VERSION "dbc-export 1 2026.26.6.5"

NS_ :

BS_:

BU_: APB APP APS DAS EPAS3S ESP GTW IBST PARK RADC RCM RCM2 RCM3 TPMS TRCM USM

BO_ 1486 PARK_alertLog: 8 PARK
 SG_ PARK_alertID M : 0|7@1+ (1,0) [0|127] "" Vector__XXX
 SG_ PARK_alertState : 15|1@1+ (1,0) [0|1] "" Vector__XXX
 SG_ PARK_sw001_sensorTemperature m1 : 16|16@1+ (0.1,-40) [-40|6513.5] "deg" Vector__XXX
 SG_ PARK_sw002_membraneDisconct m2 : 16|1@1+ (1,0) [0|1] "" Vector__XXX
 SG_ PARK_sw002_dampResistorFail m2 : 17|1@1+ (1,0) [0|1] "" Vector__XXX
 SG_ PARK_sw002_resonanceDrift m2 : 18|1@1+ (1,0) [0|1] "" Vector__XXX
 SG_ PARK_sw002_sensorCRC m2 : 19|1@1+ (1,0) [0|1] "" Vector__XXX
 SG_ PARK_sw002_recieveFailure m2 : 20|1@1+ (1,0) [0|1] "" Vector__XXX
 SG_ PARK_sw002_diagnosticTransferErr m2 : 21|1@1+ (1,0) [0|1] "" Vector__XXX
 SG_ PARK_sw003_linError m3 : 16|1@1+ (1,0) [0|1] "" Vector__XXX
 SG_ PARK_sw003_linBusError m3 : 17|1@1+ (1,0) [0|1] "" Vector__XXX
 SG_ PARK_sw003_linFrameCountError m3 : 18|1@1+ (1,0) [0|1] "" Vector__XXX
 SG_ PARK_sw004_reverbPeriod m4 : 16|16@1+ (1,0) [0|65535] "microseconds" Vector__XXX
 SG_ PARK_sw004_reverbTime m4 : 32|16@1+ (1,0) [0|65535] "microseconds" Vector__XXX
 SG_ PARK_sw004_highAttenTime m4 : 48|1@1+ (1,0) [0|1] "" Vector__XXX
 SG_ PARK_sw004_closeConstEcho m4 : 49|1@1+ (1,0) [0|1] "" Vector__XXX
 SG_ PARK_sw004_lowAttenTime m4 : 50|1@1+ (1,0) [0|1] "" Vector__XXX
 SG_ PARK_sw004_attenTimeJitter m4 : 51|1@1+ (1,0) [0|1] "" Vector__XXX
 SG_ PARK_sw004_reverbFreqJitter m4 : 52|1@1+ (1,0) [0|1] "" Vector__XXX
 SG_ PARK_sw006_sensorTemperature m6 : 16|16@1+ (0.1,-40) [-40|6513.5] "deg" Vector__XXX
 SG_ PARK_sw007_membraneDisconct m7 : 16|1@1+ (1,0) [0|1] "" Vector__XXX
 SG_ PARK_sw007_dampResistorFail m7 : 17|1@1+ (1,0) [0|1] "" Vector__XXX
 SG_ PARK_sw007_resonanceDrift m7 : 18|1@1+ (1,0) [0|1] "" Vector__XXX
 SG_ PARK_sw007_sensorCRC m7 : 19|1@1+ (1,0) [0|1] "" Vector__XXX
 SG_ PARK_sw007_recieveFailure m7 : 20|1@1+ (1,0) [0|1] "" Vector__XXX
 SG_ PARK_sw007_diagnosticTransferErr m7 : 21|1@1+ (1,0) [0|1] "" Vector__XXX
 SG_ PARK_sw008_linError m8 : 16|1@1+ (1,0) [0|1] "" Vector__XXX
 SG_ PARK_sw008_linBusError m8 : 17|1@1+ (1,0) [0|1] "" Vector__XXX
 SG_ PARK_sw008_linFrameCountError m8 : 18|1@1+ (1,0) [0|1] "" Vector__XXX
 SG_ PARK_sw009_reverbPeriod m9 : 16|16@1+ (1,0) [0|65535] "microseconds" Vector__XXX
 SG_ PARK_sw009_reverbTime m9 : 32|16@1+ (1,0) [0|65535] "microseconds" Vector__XXX
 SG_ PARK_sw009_highAttenTime m9 : 48|1@1+ (1,0) [0|1] "" Vector__XXX
 SG_ PARK_sw009_closeConstEcho m9 : 49|1@1+ (1,0) [0|1] "" Vector__XXX
 SG_ PARK_sw009_lowAttenTime m9 : 50|1@1+ (1,0) [0|1] "" Vector__XXX
 SG_ PARK_sw009_attenTimeJitter m9 : 51|1@1+ (1,0) [0|1] "" Vector__XXX
 SG_ PARK_sw009_reverbFreqJitter m9 : 52|1@1+ (1,0) [0|1] "" Vector__XXX
 SG_ PARK_sw011_sensorTemperature m11 : 16|16@1+ (0.1,-40) [-40|6513.5] "deg" Vector__XXX
 SG_ PARK_sw012_membraneDisconct m12 : 16|1@1+ (1,0) [0|1] "" Vector__XXX
 SG_ PARK_sw012_dampResistorFail m12 : 17|1@1+ (1,0) [0|1] "" Vector__XXX
 SG_ PARK_sw012_resonanceDrift m12 : 18|1@1+ (1,0) [0|1] "" Vector__XXX
 SG_ PARK_sw012_sensorCRC m12 : 19|1@1+ (1,0) [0|1] "" Vector__XXX
 SG_ PARK_sw012_recieveFailure m12 : 20|1@1+ (1,0) [0|1] "" Vector__XXX
 SG_ PARK_sw012_diagnosticTransferErr m12 : 21|1@1+ (1,0) [0|1] "" Vector__XXX
 SG_ PARK_sw013_linError m13 : 16|1@1+ (1,0) [0|1] "" Vector__XXX
 SG_ PARK_sw013_linBusError m13 : 17|1@1+ (1,0) [0|1] "" Vector__XXX
 SG_ PARK_sw013_linFrameCountError m13 : 18|1@1+ (1,0) [0|1] "" Vector__XXX
 SG_ PARK_sw014_reverbPeriod m14 : 16|16@1+ (1,0) [0|65535] "microseconds" Vector__XXX
 SG_ PARK_sw014_reverbTime m14 : 32|16@1+ (1,0) [0|65535] "microseconds" Vector__XXX
 SG_ PARK_sw014_highAttenTime m14 : 48|1@1+ (1,0) [0|1] "" Vector__XXX
 SG_ PARK_sw014_closeConstEcho m14 : 49|1@1+ (1,0) [0|1] "" Vector__XXX
 SG_ PARK_sw014_lowAttenTime m14 : 50|1@1+ (1,0) [0|1] "" Vector__XXX
 SG_ PARK_sw014_attenTimeJitter m14 : 51|1@1+ (1,0) [0|1] "" Vector__XXX
 SG_ PARK_sw014_reverbFreqJitter m14 : 52|1@1+ (1,0) [0|1] "" Vector__XXX
 SG_ PARK_sw016_sensorTemperature m16 : 16|16@1+ (0.1,-40) [-40|6513.5] "deg" Vector__XXX
 SG_ PARK_sw017_membraneDisconct m17 : 16|1@1+ (1,0) [0|1] "" Vector__XXX
 SG_ PARK_sw017_dampResistorFail m17 : 17|1@1+ (1,0) [0|1] "" Vector__XXX
 SG_ PARK_sw017_resonanceDrift m17 : 18|1@1+ (1,0) [0|1] "" Vector__XXX
 SG_ PARK_sw017_sensorCRC m17 : 19|1@1+ (1,0) [0|1] "" Vector__XXX
 SG_ PARK_sw017_recieveFailure m17 : 20|1@1+ (1,0) [0|1] "" Vector__XXX
 SG_ PARK_sw017_diagnosticTransferErr m17 : 21|1@1+ (1,0) [0|1] "" Vector__XXX
 SG_ PARK_sw018_linError m18 : 16|1@1+ (1,0) [0|1] "" Vector__XXX
 SG_ PARK_sw018_linBusError m18 : 17|1@1+ (1,0) [0|1] "" Vector__XXX
 SG_ PARK_sw018_linFrameCountError m18 : 18|1@1+ (1,0) [0|1] "" Vector__XXX
 SG_ PARK_sw019_reverbPeriod m19 : 16|16@1+ (1,0) [0|65535] "microseconds" Vector__XXX
 SG_ PARK_sw019_reverbTime m19 : 32|16@1+ (1,0) [0|65535] "microseconds" Vector__XXX
 SG_ PARK_sw019_highAttenTime m19 : 48|1@1+ (1,0) [0|1] "" Vector__XXX
 SG_ PARK_sw019_closeConstEcho m19 : 49|1@1+ (1,0) [0|1] "" Vector__XXX
 SG_ PARK_sw019_lowAttenTime m19 : 50|1@1+ (1,0) [0|1] "" Vector__XXX
 SG_ PARK_sw019_attenTimeJitter m19 : 51|1@1+ (1,0) [0|1] "" Vector__XXX
 SG_ PARK_sw019_reverbFreqJitter m19 : 52|1@1+ (1,0) [0|1] "" Vector__XXX
 SG_ PARK_sw021_sensorTemperature m21 : 16|16@1+ (0.1,-40) [-40|6513.5] "deg" Vector__XXX
 SG_ PARK_sw022_membraneDisconct m22 : 16|1@1+ (1,0) [0|1] "" Vector__XXX
 SG_ PARK_sw022_dampResistorFail m22 : 17|1@1+ (1,0) [0|1] "" Vector__XXX
 SG_ PARK_sw022_resonanceDrift m22 : 18|1@1+ (1,0) [0|1] "" Vector__XXX
 SG_ PARK_sw022_sensorCRC m22 : 19|1@1+ (1,0) [0|1] "" Vector__XXX
 SG_ PARK_sw022_recieveFailure m22 : 20|1@1+ (1,0) [0|1] "" Vector__XXX
 SG_ PARK_sw022_diagnosticTransferErr m22 : 21|1@1+ (1,0) [0|1] "" Vector__XXX
 SG_ PARK_sw023_linError m23 : 16|1@1+ (1,0) [0|1] "" Vector__XXX
 SG_ PARK_sw023_linBusError m23 : 17|1@1+ (1,0) [0|1] "" Vector__XXX
 SG_ PARK_sw023_linFrameCountError m23 : 18|1@1+ (1,0) [0|1] "" Vector__XXX
 SG_ PARK_sw024_reverbPeriod m24 : 16|16@1+ (1,0) [0|65535] "microseconds" Vector__XXX
 SG_ PARK_sw024_reverbTime m24 : 32|16@1+ (1,0) [0|65535] "microseconds" Vector__XXX
 SG_ PARK_sw024_highAttenTime m24 : 48|1@1+ (1,0) [0|1] "" Vector__XXX
 SG_ PARK_sw024_closeConstEcho m24 : 49|1@1+ (1,0) [0|1] "" Vector__XXX
 SG_ PARK_sw024_lowAttenTime m24 : 50|1@1+ (1,0) [0|1] "" Vector__XXX
 SG_ PARK_sw024_attenTimeJitter m24 : 51|1@1+ (1,0) [0|1] "" Vector__XXX
 SG_ PARK_sw024_reverbFreqJitter m24 : 52|1@1+ (1,0) [0|1] "" Vector__XXX
 SG_ PARK_sw026_sensorTemperature m26 : 16|16@1+ (0.1,-40) [-40|6513.5] "deg" Vector__XXX
 SG_ PARK_sw027_membraneDisconct m27 : 16|1@1+ (1,0) [0|1] "" Vector__XXX
 SG_ PARK_sw027_dampResistorFail m27 : 17|1@1+ (1,0) [0|1] "" Vector__XXX
 SG_ PARK_sw027_resonanceDrift m27 : 18|1@1+ (1,0) [0|1] "" Vector__XXX
 SG_ PARK_sw027_sensorCRC m27 : 19|1@1+ (1,0) [0|1] "" Vector__XXX
 SG_ PARK_sw027_recieveFailure m27 : 20|1@1+ (1,0) [0|1] "" Vector__XXX
 SG_ PARK_sw027_diagnosticTransferErr m27 : 21|1@1+ (1,0) [0|1] "" Vector__XXX
 SG_ PARK_sw028_linError m28 : 16|1@1+ (1,0) [0|1] "" Vector__XXX
 SG_ PARK_sw028_linBusError m28 : 17|1@1+ (1,0) [0|1] "" Vector__XXX
 SG_ PARK_sw028_linFrameCountError m28 : 18|1@1+ (1,0) [0|1] "" Vector__XXX
 SG_ PARK_sw029_reverbPeriod m29 : 16|16@1+ (1,0) [0|65535] "microseconds" Vector__XXX
 SG_ PARK_sw029_reverbTime m29 : 32|16@1+ (1,0) [0|65535] "microseconds" Vector__XXX
 SG_ PARK_sw029_highAttenTime m29 : 48|1@1+ (1,0) [0|1] "" Vector__XXX
 SG_ PARK_sw029_closeConstEcho m29 : 49|1@1+ (1,0) [0|1] "" Vector__XXX
 SG_ PARK_sw029_lowAttenTime m29 : 50|1@1+ (1,0) [0|1] "" Vector__XXX
 SG_ PARK_sw029_attenTimeJitter m29 : 51|1@1+ (1,0) [0|1] "" Vector__XXX
 SG_ PARK_sw029_reverbFreqJitter m29 : 52|1@1+ (1,0) [0|1] "" Vector__XXX
 SG_ PARK_sw031_sensorTemperature m31 : 16|16@1+ (0.1,-40) [-40|6513.5] "deg" Vector__XXX
 SG_ PARK_sw032_membraneDisconct m32 : 16|1@1+ (1,0) [0|1] "" Vector__XXX
 SG_ PARK_sw032_dampResistorFail m32 : 17|1@1+ (1,0) [0|1] "" Vector__XXX
 SG_ PARK_sw032_resonanceDrift m32 : 18|1@1+ (1,0) [0|1] "" Vector__XXX
 SG_ PARK_sw032_sensorCRC m32 : 19|1@1+ (1,0) [0|1] "" Vector__XXX
 SG_ PARK_sw032_recieveFailure m32 : 20|1@1+ (1,0) [0|1] "" Vector__XXX
 SG_ PARK_sw032_diagnosticTransferErr m32 : 21|1@1+ (1,0) [0|1] "" Vector__XXX
 SG_ PARK_sw033_linError m33 : 16|1@1+ (1,0) [0|1] "" Vector__XXX
 SG_ PARK_sw033_linBusError m33 : 17|1@1+ (1,0) [0|1] "" Vector__XXX
 SG_ PARK_sw033_linFrameCountError m33 : 18|1@1+ (1,0) [0|1] "" Vector__XXX
 SG_ PARK_sw034_reverbPeriod m34 : 16|16@1+ (1,0) [0|65535] "microseconds" Vector__XXX
 SG_ PARK_sw034_reverbTime m34 : 32|16@1+ (1,0) [0|65535] "microseconds" Vector__XXX
 SG_ PARK_sw034_highAttenTime m34 : 48|1@1+ (1,0) [0|1] "" Vector__XXX
 SG_ PARK_sw034_closeConstEcho m34 : 49|1@1+ (1,0) [0|1] "" Vector__XXX
 SG_ PARK_sw034_lowAttenTime m34 : 50|1@1+ (1,0) [0|1] "" Vector__XXX
 SG_ PARK_sw034_attenTimeJitter m34 : 51|1@1+ (1,0) [0|1] "" Vector__XXX
 SG_ PARK_sw034_reverbFreqJitter m34 : 52|1@1+ (1,0) [0|1] "" Vector__XXX
 SG_ PARK_sw036_sensorTemperature m36 : 16|16@1+ (0.1,-40) [-40|6513.5] "deg" Vector__XXX
 SG_ PARK_sw037_membraneDisconct m37 : 16|1@1+ (1,0) [0|1] "" Vector__XXX
 SG_ PARK_sw037_dampResistorFail m37 : 17|1@1+ (1,0) [0|1] "" Vector__XXX
 SG_ PARK_sw037_resonanceDrift m37 : 18|1@1+ (1,0) [0|1] "" Vector__XXX
 SG_ PARK_sw037_sensorCRC m37 : 19|1@1+ (1,0) [0|1] "" Vector__XXX
 SG_ PARK_sw037_recieveFailure m37 : 20|1@1+ (1,0) [0|1] "" Vector__XXX
 SG_ PARK_sw037_diagnosticTransferErr m37 : 21|1@1+ (1,0) [0|1] "" Vector__XXX
 SG_ PARK_sw038_linError m38 : 16|1@1+ (1,0) [0|1] "" Vector__XXX
 SG_ PARK_sw038_linBusError m38 : 17|1@1+ (1,0) [0|1] "" Vector__XXX
 SG_ PARK_sw038_linFrameCountError m38 : 18|1@1+ (1,0) [0|1] "" Vector__XXX
 SG_ PARK_sw039_reverbPeriod m39 : 16|16@1+ (1,0) [0|65535] "microseconds" Vector__XXX
 SG_ PARK_sw039_reverbTime m39 : 32|16@1+ (1,0) [0|65535] "microseconds" Vector__XXX
 SG_ PARK_sw039_highAttenTime m39 : 48|1@1+ (1,0) [0|1] "" Vector__XXX
 SG_ PARK_sw039_closeConstEcho m39 : 49|1@1+ (1,0) [0|1] "" Vector__XXX
 SG_ PARK_sw039_lowAttenTime m39 : 50|1@1+ (1,0) [0|1] "" Vector__XXX
 SG_ PARK_sw039_attenTimeJitter m39 : 51|1@1+ (1,0) [0|1] "" Vector__XXX
 SG_ PARK_sw039_reverbFreqJitter m39 : 52|1@1+ (1,0) [0|1] "" Vector__XXX
 SG_ PARK_sw041_sensorTemperature m41 : 16|16@1+ (0.1,-40) [-40|6513.5] "deg" Vector__XXX
 SG_ PARK_sw042_membraneDisconct m42 : 16|1@1+ (1,0) [0|1] "" Vector__XXX
 SG_ PARK_sw042_dampResistorFail m42 : 17|1@1+ (1,0) [0|1] "" Vector__XXX
 SG_ PARK_sw042_resonanceDrift m42 : 18|1@1+ (1,0) [0|1] "" Vector__XXX
 SG_ PARK_sw042_sensorCRC m42 : 19|1@1+ (1,0) [0|1] "" Vector__XXX
 SG_ PARK_sw042_recieveFailure m42 : 20|1@1+ (1,0) [0|1] "" Vector__XXX
 SG_ PARK_sw042_diagnosticTransferErr m42 : 21|1@1+ (1,0) [0|1] "" Vector__XXX
 SG_ PARK_sw043_linError m43 : 16|1@1+ (1,0) [0|1] "" Vector__XXX
 SG_ PARK_sw043_linBusError m43 : 17|1@1+ (1,0) [0|1] "" Vector__XXX
 SG_ PARK_sw043_linFrameCountError m43 : 18|1@1+ (1,0) [0|1] "" Vector__XXX
 SG_ PARK_sw044_reverbPeriod m44 : 16|16@1+ (1,0) [0|65535] "microseconds" Vector__XXX
 SG_ PARK_sw044_reverbTime m44 : 32|16@1+ (1,0) [0|65535] "microseconds" Vector__XXX
 SG_ PARK_sw044_highAttenTime m44 : 48|1@1+ (1,0) [0|1] "" Vector__XXX
 SG_ PARK_sw044_closeConstEcho m44 : 49|1@1+ (1,0) [0|1] "" Vector__XXX
 SG_ PARK_sw044_lowAttenTime m44 : 50|1@1+ (1,0) [0|1] "" Vector__XXX
 SG_ PARK_sw044_attenTimeJitter m44 : 51|1@1+ (1,0) [0|1] "" Vector__XXX
 SG_ PARK_sw044_reverbFreqJitter m44 : 52|1@1+ (1,0) [0|1] "" Vector__XXX
 SG_ PARK_sw046_sensorTemperature m46 : 16|16@1+ (0.1,-40) [-40|6513.5] "deg" Vector__XXX
 SG_ PARK_sw047_membraneDisconct m47 : 16|1@1+ (1,0) [0|1] "" Vector__XXX
 SG_ PARK_sw047_dampResistorFail m47 : 17|1@1+ (1,0) [0|1] "" Vector__XXX
 SG_ PARK_sw047_resonanceDrift m47 : 18|1@1+ (1,0) [0|1] "" Vector__XXX
 SG_ PARK_sw047_sensorCRC m47 : 19|1@1+ (1,0) [0|1] "" Vector__XXX
 SG_ PARK_sw047_recieveFailure m47 : 20|1@1+ (1,0) [0|1] "" Vector__XXX
 SG_ PARK_sw047_diagnosticTransferErr m47 : 21|1@1+ (1,0) [0|1] "" Vector__XXX
 SG_ PARK_sw048_linError m48 : 16|1@1+ (1,0) [0|1] "" Vector__XXX
 SG_ PARK_sw048_linBusError m48 : 17|1@1+ (1,0) [0|1] "" Vector__XXX
 SG_ PARK_sw048_linFrameCountError m48 : 18|1@1+ (1,0) [0|1] "" Vector__XXX
 SG_ PARK_sw049_reverbPeriod m49 : 16|16@1+ (1,0) [0|65535] "microseconds" Vector__XXX
 SG_ PARK_sw049_reverbTime m49 : 32|16@1+ (1,0) [0|65535] "microseconds" Vector__XXX
 SG_ PARK_sw049_highAttenTime m49 : 48|1@1+ (1,0) [0|1] "" Vector__XXX
 SG_ PARK_sw049_closeConstEcho m49 : 49|1@1+ (1,0) [0|1] "" Vector__XXX
 SG_ PARK_sw049_lowAttenTime m49 : 50|1@1+ (1,0) [0|1] "" Vector__XXX
 SG_ PARK_sw049_attenTimeJitter m49 : 51|1@1+ (1,0) [0|1] "" Vector__XXX
 SG_ PARK_sw049_reverbFreqJitter m49 : 52|1@1+ (1,0) [0|1] "" Vector__XXX
 SG_ PARK_sw051_sensorTemperature m51 : 16|16@1+ (0.1,-40) [-40|6513.5] "deg" Vector__XXX
 SG_ PARK_sw052_membraneDisconct m52 : 16|1@1+ (1,0) [0|1] "" Vector__XXX
 SG_ PARK_sw052_dampResistorFail m52 : 17|1@1+ (1,0) [0|1] "" Vector__XXX
 SG_ PARK_sw052_resonanceDrift m52 : 18|1@1+ (1,0) [0|1] "" Vector__XXX
 SG_ PARK_sw052_sensorCRC m52 : 19|1@1+ (1,0) [0|1] "" Vector__XXX
 SG_ PARK_sw052_recieveFailure m52 : 20|1@1+ (1,0) [0|1] "" Vector__XXX
 SG_ PARK_sw052_diagnosticTransferErr m52 : 21|1@1+ (1,0) [0|1] "" Vector__XXX
 SG_ PARK_sw053_linError m53 : 16|1@1+ (1,0) [0|1] "" Vector__XXX
 SG_ PARK_sw053_linBusError m53 : 17|1@1+ (1,0) [0|1] "" Vector__XXX
 SG_ PARK_sw053_linFrameCountError m53 : 18|1@1+ (1,0) [0|1] "" Vector__XXX
 SG_ PARK_sw054_reverbPeriod m54 : 16|16@1+ (1,0) [0|65535] "microseconds" Vector__XXX
 SG_ PARK_sw054_reverbTime m54 : 32|16@1+ (1,0) [0|65535] "microseconds" Vector__XXX
 SG_ PARK_sw054_highAttenTime m54 : 48|1@1+ (1,0) [0|1] "" Vector__XXX
 SG_ PARK_sw054_closeConstEcho m54 : 49|1@1+ (1,0) [0|1] "" Vector__XXX
 SG_ PARK_sw054_lowAttenTime m54 : 50|1@1+ (1,0) [0|1] "" Vector__XXX
 SG_ PARK_sw054_attenTimeJitter m54 : 51|1@1+ (1,0) [0|1] "" Vector__XXX
 SG_ PARK_sw054_reverbFreqJitter m54 : 52|1@1+ (1,0) [0|1] "" Vector__XXX
 SG_ PARK_sw056_sensorTemperature m56 : 16|16@1+ (0.1,-40) [-40|6513.5] "deg" Vector__XXX
 SG_ PARK_sw057_membraneDisconct m57 : 16|1@1+ (1,0) [0|1] "" Vector__XXX
 SG_ PARK_sw057_dampResistorFail m57 : 17|1@1+ (1,0) [0|1] "" Vector__XXX
 SG_ PARK_sw057_resonanceDrift m57 : 18|1@1+ (1,0) [0|1] "" Vector__XXX
 SG_ PARK_sw057_sensorCRC m57 : 19|1@1+ (1,0) [0|1] "" Vector__XXX
 SG_ PARK_sw057_recieveFailure m57 : 20|1@1+ (1,0) [0|1] "" Vector__XXX
 SG_ PARK_sw057_diagnosticTransferErr m57 : 21|1@1+ (1,0) [0|1] "" Vector__XXX
 SG_ PARK_sw058_linError m58 : 16|1@1+ (1,0) [0|1] "" Vector__XXX
 SG_ PARK_sw058_linBusError m58 : 17|1@1+ (1,0) [0|1] "" Vector__XXX
 SG_ PARK_sw058_linFrameCountError m58 : 18|1@1+ (1,0) [0|1] "" Vector__XXX
 SG_ PARK_sw059_reverbPeriod m59 : 16|16@1+ (1,0) [0|65535] "microseconds" Vector__XXX
 SG_ PARK_sw059_reverbTime m59 : 32|16@1+ (1,0) [0|65535] "microseconds" Vector__XXX
 SG_ PARK_sw059_highAttenTime m59 : 48|1@1+ (1,0) [0|1] "" Vector__XXX
 SG_ PARK_sw059_closeConstEcho m59 : 49|1@1+ (1,0) [0|1] "" Vector__XXX
 SG_ PARK_sw059_lowAttenTime m59 : 50|1@1+ (1,0) [0|1] "" Vector__XXX
 SG_ PARK_sw059_attenTimeJitter m59 : 51|1@1+ (1,0) [0|1] "" Vector__XXX
 SG_ PARK_sw059_reverbFreqJitter m59 : 52|1@1+ (1,0) [0|1] "" Vector__XXX
 SG_ PARK_sw061_voltage m61 : 16|16@1+ (0.1,0) [0|6553.5] "volts" Vector__XXX
 SG_ PARK_sw063_voltage m63 : 16|16@1+ (0.1,0) [0|6553.5] "volts" Vector__XXX
 SG_ PARK_sw064_faultCode m64 : 16|8@1+ (1,0) [0|255] "" Vector__XXX
 SG_ PARK_sw065_expectedCRC m65 : 16|16@1+ (1,0) [0|65535] "" Vector__XXX
 SG_ PARK_sw065_calculatedCRC m65 : 32|16@1+ (1,0) [0|65535] "" Vector__XXX
 SG_ PARK_sw066_placeHolder m66 : 16|1@1+ (1,0) [0|1] "" Vector__XXX
 SG_ PARK_sw068_placeHolder m68 : 16|1@1+ (1,0) [0|1] "" Vector__XXX
 SG_ PARK_sw069_messageID m69 : 16|16@1+ (1,0) [0|65535] "" Vector__XXX
 SG_ PARK_sw070_messageID m70 : 16|16@1+ (1,0) [0|65535] "" Vector__XXX
 SG_ PARK_sw071_messageID m71 : 16|16@1+ (1,0) [0|65535] "" Vector__XXX
 SG_ PARK_sw072_messageID m72 : 16|16@1+ (1,0) [0|65535] "" Vector__XXX
 SG_ PARK_sw073_messageID m73 : 16|16@1+ (1,0) [0|65535] "" Vector__XXX
 SG_ PARK_sw074_messageID m74 : 16|16@1+ (1,0) [0|65535] "" Vector__XXX
 SG_ PARK_sw075_messageID m75 : 16|16@1+ (1,0) [0|65535] "" Vector__XXX
 SG_ PARK_sw076_messageID m76 : 16|16@1+ (1,0) [0|65535] "" Vector__XXX
 SG_ PARK_sw077_errorExp m77 : 16|8@1+ (1,0) [0|255] "" Vector__XXX
 SG_ PARK_sw077_errorRx m77 : 24|8@1+ (1,0) [0|255] "" Vector__XXX
 SG_ PARK_sw077_messageID m77 : 32|12@1+ (1,0) [0|4095] "" Vector__XXX
 SG_ PARK_sw077_errorType m77 : 44|3@1+ (1,0) [0|7] "" Vector__XXX
 SG_ PARK_sw078_errorExp m78 : 16|8@1+ (1,0) [0|255] "" Vector__XXX
 SG_ PARK_sw078_errorRx m78 : 24|8@1+ (1,0) [0|255] "" Vector__XXX
 SG_ PARK_sw078_messageID m78 : 32|12@1+ (1,0) [0|4095] "" Vector__XXX
 SG_ PARK_sw078_errorType m78 : 44|3@1+ (1,0) [0|7] "" Vector__XXX
 SG_ PARK_sw079_errorExp m79 : 16|8@1+ (1,0) [0|255] "" Vector__XXX
 SG_ PARK_sw079_errorRx m79 : 24|8@1+ (1,0) [0|255] "" Vector__XXX
 SG_ PARK_sw079_messageID m79 : 32|12@1+ (1,0) [0|4095] "" Vector__XXX
 SG_ PARK_sw079_errorType m79 : 44|3@1+ (1,0) [0|7] "" Vector__XXX
 SG_ PARK_sw080_errorExp m80 : 16|8@1+ (1,0) [0|255] "" Vector__XXX
 SG_ PARK_sw080_errorRx m80 : 24|8@1+ (1,0) [0|255] "" Vector__XXX
 SG_ PARK_sw080_messageID m80 : 32|12@1+ (1,0) [0|4095] "" Vector__XXX
 SG_ PARK_sw080_errorType m80 : 44|3@1+ (1,0) [0|7] "" Vector__XXX
 SG_ PARK_sw081_errorExp m81 : 16|8@1+ (1,0) [0|255] "" Vector__XXX
 SG_ PARK_sw081_errorRx m81 : 24|8@1+ (1,0) [0|255] "" Vector__XXX
 SG_ PARK_sw081_messageID m81 : 32|12@1+ (1,0) [0|4095] "" Vector__XXX
 SG_ PARK_sw081_errorType m81 : 44|3@1+ (1,0) [0|7] "" Vector__XXX
 SG_ PARK_sw082_errorExp m82 : 16|8@1+ (1,0) [0|255] "" Vector__XXX
 SG_ PARK_sw082_errorRx m82 : 24|8@1+ (1,0) [0|255] "" Vector__XXX
 SG_ PARK_sw082_messageID m82 : 32|12@1+ (1,0) [0|4095] "" Vector__XXX
 SG_ PARK_sw082_errorType m82 : 44|3@1+ (1,0) [0|7] "" Vector__XXX
 SG_ PARK_sw083_errorExp m83 : 16|8@1+ (1,0) [0|255] "" Vector__XXX
 SG_ PARK_sw083_errorRx m83 : 24|8@1+ (1,0) [0|255] "" Vector__XXX
 SG_ PARK_sw083_messageID m83 : 32|12@1+ (1,0) [0|4095] "" Vector__XXX
 SG_ PARK_sw083_errorType m83 : 44|3@1+ (1,0) [0|7] "" Vector__XXX
 SG_ PARK_sw084_errorExp m84 : 16|8@1+ (1,0) [0|255] "" Vector__XXX
 SG_ PARK_sw084_errorRx m84 : 24|8@1+ (1,0) [0|255] "" Vector__XXX
 SG_ PARK_sw084_messageID m84 : 32|12@1+ (1,0) [0|4095] "" Vector__XXX
 SG_ PARK_sw084_errorType m84 : 44|3@1+ (1,0) [0|7] "" Vector__XXX
 SG_ PARK_sw086_writeRetryCounter m86 : 16|8@1+ (1,0) [0|255] "" Vector__XXX
 SG_ PARK_sw086_readRetryCounter m86 : 24|8@1+ (1,0) [0|255] "" Vector__XXX
 SG_ PARK_sw086_currentErrorCode m86 : 32|8@1+ (1,0) [0|255] "" Vector__XXX
 SG_ PARK_sw087_s1_sensorType m87 : 16|2@1+ (1,0) [0|2] "" Vector__XXX
 SG_ PARK_sw087_s2_sensorType m87 : 18|2@1+ (1,0) [0|2] "" Vector__XXX
 SG_ PARK_sw087_s3_sensorType m87 : 20|2@1+ (1,0) [0|2] "" Vector__XXX
 SG_ PARK_sw087_s4_sensorType m87 : 22|2@1+ (1,0) [0|2] "" Vector__XXX
 SG_ PARK_sw087_s5_sensorType m87 : 24|2@1+ (1,0) [0|2] "" Vector__XXX
 SG_ PARK_sw087_s6_sensorType m87 : 26|2@1+ (1,0) [0|2] "" Vector__XXX
 SG_ PARK_sw087_s7_sensorType m87 : 28|2@1+ (1,0) [0|2] "" Vector__XXX
 SG_ PARK_sw087_s8_sensorType m87 : 30|2@1+ (1,0) [0|2] "" Vector__XXX
 SG_ PARK_sw087_s9_sensorType m87 : 32|2@1+ (1,0) [0|2] "" Vector__XXX
 SG_ PARK_sw087_s10_sensorType m87 : 34|2@1+ (1,0) [0|2] "" Vector__XXX
 SG_ PARK_sw087_s11_sensorType m87 : 36|2@1+ (1,0) [0|2] "" Vector__XXX
 SG_ PARK_sw087_s12_sensorType m87 : 38|2@1+ (1,0) [0|2] "" Vector__XXX

BO_ 806 PARK_info: 8 PARK
 SG_ PARK_infoIndex M : 0|8@1+ (1,0) [0|255] "" Vector__XXX
 SG_ PARK_infoBuildType m10 : 8|8@1+ (1,0) [0|255] "" Vector__XXX
 SG_ PARK_infoComponentID m10 : 48|16@1+ (1,0) [0|65535] "" Vector__XXX
 SG_ PARK_infoPcbaID m11 : 16|8@1+ (1,0) [0|255] "" Vector__XXX
 SG_ PARK_infoAssemblyID m11 : 24|8@1+ (1,0) [0|255] "" Vector__XXX
 SG_ PARK_infoUsageID m11 : 32|16@1+ (1,0) [0|65535] "" Vector__XXX
 SG_ PARK_infoApplicationCRC m13 : 32|32@1+ (1,0) [0|4294967295] "" Vector__XXX
 SG_ PARK_infoBootUdsProtoVersion m20 : 8|8@1+ (1,0) [0|255] "" Vector__XXX
 SG_ PARK_infoBootloaderCRC m20 : 32|32@1+ (1,0) [0|4294967295] "" Vector__XXX

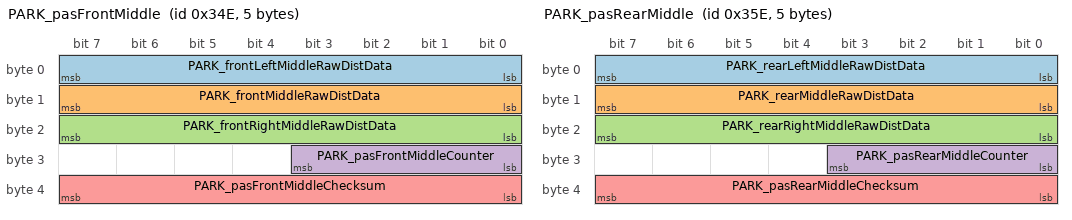
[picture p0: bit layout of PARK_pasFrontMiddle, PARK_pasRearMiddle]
BO_ 846 PARK_pasFrontMiddle: 5 PARK
 SG_ PARK_frontLeftMiddleRawDistData : 0|8@1+ (1,0) [0|254] "cm" Vector__XXX
 SG_ PARK_frontMiddleRawDistData : 8|8@1+ (1,0) [0|254] "cm" Vector__XXX
 SG_ PARK_frontRightMiddleRawDistData : 16|8@1+ (1,0) [0|254] "cm" Vector__XXX
 SG_ PARK_pasFrontMiddleCounter : 24|4@1+ (1,0) [0|15] "" Vector__XXX
 SG_ PARK_pasFrontMiddleChecksum : 32|8@1+ (1,0) [0|255] "" Vector__XXX

BO_ 862 PARK_pasRearMiddle: 5 PARK
 SG_ PARK_rearLeftMiddleRawDistData : 0|8@1+ (1,0) [0|254] "cm" Vector__XXX
 SG_ PARK_rearMiddleRawDistData : 8|8@1+ (1,0) [0|254] "cm" Vector__XXX
 SG_ PARK_rearRightMiddleRawDistData : 16|8@1+ (1,0) [0|254] "cm" Vector__XXX
 SG_ PARK_pasRearMiddleCounter : 24|4@1+ (1,0) [0|15] "" Vector__XXX
 SG_ PARK_pasRearMiddleChecksum : 32|8@1+ (1,0) [0|255] "" Vector__XXX

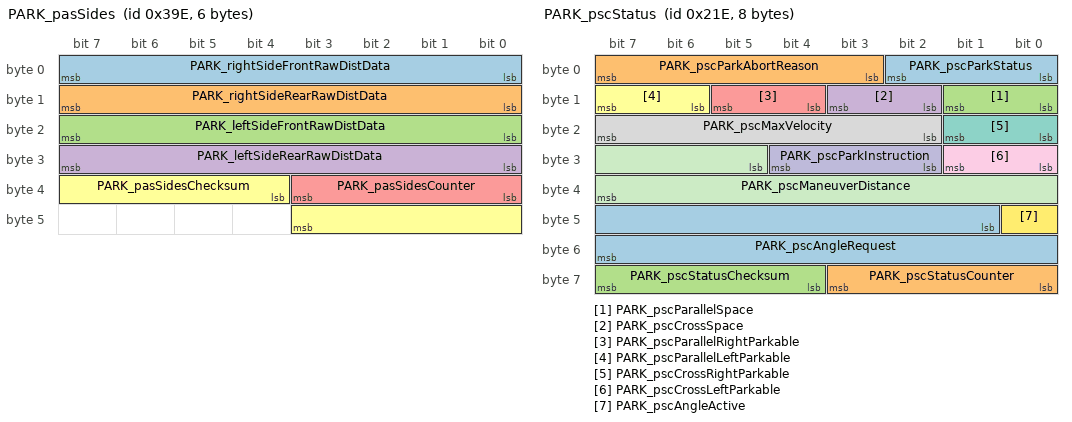
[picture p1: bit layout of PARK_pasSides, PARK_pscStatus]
BO_ 926 PARK_pasSides: 6 PARK
 SG_ PARK_rightSideFrontRawDistData : 0|8@1+ (1,0) [0|254] "cm" Vector__XXX
 SG_ PARK_rightSideRearRawDistData : 8|8@1+ (1,0) [0|254] "cm" Vector__XXX
 SG_ PARK_leftSideFrontRawDistData : 16|8@1+ (1,0) [0|254] "cm" Vector__XXX
 SG_ PARK_leftSideRearRawDistData : 24|8@1+ (1,0) [0|254] "cm" Vector__XXX
 SG_ PARK_pasSidesCounter : 32|4@1+ (1,0) [0|15] "" Vector__XXX
 SG_ PARK_pasSidesChecksum : 36|8@1+ (1,0) [0|255] "" Vector__XXX

BO_ 606 PARK_pscEnvSlot: 8 PARK
 SG_ PARK_pscEnvSlotType M : 0|2@1+ (1,0) [0|3] "" Vector__XXX
 SG_ PARK_pscLeftParallelObj1X m0 : 3|11@1+ (2,-2048) [-2048|2044] "cm" Vector__XXX
 SG_ PARK_pscLeftParallelObj1Y m0 : 14|11@1+ (2,-2048) [-2048|2044] "cm" Vector__XXX
 SG_ PARK_pscLeftParallelObj1Alpha m0 : 25|7@1+ (2,-128) [-128|124] "deg" Vector__XXX
 SG_ PARK_pscLeftParallelObj2Y m0 : 35|11@1+ (2,-2048) [-2048|2044] "cm" Vector__XXX
 SG_ PARK_pscLeftParallelObj2X m0 : 46|11@1+ (2,-2048) [-2048|2044] "cm" Vector__XXX
 SG_ PARK_pscLeftParallelObj2Alpha m0 : 57|7@1+ (2,-128) [-128|124] "deg" Vector__XXX
 SG_ PARK_pscLeftCrossObj1X m1 : 3|11@1+ (2,-2048) [-2048|2044] "cm" Vector__XXX
 SG_ PARK_pscLeftCrossObj1Y m1 : 14|11@1+ (2,-2048) [-2048|2044] "cm" Vector__XXX
 SG_ PARK_pscLeftCrossObj1Alpha m1 : 25|7@1+ (2,-128) [-128|124] "deg" Vector__XXX
 SG_ PARK_pscLeftCrossObj2Y m1 : 35|11@1+ (2,-2048) [-2048|2044] "cm" Vector__XXX
 SG_ PARK_pscLeftCrossObj2X m1 : 46|11@1+ (2,-2048) [-2048|2044] "cm" Vector__XXX
 SG_ PARK_pscLeftCrossObj2Alpha m1 : 57|7@1+ (2,-128) [-128|124] "deg" Vector__XXX
 SG_ PARK_pscRightParallelObj1X m2 : 3|11@1+ (2,-2048) [-2048|2044] "cm" Vector__XXX
 SG_ PARK_pscRightParallelObj1Y m2 : 14|11@1+ (2,-2048) [-2048|2044] "cm" Vector__XXX
 SG_ PARK_pscRightParallelObj1Alpha m2 : 25|7@1+ (2,-128) [-128|124] "deg" Vector__XXX
 SG_ PARK_pscRightParallelObj2Y m2 : 35|11@1+ (2,-2048) [-2048|2044] "cm" Vector__XXX
 SG_ PARK_pscRightParallelObj2X m2 : 46|11@1+ (2,-2048) [-2048|2044] "cm" Vector__XXX
 SG_ PARK_pscRightParallelObj2Alpha m2 : 57|7@1+ (2,-128) [-128|124] "deg" Vector__XXX
 SG_ PARK_pscRightCrossObj1X m3 : 3|11@1+ (2,-2048) [-2048|2044] "cm" Vector__XXX
 SG_ PARK_pscRightCrossObj1Y m3 : 14|11@1+ (2,-2048) [-2048|2044] "cm" Vector__XXX
 SG_ PARK_pscRightCrossObj1Alpha m3 : 25|7@1+ (2,-128) [-128|124] "deg" Vector__XXX
 SG_ PARK_pscRightCrossObj2Y m3 : 35|11@1+ (2,-2048) [-2048|2044] "cm" Vector__XXX
 SG_ PARK_pscRightCrossObj2X m3 : 46|11@1+ (2,-2048) [-2048|2044] "cm" Vector__XXX
 SG_ PARK_pscRightCrossObj2Alpha m3 : 57|7@1+ (2,-128) [-128|124] "deg" Vector__XXX

BO_ 542 PARK_pscStatus: 8 PARK
 SG_ PARK_pscParkStatus : 0|3@1+ (1,0) [0|6] "" Vector__XXX
 SG_ PARK_pscParkAbortReason : 3|5@1+ (1,0) [0|30] "" Vector__XXX
 SG_ PARK_pscParallelSpace : 8|2@1+ (1,0) [0|3] "" Vector__XXX
 SG_ PARK_pscCrossSpace : 10|2@1+ (1,0) [0|3] "" Vector__XXX
 SG_ PARK_pscParallelRightParkable : 12|2@1+ (1,0) [0|2] "" Vector__XXX
 SG_ PARK_pscParallelLeftParkable : 14|2@1+ (1,0) [0|2] "" Vector__XXX
 SG_ PARK_pscCrossRightParkable : 16|2@1+ (1,0) [0|2] "" Vector__XXX
 SG_ PARK_pscMaxVelocity : 18|6@1+ (0.1,0) [0|6.2] "kph" Vector__XXX
 SG_ PARK_pscCrossLeftParkable : 24|2@1+ (1,0) [0|2] "" Vector__XXX
 SG_ PARK_pscParkInstruction : 26|3@1+ (1,0) [0|6] "" Vector__XXX
 SG_ PARK_pscManeuverDistance : 29|11@1+ (1,0) [0|2046] "cm" Vector__XXX
 SG_ PARK_pscAngleActive : 40|1@1+ (1,0) [0|1] "" Vector__XXX
 SG_ PARK_pscAngleRequest : 41|15@1+ (0.1,-1638.4) [-1638.4|1638.3] "deg" Vector__XXX
 SG_ PARK_pscStatusCounter : 56|4@1+ (1,0) [0|15] "" Vector__XXX
 SG_ PARK_pscStatusChecksum : 60|4@1+ (1,0) [0|15] "" Vector__XXX

BO_ 590 PARK_pscVehSlot: 8 PARK
 SG_ PARK_pscVehSlotType M : 0|2@1+ (1,0) [0|3] "" Vector__XXX
 SG_ PARK_pscLeftParallelVehX m0 : 5|11@1+ (2,-2048) [-2048|2044] "cm" Vector__XXX
 SG_ PARK_pscLeftParallelVehY m0 : 16|11@1+ (2,-2048) [-2048|2044] "cm" Vector__XXX
 SG_ PARK_pscLeftParallelPsi m0 : 32|13@1+ (0.0009765625,0) [0|7.998046875] "radians" Vector__XXX
 SG_ PARK_pscLeftParallelSizeX m0 : 48|8@1+ (4,0) [0|1016] "cm" Vector__XXX
 SG_ PARK_pscLeftParallelSizeY m0 : 56|8@1+ (4,0) [0|1016] "cm" Vector__XXX
 SG_ PARK_pscLeftCrossVehX m1 : 5|11@1+ (2,-2048) [-2048|2044] "cm" Vector__XXX
 SG_ PARK_pscLeftCrossVehY m1 : 16|11@1+ (2,-2048) [-2048|2044] "cm" Vector__XXX
 SG_ PARK_pscLeftCrossPsi m1 : 32|13@1+ (0.0009765625,0) [0|7.998046875] "radians" Vector__XXX
 SG_ PARK_pscLeftCrossSizeX m1 : 48|8@1+ (4,0) [0|1016] "cm" Vector__XXX
 SG_ PARK_pscLeftCrossSizeY m1 : 56|8@1+ (4,0) [0|1016] "cm" Vector__XXX
 SG_ PARK_pscRightParallelVehX m2 : 5|11@1+ (2,-2048) [-2048|2044] "cm" Vector__XXX
 SG_ PARK_pscRightParallelVehY m2 : 16|11@1+ (2,-2048) [-2048|2044] "cm" Vector__XXX
 SG_ PARK_pscRightParallelPsi m2 : 32|13@1+ (0.0009765625,0) [0|7.998046875] "radians" Vector__XXX
 SG_ PARK_pscRightParallelSizeX m2 : 48|8@1+ (4,0) [0|1016] "cm" Vector__XXX
 SG_ PARK_pscRightParallelSizeY m2 : 56|8@1+ (4,0) [0|1016] "cm" Vector__XXX
 SG_ PARK_pscRightCrossVehX m3 : 5|11@1+ (2,-2048) [-2048|2044] "cm" Vector__XXX
 SG_ PARK_pscRightCrossVehY m3 : 16|11@1+ (2,-2048) [-2048|2044] "cm" Vector__XXX
 SG_ PARK_pscRightCrossPsi m3 : 32|13@1+ (0.0009765625,0) [0|7.998046875] "radians" Vector__XXX
 SG_ PARK_pscRightCrossSizeX m3 : 48|8@1+ (4,0) [0|1016] "cm" Vector__XXX
 SG_ PARK_pscRightCrossSizeY m3 : 56|8@1+ (4,0) [0|1016] "cm" Vector__XXX

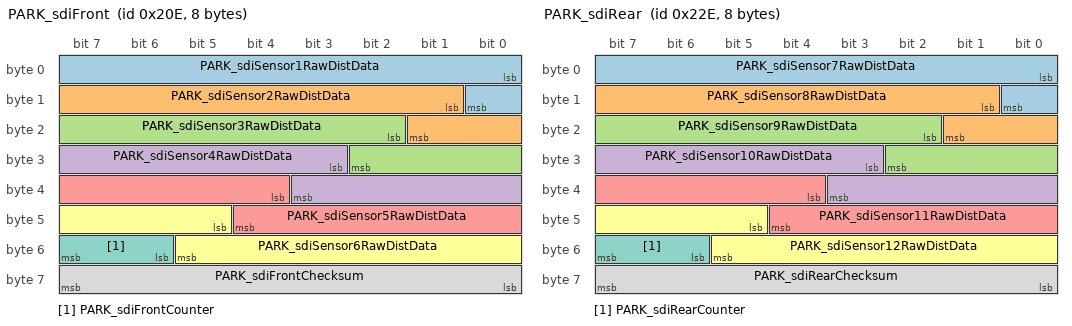
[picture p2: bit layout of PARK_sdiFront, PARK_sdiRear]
BO_ 526 PARK_sdiFront: 8 PARK
 SG_ PARK_sdiSensor1RawDistData : 0|9@1+ (1,0) [0|510] "cm" Vector__XXX
 SG_ PARK_sdiSensor2RawDistData : 9|9@1+ (1,0) [0|510] "cm" Vector__XXX
 SG_ PARK_sdiSensor3RawDistData : 18|9@1+ (1,0) [0|510] "cm" Vector__XXX
 SG_ PARK_sdiSensor4RawDistData : 27|9@1+ (1,0) [0|510] "cm" Vector__XXX
 SG_ PARK_sdiSensor5RawDistData : 36|9@1+ (1,0) [0|510] "cm" Vector__XXX
 SG_ PARK_sdiSensor6RawDistData : 45|9@1+ (1,0) [0|510] "cm" Vector__XXX
 SG_ PARK_sdiFrontCounter : 54|2@1+ (1,0) [0|3] "" Vector__XXX
 SG_ PARK_sdiFrontChecksum : 56|8@1+ (1,0) [0|255] "" Vector__XXX

BO_ 558 PARK_sdiRear: 8 PARK
 SG_ PARK_sdiSensor7RawDistData : 0|9@1+ (1,0) [0|510] "cm" Vector__XXX
 SG_ PARK_sdiSensor8RawDistData : 9|9@1+ (1,0) [0|510] "cm" Vector__XXX
 SG_ PARK_sdiSensor9RawDistData : 18|9@1+ (1,0) [0|510] "cm" Vector__XXX
 SG_ PARK_sdiSensor10RawDistData : 27|9@1+ (1,0) [0|510] "cm" Vector__XXX
 SG_ PARK_sdiSensor11RawDistData : 36|9@1+ (1,0) [0|510] "cm" Vector__XXX
 SG_ PARK_sdiSensor12RawDistData : 45|9@1+ (1,0) [0|510] "cm" Vector__XXX
 SG_ PARK_sdiRearCounter : 54|2@1+ (1,0) [0|3] "" Vector__XXX
 SG_ PARK_sdiRearChecksum : 56|8@1+ (1,0) [0|255] "" Vector__XXX

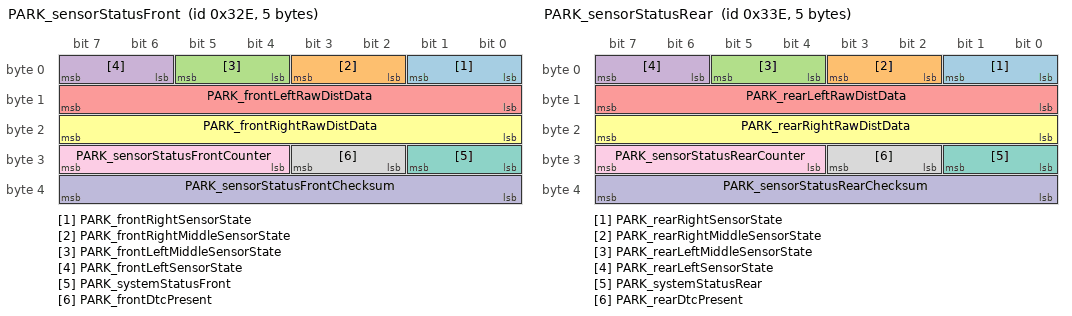
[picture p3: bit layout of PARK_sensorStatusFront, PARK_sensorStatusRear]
BO_ 814 PARK_sensorStatusFront: 5 PARK
 SG_ PARK_frontRightSensorState : 0|2@1+ (1,0) [0|2] "" Vector__XXX
 SG_ PARK_frontRightMiddleSensorState : 2|2@1+ (1,0) [0|2] "" Vector__XXX
 SG_ PARK_frontLeftMiddleSensorState : 4|2@1+ (1,0) [0|2] "" Vector__XXX
 SG_ PARK_frontLeftSensorState : 6|2@1+ (1,0) [0|2] "" Vector__XXX
 SG_ PARK_frontLeftRawDistData : 8|8@1+ (1,0) [0|254] "cm" Vector__XXX
 SG_ PARK_frontRightRawDistData : 16|8@1+ (1,0) [0|254] "cm" Vector__XXX
 SG_ PARK_systemStatusFront : 24|2@1+ (1,0) [0|2] "" Vector__XXX
 SG_ PARK_frontDtcPresent : 26|2@1+ (1,0) [0|2] "" Vector__XXX
 SG_ PARK_sensorStatusFrontCounter : 28|4@1+ (1,0) [0|15] "" Vector__XXX
 SG_ PARK_sensorStatusFrontChecksum : 32|8@1+ (1,0) [0|255] "" Vector__XXX

BO_ 830 PARK_sensorStatusRear: 5 PARK
 SG_ PARK_rearRightSensorState : 0|2@1+ (1,0) [0|2] "" Vector__XXX
 SG_ PARK_rearRightMiddleSensorState : 2|2@1+ (1,0) [0|2] "" Vector__XXX
 SG_ PARK_rearLeftMiddleSensorState : 4|2@1+ (1,0) [0|2] "" Vector__XXX
 SG_ PARK_rearLeftSensorState : 6|2@1+ (1,0) [0|2] "" Vector__XXX
 SG_ PARK_rearLeftRawDistData : 8|8@1+ (1,0) [0|254] "cm" Vector__XXX
 SG_ PARK_rearRightRawDistData : 16|8@1+ (1,0) [0|254] "cm" Vector__XXX
 SG_ PARK_systemStatusRear : 24|2@1+ (1,0) [0|2] "" Vector__XXX
 SG_ PARK_rearDtcPresent : 26|2@1+ (1,0) [0|2] "" Vector__XXX
 SG_ PARK_sensorStatusRearCounter : 28|4@1+ (1,0) [0|15] "" Vector__XXX
 SG_ PARK_sensorStatusRearChecksum : 32|8@1+ (1,0) [0|255] "" Vector__XXX

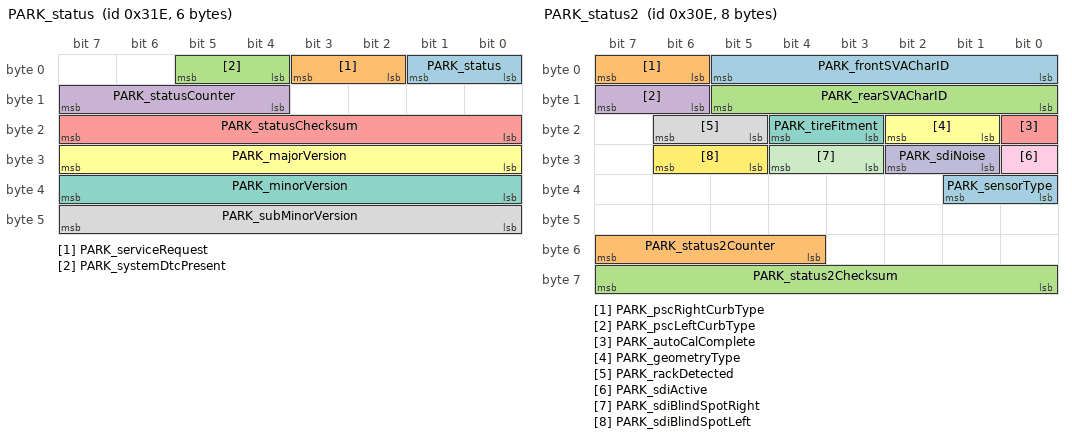
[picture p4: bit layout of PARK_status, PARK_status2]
BO_ 798 PARK_status: 6 PARK
 SG_ PARK_status : 0|2@1+ (1,0) [0|2] "" Vector__XXX
 SG_ PARK_serviceRequest : 2|2@1+ (1,0) [0|2] "" Vector__XXX
 SG_ PARK_systemDtcPresent : 4|2@1+ (1,0) [0|2] "" Vector__XXX
 SG_ PARK_statusCounter : 12|4@1+ (1,0) [0|15] "" Vector__XXX
 SG_ PARK_statusChecksum : 16|8@1+ (1,0) [0|255] "" Vector__XXX
 SG_ PARK_majorVersion : 24|8@1+ (1,0) [0|254] "" Vector__XXX
 SG_ PARK_minorVersion : 32|8@1+ (1,0) [0|254] "" Vector__XXX
 SG_ PARK_subMinorVersion : 40|8@1+ (1,0) [0|254] "" Vector__XXX

BO_ 782 PARK_status2: 8 PARK
 SG_ PARK_frontSVACharID : 0|6@1+ (1,0) [0|63] "" Vector__XXX
 SG_ PARK_pscRightCurbType : 6|2@1+ (1,0) [0|3] "" Vector__XXX
 SG_ PARK_rearSVACharID : 8|6@1+ (1,0) [0|63] "" Vector__XXX
 SG_ PARK_pscLeftCurbType : 14|2@1+ (1,0) [0|3] "" Vector__XXX
 SG_ PARK_autoCalComplete : 16|1@1+ (1,0) [0|1] "" Vector__XXX
 SG_ PARK_geometryType : 17|2@1+ (1,0) [0|3] "" Vector__XXX
 SG_ PARK_tireFitment : 19|2@1+ (1,0) [0|2] "" Vector__XXX
 SG_ PARK_rackDetected : 21|2@1+ (1,0) [0|2] "" Vector__XXX
 SG_ PARK_sdiActive : 24|1@1+ (1,0) [0|1] "" Vector__XXX
 SG_ PARK_sdiNoise : 25|2@1+ (1,0) [0|2] "" Vector__XXX
 SG_ PARK_sdiBlindSpotRight : 27|2@1+ (1,0) [0|2] "" Vector__XXX
 SG_ PARK_sdiBlindSpotLeft : 29|2@1+ (1,0) [0|2] "" Vector__XXX
 SG_ PARK_sensorType : 32|2@1+ (1,0) [0|2] "" Vector__XXX
 SG_ PARK_status2Counter : 52|4@1+ (1,0) [0|15] "" Vector__XXX
 SG_ PARK_status2Checksum : 56|8@1+ (1,0) [0|255] "" Vector__XXX

BO_ 1630 PARK_udsResponse: 8 PARK
 SG_ PARK_udsResponseData : 0|64@1+ (1,0) [0|1.84467440737e+19] "" Vector__XXX

BO_ 894 PARK_warningMatrix: 8 PARK
 SG_ PARK_matrixIndex M : 0|4@1+ (1,0) [0|15] "" Vector__XXX
 SG_ PARK_a001_s1_overTemp m0 : 4|1@1+ (1,0) [0|1] "" Vector__XXX
 SG_ PARK_a002_s1_internalFail m0 : 5|1@1+ (1,0) [0|1] "" Vector__XXX
 SG_ PARK_a003_s1_linCommError m0 : 6|1@1+ (1,0) [0|1] "" Vector__XXX
 SG_ PARK_a004_s1_blocked m0 : 7|1@1+ (1,0) [0|1] "" Vector__XXX
 SG_ PARK_a005_s1_crossTalk m0 : 8|1@1+ (1,0) [0|1] "" Vector__XXX
 SG_ PARK_a006_s2_overTemp m0 : 9|1@1+ (1,0) [0|1] "" Vector__XXX
 SG_ PARK_a007_s2_internalFail m0 : 10|1@1+ (1,0) [0|1] "" Vector__XXX
 SG_ PARK_a008_s2_linCommError m0 : 11|1@1+ (1,0) [0|1] "" Vector__XXX
 SG_ PARK_a009_s2_blocked m0 : 12|1@1+ (1,0) [0|1] "" Vector__XXX
 SG_ PARK_a010_s2_crossTalk m0 : 13|1@1+ (1,0) [0|1] "" Vector__XXX
 SG_ PARK_a011_s3_overTemp m0 : 14|1@1+ (1,0) [0|1] "" Vector__XXX
 SG_ PARK_a012_s3_internalFail m0 : 15|1@1+ (1,0) [0|1] "" Vector__XXX
 SG_ PARK_a013_s3_linCommError m0 : 16|1@1+ (1,0) [0|1] "" Vector__XXX
 SG_ PARK_a014_s3_blocked m0 : 17|1@1+ (1,0) [0|1] "" Vector__XXX
 SG_ PARK_a015_s3_crossTalk m0 : 18|1@1+ (1,0) [0|1] "" Vector__XXX
 SG_ PARK_a016_s4_overTemp m0 : 19|1@1+ (1,0) [0|1] "" Vector__XXX
 SG_ PARK_a017_s4_internalFail m0 : 20|1@1+ (1,0) [0|1] "" Vector__XXX
 SG_ PARK_a018_s4_linCommError m0 : 21|1@1+ (1,0) [0|1] "" Vector__XXX
 SG_ PARK_a019_s4_blocked m0 : 22|1@1+ (1,0) [0|1] "" Vector__XXX
 SG_ PARK_a020_s4_crossTalk m0 : 23|1@1+ (1,0) [0|1] "" Vector__XXX
 SG_ PARK_a021_s5_overTemp m0 : 24|1@1+ (1,0) [0|1] "" Vector__XXX
 SG_ PARK_a022_s5_internalFail m0 : 25|1@1+ (1,0) [0|1] "" Vector__XXX
 SG_ PARK_a023_s5_linCommError m0 : 26|1@1+ (1,0) [0|1] "" Vector__XXX
 SG_ PARK_a024_s5_blocked m0 : 27|1@1+ (1,0) [0|1] "" Vector__XXX
 SG_ PARK_a025_s5_crossTalk m0 : 28|1@1+ (1,0) [0|1] "" Vector__XXX
 SG_ PARK_a026_s6_overTemp m0 : 29|1@1+ (1,0) [0|1] "" Vector__XXX
 SG_ PARK_a027_s6_internalFail m0 : 30|1@1+ (1,0) [0|1] "" Vector__XXX
 SG_ PARK_a028_s6_linCommError m0 : 31|1@1+ (1,0) [0|1] "" Vector__XXX
 SG_ PARK_a029_s6_blocked m0 : 32|1@1+ (1,0) [0|1] "" Vector__XXX
 SG_ PARK_a030_s6_crossTalk m0 : 33|1@1+ (1,0) [0|1] "" Vector__XXX
 SG_ PARK_a031_s7_overTemp m0 : 34|1@1+ (1,0) [0|1] "" Vector__XXX
 SG_ PARK_a032_s7_internalFail m0 : 35|1@1+ (1,0) [0|1] "" Vector__XXX
 SG_ PARK_a033_s7_linCommError m0 : 36|1@1+ (1,0) [0|1] "" Vector__XXX
 SG_ PARK_a034_s7_blocked m0 : 37|1@1+ (1,0) [0|1] "" Vector__XXX
 SG_ PARK_a035_s7_crossTalk m0 : 38|1@1+ (1,0) [0|1] "" Vector__XXX
 SG_ PARK_a036_s8_overTemp m0 : 39|1@1+ (1,0) [0|1] "" Vector__XXX
 SG_ PARK_a037_s8_internalFail m0 : 40|1@1+ (1,0) [0|1] "" Vector__XXX
 SG_ PARK_a038_s8_linCommError m0 : 41|1@1+ (1,0) [0|1] "" Vector__XXX
 SG_ PARK_a039_s8_blocked m0 : 42|1@1+ (1,0) [0|1] "" Vector__XXX
 SG_ PARK_a040_s8_crossTalk m0 : 43|1@1+ (1,0) [0|1] "" Vector__XXX
 SG_ PARK_a041_s9_overTemp m0 : 44|1@1+ (1,0) [0|1] "" Vector__XXX
 SG_ PARK_a042_s9_internalFail m0 : 45|1@1+ (1,0) [0|1] "" Vector__XXX
 SG_ PARK_a043_s9_linCommError m0 : 46|1@1+ (1,0) [0|1] "" Vector__XXX
 SG_ PARK_a044_s9_blocked m0 : 47|1@1+ (1,0) [0|1] "" Vector__XXX
 SG_ PARK_a045_s9_crossTalk m0 : 48|1@1+ (1,0) [0|1] "" Vector__XXX
 SG_ PARK_a046_s10_overTemp m0 : 49|1@1+ (1,0) [0|1] "" Vector__XXX
 SG_ PARK_a047_s10_internalFail m0 : 50|1@1+ (1,0) [0|1] "" Vector__XXX
 SG_ PARK_a048_s10_linCommError m0 : 51|1@1+ (1,0) [0|1] "" Vector__XXX
 SG_ PARK_a049_s10_blocked m0 : 52|1@1+ (1,0) [0|1] "" Vector__XXX
 SG_ PARK_a050_s10_crossTalk m0 : 53|1@1+ (1,0) [0|1] "" Vector__XXX
 SG_ PARK_a051_s11_overTemp m0 : 54|1@1+ (1,0) [0|1] "" Vector__XXX
 SG_ PARK_a052_s11_internalFail m0 : 55|1@1+ (1,0) [0|1] "" Vector__XXX
 SG_ PARK_a053_s11_linCommError m0 : 56|1@1+ (1,0) [0|1] "" Vector__XXX
 SG_ PARK_a054_s11_blocked m0 : 57|1@1+ (1,0) [0|1] "" Vector__XXX
 SG_ PARK_a055_s11_crossTalk m0 : 58|1@1+ (1,0) [0|1] "" Vector__XXX
 SG_ PARK_a056_s12_overTemp m0 : 59|1@1+ (1,0) [0|1] "" Vector__XXX
 SG_ PARK_a057_s12_internalFail m0 : 60|1@1+ (1,0) [0|1] "" Vector__XXX
 SG_ PARK_a058_s12_linCommError m0 : 61|1@1+ (1,0) [0|1] "" Vector__XXX
 SG_ PARK_a059_s12_blocked m0 : 62|1@1+ (1,0) [0|1] "" Vector__XXX
 SG_ PARK_a060_s12_crossTalk m0 : 63|1@1+ (1,0) [0|1] "" Vector__XXX
 SG_ PARK_a061_ecuUnderVoltage m1 : 4|1@1+ (1,0) [0|1] "" Vector__XXX
 SG_ PARK_a062_ecuOverVoltage m1 : 5|1@1+ (1,0) [0|1] "" Vector__XXX
 SG_ PARK_a063_sensorVoltage m1 : 6|1@1+ (1,0) [0|1] "" Vector__XXX
 SG_ PARK_a064_ecuFault m1 : 7|1@1+ (1,0) [0|1] "" Vector__XXX
 SG_ PARK_a065_crcFault m1 : 8|1@1+ (1,0) [0|1] "" Vector__XXX
 SG_ PARK_a066_calibrationMissing m1 : 9|1@1+ (1,0) [0|1] "" Vector__XXX
 SG_ PARK_a067_privateCANBusOff m1 : 10|1@1+ (1,0) [0|1] "" Vector__XXX
 SG_ PARK_a068_hardwareWatchDog m1 : 11|1@1+ (1,0) [0|1] "" Vector__XXX
 SG_ PARK_a069_dasMia m1 : 12|1@1+ (1,0) [0|1] "" Vector__XXX
 SG_ PARK_a070_sccmMia m1 : 13|1@1+ (1,0) [0|1] "" Vector__XXX
 SG_ PARK_a071_diMia m1 : 14|1@1+ (1,0) [0|1] "" Vector__XXX
 SG_ PARK_a072_epasMia m1 : 15|1@1+ (1,0) [0|1] "" Vector__XXX
 SG_ PARK_a073_epbMia m1 : 16|1@1+ (1,0) [0|1] "" Vector__XXX
 SG_ PARK_a074_espMia m1 : 17|1@1+ (1,0) [0|1] "" Vector__XXX
 SG_ PARK_a075_rcmMia m1 : 18|1@1+ (1,0) [0|1] "" Vector__XXX
 SG_ PARK_a076_vcFrontMia m1 : 19|1@1+ (1,0) [0|1] "" Vector__XXX
 SG_ PARK_a077_dasError m1 : 20|1@1+ (1,0) [0|1] "" Vector__XXX
 SG_ PARK_a078_diError m1 : 21|1@1+ (1,0) [0|1] "" Vector__XXX
 SG_ PARK_a079_epasError m1 : 22|1@1+ (1,0) [0|1] "" Vector__XXX
 SG_ PARK_a080_epbError m1 : 23|1@1+ (1,0) [0|1] "" Vector__XXX
 SG_ PARK_a081_espError m1 : 24|1@1+ (1,0) [0|1] "" Vector__XXX
 SG_ PARK_a082_rcmError m1 : 25|1@1+ (1,0) [0|1] "" Vector__XXX
 SG_ PARK_a083_vcFrontError m1 : 26|1@1+ (1,0) [0|1] "" Vector__XXX
 SG_ PARK_a084_sccmError m1 : 27|1@1+ (1,0) [0|1] "" Vector__XXX
 SG_ PARK_a085_watchdogReset m1 : 28|1@1+ (1,0) [0|1] "" Vector__XXX
 SG_ PARK_a086_nvmFault m1 : 29|1@1+ (1,0) [0|1] "" Vector__XXX
 SG_ PARK_a087_sensorMismatchError m1 : 30|1@1+ (1,0) [0|1] "" Vector__XXX

BO_ 1365 RADC_alertLog: 8 RADC
 SG_ RADC_alertID M : 0|6@1+ (1,0) [0|63] "" Vector__XXX
 SG_ RADC_alertState : 15|1@1+ (1,0) [0|1] "" Vector__XXX
 SG_ RADC_a002_ecuAdcErrType m2 : 16|8@1+ (1,0) [0|255] "" Vector__XXX
 SG_ RADC_a008_interLockErrType m8 : 16|8@1+ (1,0) [0|255] "" Vector__XXX
 SG_ RADC_a011_ecuMcemErrType m11 : 16|8@1+ (1,0) [0|255] "" Vector__XXX
 SG_ RADC_a013_ecuWdgErrType m13 : 16|8@1+ (1,0) [0|255] "" Vector__XXX
 SG_ RADC_a016_adcOverVoltType m16 : 16|8@1+ (1,0) [0|255] "" Vector__XXX
 SG_ RADC_a016_adcVoltage m16 : 24|6@1+ (0.1,0) [0|6.3] "v" Vector__XXX
 SG_ RADC_a017_adcUnderVoltType m17 : 16|8@1+ (1,0) [0|255] "" Vector__XXX
 SG_ RADC_a017_adcVoltage m17 : 24|6@1+ (0.1,0) [0|6.3] "v" Vector__XXX
 SG_ RADC_a019_internalSWFaultType m19 : 16|8@1+ (1,0) [0|255] "" Vector__XXX
 SG_ RADC_a019_internalSWFaultCoreID m19 : 24|4@1+ (1,0) [0|15] "" Vector__XXX
 SG_ RADC_a020_ecuTemp m20 : 16|16@1+ (0.1,-44) [-44|6509.5] "deg" Vector__XXX
 SG_ RADC_a023_ecuTemp m23 : 16|16@1+ (0.1,-44) [-44|6509.5] "deg" Vector__XXX
 SG_ RADC_a025_ecuVoltage m25 : 16|8@1+ (0.1,0) [0|25.5] "v" Vector__XXX
 SG_ RADC_a026_ecuVoltage m26 : 16|8@1+ (0.1,0) [0|25.5] "v" Vector__XXX
 SG_ RADC_a027_nvmFailureType m27 : 16|8@1+ (1,0) [0|255] "" Vector__XXX
 SG_ RADC_a028_rfComRegCheckFail m28 : 16|8@1+ (1,0) [0|255] "" Vector__XXX
 SG_ RADC_a029_rhcChirpMonErrType m29 : 16|8@1+ (1,0) [0|255] "" Vector__XXX
 SG_ RADC_a029_rhcRxLongTermErrType m29 : 24|8@1+ (1,0) [0|255] "" Vector__XXX
 SG_ RADC_a029_rhcRxErrType m29 : 32|8@1+ (1,0) [0|255] "" Vector__XXX
 SG_ RADC_a029_rhcVcoPowerErrType m29 : 40|8@1+ (1,0) [0|255] "" Vector__XXX
 SG_ RADC_a029_rhcSp1ErrType m29 : 48|8@1+ (1,0) [0|255] "" Vector__XXX
 SG_ RADC_a029_rhcFdcErrType m29 : 56|8@1+ (1,0) [0|255] "" Vector__XXX
 SG_ RADC_a030_rspErrType m30 : 16|8@1+ (1,0) [0|255] "" Vector__XXX
 SG_ RADC_a031_horizMisalignAngle m31 : 16|8@1+ (0.001953125,-0.25) [-0.25|0.248046875] "rad" Vector__XXX
 SG_ RADC_a031_vertMisalignAngle m31 : 24|12@1+ (0.0001220703125,-0.25) [-0.25|0.249877929688] "rad" Vector__XXX
 SG_ RADC_a032_blockageType m32 : 16|8@1+ (1,0) [0|255] "" Vector__XXX
 SG_ RADC_a032_block_SPMBlockageState m32 : 24|3@1+ (1,0) [0|7] "" Vector__XXX
 SG_ RADC_a032_block_dummy m32 : 27|3@1+ (1,0) [0|7] "" Vector__XXX
 SG_ RADC_a032_block_SPMSelfTestState m32 : 30|2@1+ (1,0) [0|3] "" Vector__XXX
 SG_ RADC_a032_block_ucEstiRange m32 : 32|8@1+ (1,0) [0|255] "m" Vector__XXX
 SG_ RADC_a032_block_ucEstiRangeConf m32 : 40|8@1+ (1,0) [0|255] "" Vector__XXX
 SG_ RADC_a032_block_ucEstiRangeProb m32 : 48|8@1+ (1,0) [0|255] "" Vector__XXX
 SG_ RADC_a032_block_ucTimeoutBlkConf m32 : 56|8@1+ (1,0) [0|255] "" Vector__XXX
 SG_ RADC_a035_msgId m35 : 16|12@1+ (1,0) [0|4095] "" Vector__XXX
 SG_ RADC_a036_msgId m36 : 16|12@1+ (1,0) [0|4095] "" Vector__XXX
 SG_ RADC_a037_msgId m37 : 16|12@1+ (1,0) [0|4095] "" Vector__XXX
 SG_ RADC_a038_msgId m38 : 16|12@1+ (1,0) [0|4095] "" Vector__XXX
 SG_ RADC_a039_msgId m39 : 16|12@1+ (1,0) [0|4095] "" Vector__XXX
 SG_ RADC_a040_msgId m40 : 16|12@1+ (1,0) [0|4095] "" Vector__XXX
 SG_ RADC_a041_vinErrType m41 : 16|4@1+ (1,0) [0|15] "" Vector__XXX
 SG_ RADC_a041_vinErrExp m41 : 20|16@1+ (1,0) [0|65535] "" Vector__XXX
 SG_ RADC_a041_vinErrRx m41 : 36|16@1+ (1,0) [0|65535] "" Vector__XXX
 SG_ RADC_a041_msgId m41 : 52|12@1+ (1,0) [0|4095] "" Vector__XXX
 SG_ RADC_a042_carConfigErrType m42 : 16|4@1+ (1,0) [0|15] "" Vector__XXX
 SG_ RADC_a042_carConfigErrExp m42 : 20|16@1+ (1,0) [0|65535] "" Vector__XXX
 SG_ RADC_a042_carConfigErrRx m42 : 36|16@1+ (1,0) [0|65535] "" Vector__XXX
 SG_ RADC_a042_msgId m42 : 52|12@1+ (1,0) [0|4095] "" Vector__XXX
 SG_ RADC_a043_inertialSignalsErrType m43 : 16|4@1+ (1,0) [0|15] "" Vector__XXX
 SG_ RADC_a043_inertialSignalsErrExp m43 : 20|16@1+ (1,0) [0|65535] "" Vector__XXX
 SG_ RADC_a043_inertialSignalsErrRx m43 : 36|16@1+ (1,0) [0|65535] "" Vector__XXX
 SG_ RADC_a043_msgId m43 : 52|12@1+ (1,0) [0|4095] "" Vector__XXX
 SG_ RADC_a044_stwAngleErrType m44 : 16|4@1+ (1,0) [0|15] "" Vector__XXX
 SG_ RADC_a044_stwAngleErrExp m44 : 20|16@1+ (1,0) [0|65535] "" Vector__XXX
 SG_ RADC_a044_stwAngleErrRx m44 : 36|16@1+ (1,0) [0|65535] "" Vector__XXX
 SG_ RADC_a044_msgId m44 : 52|12@1+ (1,0) [0|4095] "" Vector__XXX
 SG_ RADC_a045_vehicleStateErrType m45 : 16|4@1+ (1,0) [0|15] "" Vector__XXX
 SG_ RADC_a045_vehicleStateErrExp m45 : 20|16@1+ (1,0) [0|65535] "" Vector__XXX
 SG_ RADC_a045_vehicleStateErrRx m45 : 36|16@1+ (1,0) [0|65535] "" Vector__XXX
 SG_ RADC_a045_msgId m45 : 52|12@1+ (1,0) [0|4095] "" Vector__XXX
 SG_ RADC_a046_wheelSpeedsErrType m46 : 16|4@1+ (1,0) [0|15] "" Vector__XXX
 SG_ RADC_a046_wheelSpeedsErrExp m46 : 20|16@1+ (1,0) [0|65535] "" Vector__XXX
 SG_ RADC_a046_wheelSpeedsErrRx m46 : 36|16@1+ (1,0) [0|65535] "" Vector__XXX
 SG_ RADC_a046_msgId m46 : 52|12@1+ (1,0) [0|4095] "" Vector__XXX
 SG_ RADC_a047_chassisTypeExp m47 : 16|8@1+ (1,0) [0|255] "" Vector__XXX
 SG_ RADC_a047_chassisTypeRx m47 : 24|8@1+ (1,0) [0|255] "" Vector__XXX
 SG_ RADC_a048_airSuspensionExp m48 : 16|8@1+ (1,0) [0|255] "" Vector__XXX
 SG_ RADC_a048_airSuspensionRx m48 : 24|8@1+ (1,0) [0|255] "" Vector__XXX
 SG_ RADC_a049_fourWheelDriveExp m49 : 16|8@1+ (1,0) [0|255] "" Vector__XXX
 SG_ RADC_a049_fourWheelDriveRx m49 : 24|8@1+ (1,0) [0|255] "" Vector__XXX
 SG_ RADC_a050_countryExp m50 : 16|16@1+ (1,0) [0|65535] "" Vector__XXX
 SG_ RADC_a050_countryRx m50 : 32|16@1+ (1,0) [0|65535] "" Vector__XXX
 SG_ RADC_a051_epasTypeExp m51 : 16|8@1+ (1,0) [0|255] "" Vector__XXX
 SG_ RADC_a051_epasTypeRx m51 : 24|8@1+ (1,0) [0|255] "" Vector__XXX
 SG_ RADC_a052_radarPositionExp m52 : 16|8@1+ (1,0) [0|255] "" Vector__XXX
 SG_ RADC_a052_radarPositionRx m52 : 24|8@1+ (1,0) [0|255] "" Vector__XXX
 SG_ RADC_a054_block_ucObjLossProb m54 : 16|8@1+ (1,0) [0|255] "" Vector__XXX
 SG_ RADC_a054_block_ucObjLossConf m54 : 24|8@1+ (1,0) [0|255] "" Vector__XXX
 SG_ RADC_a054_block_ucOverallProb m54 : 32|8@1+ (1,0) [0|255] "" Vector__XXX
 SG_ RADC_a054_block_ucOverallConf m54 : 40|8@1+ (1,0) [0|255] "" Vector__XXX
 SG_ RADC_a054_block_RoadbeamTimeCnt m54 : 48|16@1+ (1,0) [0|65535] "s" Vector__XXX
 SG_ RADC_a055_block_usTimeoutWayCnt m55 : 16|16@1+ (1,0) [0|65535] "m" Vector__XXX
 SG_ RADC_a055_block_ucTimeoutTimeCnt m55 : 32|8@1+ (1,0) [0|255] "s" Vector__XXX
 SG_ RADC_a055_bblock_ucTimeoutBlkPro m55 : 40|8@1+ (1,0) [0|255] "" Vector__XXX
 SG_ RADC_a055_block_usFullBlkTimer m55 : 48|16@1+ (1,0) [0|65535] "s" Vector__XXX

BO_ 1282 RADC_alertMatrix0: 8 RADC
 SG_ RADC_a001_can1BusOff : 1|1@1+ (1,0) [0|1] "" Vector__XXX
 SG_ RADC_a002_ecuAdcError : 2|1@1+ (1,0) [0|1] "" Vector__XXX
 SG_ RADC_a003_ecuBistDisabled : 3|1@1+ (1,0) [0|1] "" Vector__XXX
 SG_ RADC_a004_ecuCrcHwError : 4|1@1+ (1,0) [0|1] "" Vector__XXX
 SG_ RADC_a005_ecuEcuMError : 5|1@1+ (1,0) [0|1] "" Vector__XXX
 SG_ RADC_a006_ecuFimError : 6|1@1+ (1,0) [0|1] "" Vector__XXX
 SG_ RADC_a007_ecuGptCheckError : 7|1@1+ (1,0) [0|1] "" Vector__XXX
 SG_ RADC_a008_ecuHwSwInterlock : 8|1@1+ (1,0) [0|1] "" Vector__XXX
 SG_ RADC_a009_plantModeActive : 9|1@1+ (1,0) [0|1] "" Vector__XXX
 SG_ RADC_a010_ecuIoHwAbError : 10|1@1+ (1,0) [0|1] "" Vector__XXX
 SG_ RADC_a011_ecuMcemError : 11|1@1+ (1,0) [0|1] "" Vector__XXX
 SG_ RADC_a012_ecuSpiError : 12|1@1+ (1,0) [0|1] "" Vector__XXX
 SG_ RADC_a013_ecuWdgError : 13|1@1+ (1,0) [0|1] "" Vector__XXX
 SG_ RADC_a014_fctSelfTestNotDone : 14|1@1+ (1,0) [0|1] "" Vector__XXX
 SG_ RADC_a015_fctSenInterference : 15|1@1+ (1,0) [0|1] "" Vector__XXX
 SG_ RADC_a016_adcOverVolt : 16|1@1+ (1,0) [0|1] "" Vector__XXX
 SG_ RADC_a017_adcUnderVolt : 17|1@1+ (1,0) [0|1] "" Vector__XXX
 SG_ RADC_a018_internalHardwareFault : 18|1@1+ (1,0) [0|1] "" Vector__XXX
 SG_ RADC_a019_internalSoftwareFault : 19|1@1+ (1,0) [0|1] "" Vector__XXX
 SG_ RADC_a020_overTemp : 20|1@1+ (1,0) [0|1] "" Vector__XXX
 SG_ RADC_a021_overTempCrit : 21|1@1+ (1,0) [0|1] "" Vector__XXX
 SG_ RADC_a022_tempImplausible : 22|1@1+ (1,0) [0|1] "" Vector__XXX
 SG_ RADC_a023_underTemp : 23|1@1+ (1,0) [0|1] "" Vector__XXX
 SG_ RADC_a024_underTempCrit : 24|1@1+ (1,0) [0|1] "" Vector__XXX
 SG_ RADC_a025_overVoltage : 25|1@1+ (1,0) [0|1] "" Vector__XXX
 SG_ RADC_a026_underVoltage : 26|1@1+ (1,0) [0|1] "" Vector__XXX
 SG_ RADC_a027_nvmFailure : 27|1@1+ (1,0) [0|1] "" Vector__XXX
 SG_ RADC_a028_rfChipError : 28|1@1+ (1,0) [0|1] "" Vector__XXX
 SG_ RADC_a029_rhcError : 29|1@1+ (1,0) [0|1] "" Vector__XXX
 SG_ RADC_a030_rspError : 30|1@1+ (1,0) [0|1] "" Vector__XXX
 SG_ RADC_a031_sensorMisaligned : 31|1@1+ (1,0) [0|1] "" Vector__XXX
 SG_ RADC_a032_sensorBlocked : 32|1@1+ (1,0) [0|1] "" Vector__XXX
 SG_ RADC_a033_sensorNeverAligned : 33|1@1+ (1,0) [0|1] "" Vector__XXX
 SG_ RADC_a034_vehDynamicsError : 34|1@1+ (1,0) [0|1] "" Vector__XXX
 SG_ RADC_a035_vinMIA : 35|1@1+ (1,0) [0|1] "" Vector__XXX
 SG_ RADC_a036_carConfigMIA : 36|1@1+ (1,0) [0|1] "" Vector__XXX
 SG_ RADC_a037_inertialSignalsMIA : 37|1@1+ (1,0) [0|1] "" Vector__XXX
 SG_ RADC_a038_steeringWheelAngleMIA : 38|1@1+ (1,0) [0|1] "" Vector__XXX
 SG_ RADC_a039_vehicleStateMIA : 39|1@1+ (1,0) [0|1] "" Vector__XXX
 SG_ RADC_a040_wheelSpeedsMIA : 40|1@1+ (1,0) [0|1] "" Vector__XXX
 SG_ RADC_a041_vinErr : 41|1@1+ (1,0) [0|1] "" Vector__XXX
 SG_ RADC_a042_carConfigErr : 42|1@1+ (1,0) [0|1] "" Vector__XXX
 SG_ RADC_a043_inertialSignalsErr : 43|1@1+ (1,0) [0|1] "" Vector__XXX
 SG_ RADC_a044_steeringWheelAngleErr : 44|1@1+ (1,0) [0|1] "" Vector__XXX
 SG_ RADC_a045_vehicleStateErr : 45|1@1+ (1,0) [0|1] "" Vector__XXX
 SG_ RADC_a046_wheelSpeedsErr : 46|1@1+ (1,0) [0|1] "" Vector__XXX
 SG_ RADC_a047_mismatchChassisType : 47|1@1+ (1,0) [0|1] "" Vector__XXX
 SG_ RADC_a048_mismatchAirSuspension : 48|1@1+ (1,0) [0|1] "" Vector__XXX
 SG_ RADC_a049_mismatchFourWheelDrive : 49|1@1+ (1,0) [0|1] "" Vector__XXX
 SG_ RADC_a050_mismatchCountry : 50|1@1+ (1,0) [0|1] "" Vector__XXX
 SG_ RADC_a051_mismatchEPASType : 51|1@1+ (1,0) [0|1] "" Vector__XXX
 SG_ RADC_a052_mismatcRadPos : 52|1@1+ (1,0) [0|1] "" Vector__XXX
 SG_ RADC_a053_emError : 53|1@1+ (1,0) [0|1] "" Vector__XXX
 SG_ RADC_a054_blockageInfo_Frame_1 : 54|1@1+ (1,0) [0|1] "" Vector__XXX
 SG_ RADC_a055_blockageInfo_Frame_2 : 55|1@1+ (1,0) [0|1] "" Vector__XXX

BO_ 1329 RADC_info: 8 RADC
 SG_ RADC_infoIndex M : 0|8@1+ (1,0) [0|255] "" Vector__XXX
 SG_ RADC_infoBuildType m10 : 8|8@1+ (1,0) [0|255] "" Vector__XXX
 SG_ RADC_infoBuildConfigID m10 : 16|16@1+ (1,0) [0|65535] "" Vector__XXX
 SG_ RADC_infoHardwareID m10 : 32|16@1+ (1,0) [0|65535] "" Vector__XXX
 SG_ RADC_infoComponentID m10 : 48|16@1+ (1,0) [0|65535] "" Vector__XXX
 SG_ RADC_infoPcbaID m11 : 16|8@1+ (1,0) [0|255] "" Vector__XXX
 SG_ RADC_infoAssemblyID m11 : 24|8@1+ (1,0) [0|255] "" Vector__XXX
 SG_ RADC_infoUsageID m11 : 32|16@1+ (1,0) [0|65535] "" Vector__XXX
 SG_ RADC_infoSubUsageID m11 : 48|16@1+ (1,0) [0|65535] "" Vector__XXX
 SG_ RADC_infoApplicationCRC m13 : 32|32@1+ (1,0) [0|4294967295] "" Vector__XXX
 SG_ RADC_infoPlatformType m19 : 8|8@1+ (1,0) [0|255] "" Vector__XXX
 SG_ RADC_infoMajorVersion m19 : 16|8@1+ (1,0) [0|255] "" Vector__XXX
 SG_ RADC_infoBranchOrigin m19 : 24|8@1+ (1,0) [0|255] "" Vector__XXX
 SG_ RADC_infoMaturity m19 : 32|8@1+ (1,0) [0|255] "" Vector__XXX
 SG_ RADC_infoHardwareRevision m19 : 40|8@1+ (1,0) [0|255] "" Vector__XXX
 SG_ RADC_infoBootUdsProtoVersion m20 : 8|8@1+ (1,0) [0|255] "" Vector__XXX
 SG_ RADC_infoBootloaderCRC m20 : 32|32@1+ (1,0) [0|4294967295] "" Vector__XXX

BO_ 1665 RADC_udsResponse: 8 RADC
 SG_ RADC_udsResponseData : 7|64@0+ (1,0) [0|1.84467440737e+19] "" Vector__XXX

BO_TX_BU_ 1486 : PARK;
BO_TX_BU_ 806 : PARK;
BO_TX_BU_ 846 : PARK;
BO_TX_BU_ 862 : PARK;
BO_TX_BU_ 926 : PARK;
BO_TX_BU_ 606 : PARK;
BO_TX_BU_ 542 : PARK;
BO_TX_BU_ 590 : PARK;
BO_TX_BU_ 526 : PARK;
BO_TX_BU_ 558 : PARK;
BO_TX_BU_ 814 : PARK;
BO_TX_BU_ 830 : PARK;
BO_TX_BU_ 798 : PARK;
BO_TX_BU_ 782 : PARK;
BO_TX_BU_ 1630 : PARK;
BO_TX_BU_ 894 : PARK;
BO_TX_BU_ 1365 : RADC;
BO_TX_BU_ 1282 : RADC;
BO_TX_BU_ 1329 : RADC;
BO_TX_BU_ 1665 : RADC;
CM_ BO_ 1486 "Parking assist sensors message: alert log; frame length from the layout, not yet observed on a vehicle bus";
CM_ SG_ 1486 PARK_alertID "Parking assist sensors: alert ID";
CM_ SG_ 1486 PARK_alertState "Parking assist sensors: alert state";
CM_ SG_ 1486 PARK_sw001_sensorTemperature "Parking assist sensors: sw001 sensor temperature";
CM_ SG_ 1486 PARK_sw002_membraneDisconct "Parking assist sensors: sw002 membrane disconct";
CM_ SG_ 1486 PARK_sw002_dampResistorFail "Parking assist sensors: sw002 damp resistor fail";
CM_ SG_ 1486 PARK_sw002_resonanceDrift "Parking assist sensors: sw002 resonance drift";
CM_ SG_ 1486 PARK_sw002_sensorCRC "Parking assist sensors: sw002 sensor CRC";
CM_ SG_ 1486 PARK_sw002_recieveFailure "Parking assist sensors: sw002 recieve failure";
CM_ SG_ 1486 PARK_sw002_diagnosticTransferErr "Parking assist sensors: sw002 diagnostic transfer error";
CM_ SG_ 1486 PARK_sw003_linError "Parking assist sensors: sw003 lin error";
CM_ SG_ 1486 PARK_sw003_linBusError "Parking assist sensors: sw003 lin bus error";
CM_ SG_ 1486 PARK_sw003_linFrameCountError "Parking assist sensors: sw003 lin frame count error";
CM_ SG_ 1486 PARK_sw004_reverbPeriod "Parking assist sensors: sw004 reverb period";
CM_ SG_ 1486 PARK_sw004_reverbTime "Parking assist sensors: sw004 reverb time";
CM_ SG_ 1486 PARK_sw004_highAttenTime "Parking assist sensors: sw004 high atten time";
CM_ SG_ 1486 PARK_sw004_closeConstEcho "Parking assist sensors: sw004 close const echo";
CM_ SG_ 1486 PARK_sw004_lowAttenTime "Parking assist sensors: sw004 low atten time";
CM_ SG_ 1486 PARK_sw004_attenTimeJitter "Parking assist sensors: sw004 atten time jitter";
CM_ SG_ 1486 PARK_sw004_reverbFreqJitter "Parking assist sensors: sw004 reverb freq jitter";
CM_ SG_ 1486 PARK_sw006_sensorTemperature "Parking assist sensors: sw006 sensor temperature";
CM_ SG_ 1486 PARK_sw007_membraneDisconct "Parking assist sensors: sw007 membrane disconct";
CM_ SG_ 1486 PARK_sw007_dampResistorFail "Parking assist sensors: sw007 damp resistor fail";
CM_ SG_ 1486 PARK_sw007_resonanceDrift "Parking assist sensors: sw007 resonance drift";
CM_ SG_ 1486 PARK_sw007_sensorCRC "Parking assist sensors: sw007 sensor CRC";
CM_ SG_ 1486 PARK_sw007_recieveFailure "Parking assist sensors: sw007 recieve failure";
CM_ SG_ 1486 PARK_sw007_diagnosticTransferErr "Parking assist sensors: sw007 diagnostic transfer error";
CM_ SG_ 1486 PARK_sw008_linError "Parking assist sensors: sw008 lin error";
CM_ SG_ 1486 PARK_sw008_linBusError "Parking assist sensors: sw008 lin bus error";
CM_ SG_ 1486 PARK_sw008_linFrameCountError "Parking assist sensors: sw008 lin frame count error";
CM_ SG_ 1486 PARK_sw009_reverbPeriod "Parking assist sensors: sw009 reverb period";
CM_ SG_ 1486 PARK_sw009_reverbTime "Parking assist sensors: sw009 reverb time";
CM_ SG_ 1486 PARK_sw009_highAttenTime "Parking assist sensors: sw009 high atten time";
CM_ SG_ 1486 PARK_sw009_closeConstEcho "Parking assist sensors: sw009 close const echo";
CM_ SG_ 1486 PARK_sw009_lowAttenTime "Parking assist sensors: sw009 low atten time";
CM_ SG_ 1486 PARK_sw009_attenTimeJitter "Parking assist sensors: sw009 atten time jitter";
CM_ SG_ 1486 PARK_sw009_reverbFreqJitter "Parking assist sensors: sw009 reverb freq jitter";
CM_ SG_ 1486 PARK_sw011_sensorTemperature "Parking assist sensors: sw011 sensor temperature";
CM_ SG_ 1486 PARK_sw012_membraneDisconct "Parking assist sensors: sw012 membrane disconct";
CM_ SG_ 1486 PARK_sw012_dampResistorFail "Parking assist sensors: sw012 damp resistor fail";
CM_ SG_ 1486 PARK_sw012_resonanceDrift "Parking assist sensors: sw012 resonance drift";
CM_ SG_ 1486 PARK_sw012_sensorCRC "Parking assist sensors: sw012 sensor CRC";
CM_ SG_ 1486 PARK_sw012_recieveFailure "Parking assist sensors: sw012 recieve failure";
CM_ SG_ 1486 PARK_sw012_diagnosticTransferErr "Parking assist sensors: sw012 diagnostic transfer error";
CM_ SG_ 1486 PARK_sw013_linError "Parking assist sensors: sw013 lin error";
CM_ SG_ 1486 PARK_sw013_linBusError "Parking assist sensors: sw013 lin bus error";
CM_ SG_ 1486 PARK_sw013_linFrameCountError "Parking assist sensors: sw013 lin frame count error";
CM_ SG_ 1486 PARK_sw014_reverbPeriod "Parking assist sensors: sw014 reverb period";
CM_ SG_ 1486 PARK_sw014_reverbTime "Parking assist sensors: sw014 reverb time";
CM_ SG_ 1486 PARK_sw014_highAttenTime "Parking assist sensors: sw014 high atten time";
CM_ SG_ 1486 PARK_sw014_closeConstEcho "Parking assist sensors: sw014 close const echo";
CM_ SG_ 1486 PARK_sw014_lowAttenTime "Parking assist sensors: sw014 low atten time";
CM_ SG_ 1486 PARK_sw014_attenTimeJitter "Parking assist sensors: sw014 atten time jitter";
CM_ SG_ 1486 PARK_sw014_reverbFreqJitter "Parking assist sensors: sw014 reverb freq jitter";
CM_ SG_ 1486 PARK_sw016_sensorTemperature "Parking assist sensors: sw016 sensor temperature";
CM_ SG_ 1486 PARK_sw017_membraneDisconct "Parking assist sensors: sw017 membrane disconct";
CM_ SG_ 1486 PARK_sw017_dampResistorFail "Parking assist sensors: sw017 damp resistor fail";
CM_ SG_ 1486 PARK_sw017_resonanceDrift "Parking assist sensors: sw017 resonance drift";
CM_ SG_ 1486 PARK_sw017_sensorCRC "Parking assist sensors: sw017 sensor CRC";
CM_ SG_ 1486 PARK_sw017_recieveFailure "Parking assist sensors: sw017 recieve failure";
CM_ SG_ 1486 PARK_sw017_diagnosticTransferErr "Parking assist sensors: sw017 diagnostic transfer error";
CM_ SG_ 1486 PARK_sw018_linError "Parking assist sensors: sw018 lin error";
CM_ SG_ 1486 PARK_sw018_linBusError "Parking assist sensors: sw018 lin bus error";
CM_ SG_ 1486 PARK_sw018_linFrameCountError "Parking assist sensors: sw018 lin frame count error";
CM_ SG_ 1486 PARK_sw019_reverbPeriod "Parking assist sensors: sw019 reverb period";
CM_ SG_ 1486 PARK_sw019_reverbTime "Parking assist sensors: sw019 reverb time";
CM_ SG_ 1486 PARK_sw019_highAttenTime "Parking assist sensors: sw019 high atten time";
CM_ SG_ 1486 PARK_sw019_closeConstEcho "Parking assist sensors: sw019 close const echo";
CM_ SG_ 1486 PARK_sw019_lowAttenTime "Parking assist sensors: sw019 low atten time";
CM_ SG_ 1486 PARK_sw019_attenTimeJitter "Parking assist sensors: sw019 atten time jitter";
CM_ SG_ 1486 PARK_sw019_reverbFreqJitter "Parking assist sensors: sw019 reverb freq jitter";
CM_ SG_ 1486 PARK_sw021_sensorTemperature "Parking assist sensors: sw021 sensor temperature";
CM_ SG_ 1486 PARK_sw022_membraneDisconct "Parking assist sensors: sw022 membrane disconct";
CM_ SG_ 1486 PARK_sw022_dampResistorFail "Parking assist sensors: sw022 damp resistor fail";
CM_ SG_ 1486 PARK_sw022_resonanceDrift "Parking assist sensors: sw022 resonance drift";
CM_ SG_ 1486 PARK_sw022_sensorCRC "Parking assist sensors: sw022 sensor CRC";
CM_ SG_ 1486 PARK_sw022_recieveFailure "Parking assist sensors: sw022 recieve failure";
CM_ SG_ 1486 PARK_sw022_diagnosticTransferErr "Parking assist sensors: sw022 diagnostic transfer error";
CM_ SG_ 1486 PARK_sw023_linError "Parking assist sensors: sw023 lin error";
CM_ SG_ 1486 PARK_sw023_linBusError "Parking assist sensors: sw023 lin bus error";
CM_ SG_ 1486 PARK_sw023_linFrameCountError "Parking assist sensors: sw023 lin frame count error";
CM_ SG_ 1486 PARK_sw024_reverbPeriod "Parking assist sensors: sw024 reverb period";
CM_ SG_ 1486 PARK_sw024_reverbTime "Parking assist sensors: sw024 reverb time";
CM_ SG_ 1486 PARK_sw024_highAttenTime "Parking assist sensors: sw024 high atten time";
CM_ SG_ 1486 PARK_sw024_closeConstEcho "Parking assist sensors: sw024 close const echo";
CM_ SG_ 1486 PARK_sw024_lowAttenTime "Parking assist sensors: sw024 low atten time";
CM_ SG_ 1486 PARK_sw024_attenTimeJitter "Parking assist sensors: sw024 atten time jitter";
CM_ SG_ 1486 PARK_sw024_reverbFreqJitter "Parking assist sensors: sw024 reverb freq jitter";
CM_ SG_ 1486 PARK_sw026_sensorTemperature "Parking assist sensors: sw026 sensor temperature";
CM_ SG_ 1486 PARK_sw027_membraneDisconct "Parking assist sensors: sw027 membrane disconct";
CM_ SG_ 1486 PARK_sw027_dampResistorFail "Parking assist sensors: sw027 damp resistor fail";
CM_ SG_ 1486 PARK_sw027_resonanceDrift "Parking assist sensors: sw027 resonance drift";
CM_ SG_ 1486 PARK_sw027_sensorCRC "Parking assist sensors: sw027 sensor CRC";
CM_ SG_ 1486 PARK_sw027_recieveFailure "Parking assist sensors: sw027 recieve failure";
CM_ SG_ 1486 PARK_sw027_diagnosticTransferErr "Parking assist sensors: sw027 diagnostic transfer error";
CM_ SG_ 1486 PARK_sw028_linError "Parking assist sensors: sw028 lin error";
CM_ SG_ 1486 PARK_sw028_linBusError "Parking assist sensors: sw028 lin bus error";
CM_ SG_ 1486 PARK_sw028_linFrameCountError "Parking assist sensors: sw028 lin frame count error";
CM_ SG_ 1486 PARK_sw029_reverbPeriod "Parking assist sensors: sw029 reverb period";
CM_ SG_ 1486 PARK_sw029_reverbTime "Parking assist sensors: sw029 reverb time";
CM_ SG_ 1486 PARK_sw029_highAttenTime "Parking assist sensors: sw029 high atten time";
CM_ SG_ 1486 PARK_sw029_closeConstEcho "Parking assist sensors: sw029 close const echo";
CM_ SG_ 1486 PARK_sw029_lowAttenTime "Parking assist sensors: sw029 low atten time";
CM_ SG_ 1486 PARK_sw029_attenTimeJitter "Parking assist sensors: sw029 atten time jitter";
CM_ SG_ 1486 PARK_sw029_reverbFreqJitter "Parking assist sensors: sw029 reverb freq jitter";
CM_ SG_ 1486 PARK_sw031_sensorTemperature "Parking assist sensors: sw031 sensor temperature";
CM_ SG_ 1486 PARK_sw032_membraneDisconct "Parking assist sensors: sw032 membrane disconct";
CM_ SG_ 1486 PARK_sw032_dampResistorFail "Parking assist sensors: sw032 damp resistor fail";
CM_ SG_ 1486 PARK_sw032_resonanceDrift "Parking assist sensors: sw032 resonance drift";
CM_ SG_ 1486 PARK_sw032_sensorCRC "Parking assist sensors: sw032 sensor CRC";
CM_ SG_ 1486 PARK_sw032_recieveFailure "Parking assist sensors: sw032 recieve failure";
CM_ SG_ 1486 PARK_sw032_diagnosticTransferErr "Parking assist sensors: sw032 diagnostic transfer error";
CM_ SG_ 1486 PARK_sw033_linError "Parking assist sensors: sw033 lin error";
CM_ SG_ 1486 PARK_sw033_linBusError "Parking assist sensors: sw033 lin bus error";
CM_ SG_ 1486 PARK_sw033_linFrameCountError "Parking assist sensors: sw033 lin frame count error";
CM_ SG_ 1486 PARK_sw034_reverbPeriod "Parking assist sensors: sw034 reverb period";
CM_ SG_ 1486 PARK_sw034_reverbTime "Parking assist sensors: sw034 reverb time";
CM_ SG_ 1486 PARK_sw034_highAttenTime "Parking assist sensors: sw034 high atten time";
CM_ SG_ 1486 PARK_sw034_closeConstEcho "Parking assist sensors: sw034 close const echo";
CM_ SG_ 1486 PARK_sw034_lowAttenTime "Parking assist sensors: sw034 low atten time";
CM_ SG_ 1486 PARK_sw034_attenTimeJitter "Parking assist sensors: sw034 atten time jitter";
CM_ SG_ 1486 PARK_sw034_reverbFreqJitter "Parking assist sensors: sw034 reverb freq jitter";
CM_ SG_ 1486 PARK_sw036_sensorTemperature "Parking assist sensors: sw036 sensor temperature";
CM_ SG_ 1486 PARK_sw037_membraneDisconct "Parking assist sensors: sw037 membrane disconct";
CM_ SG_ 1486 PARK_sw037_dampResistorFail "Parking assist sensors: sw037 damp resistor fail";
CM_ SG_ 1486 PARK_sw037_resonanceDrift "Parking assist sensors: sw037 resonance drift";
CM_ SG_ 1486 PARK_sw037_sensorCRC "Parking assist sensors: sw037 sensor CRC";
CM_ SG_ 1486 PARK_sw037_recieveFailure "Parking assist sensors: sw037 recieve failure";
CM_ SG_ 1486 PARK_sw037_diagnosticTransferErr "Parking assist sensors: sw037 diagnostic transfer error";
CM_ SG_ 1486 PARK_sw038_linError "Parking assist sensors: sw038 lin error";
CM_ SG_ 1486 PARK_sw038_linBusError "Parking assist sensors: sw038 lin bus error";
CM_ SG_ 1486 PARK_sw038_linFrameCountError "Parking assist sensors: sw038 lin frame count error";
CM_ SG_ 1486 PARK_sw039_reverbPeriod "Parking assist sensors: sw039 reverb period";
CM_ SG_ 1486 PARK_sw039_reverbTime "Parking assist sensors: sw039 reverb time";
CM_ SG_ 1486 PARK_sw039_highAttenTime "Parking assist sensors: sw039 high atten time";
CM_ SG_ 1486 PARK_sw039_closeConstEcho "Parking assist sensors: sw039 close const echo";
CM_ SG_ 1486 PARK_sw039_lowAttenTime "Parking assist sensors: sw039 low atten time";
CM_ SG_ 1486 PARK_sw039_attenTimeJitter "Parking assist sensors: sw039 atten time jitter";
CM_ SG_ 1486 PARK_sw039_reverbFreqJitter "Parking assist sensors: sw039 reverb freq jitter";
CM_ SG_ 1486 PARK_sw041_sensorTemperature "Parking assist sensors: sw041 sensor temperature";
CM_ SG_ 1486 PARK_sw042_membraneDisconct "Parking assist sensors: sw042 membrane disconct";
CM_ SG_ 1486 PARK_sw042_dampResistorFail "Parking assist sensors: sw042 damp resistor fail";
CM_ SG_ 1486 PARK_sw042_resonanceDrift "Parking assist sensors: sw042 resonance drift";
CM_ SG_ 1486 PARK_sw042_sensorCRC "Parking assist sensors: sw042 sensor CRC";
CM_ SG_ 1486 PARK_sw042_recieveFailure "Parking assist sensors: sw042 recieve failure";
CM_ SG_ 1486 PARK_sw042_diagnosticTransferErr "Parking assist sensors: sw042 diagnostic transfer error";
CM_ SG_ 1486 PARK_sw043_linError "Parking assist sensors: sw043 lin error";
CM_ SG_ 1486 PARK_sw043_linBusError "Parking assist sensors: sw043 lin bus error";
CM_ SG_ 1486 PARK_sw043_linFrameCountError "Parking assist sensors: sw043 lin frame count error";
CM_ SG_ 1486 PARK_sw044_reverbPeriod "Parking assist sensors: sw044 reverb period";
CM_ SG_ 1486 PARK_sw044_reverbTime "Parking assist sensors: sw044 reverb time";
CM_ SG_ 1486 PARK_sw044_highAttenTime "Parking assist sensors: sw044 high atten time";
CM_ SG_ 1486 PARK_sw044_closeConstEcho "Parking assist sensors: sw044 close const echo";
CM_ SG_ 1486 PARK_sw044_lowAttenTime "Parking assist sensors: sw044 low atten time";
CM_ SG_ 1486 PARK_sw044_attenTimeJitter "Parking assist sensors: sw044 atten time jitter";
CM_ SG_ 1486 PARK_sw044_reverbFreqJitter "Parking assist sensors: sw044 reverb freq jitter";
CM_ SG_ 1486 PARK_sw046_sensorTemperature "Parking assist sensors: sw046 sensor temperature";
CM_ SG_ 1486 PARK_sw047_membraneDisconct "Parking assist sensors: sw047 membrane disconct";
CM_ SG_ 1486 PARK_sw047_dampResistorFail "Parking assist sensors: sw047 damp resistor fail";
CM_ SG_ 1486 PARK_sw047_resonanceDrift "Parking assist sensors: sw047 resonance drift";
CM_ SG_ 1486 PARK_sw047_sensorCRC "Parking assist sensors: sw047 sensor CRC";
CM_ SG_ 1486 PARK_sw047_recieveFailure "Parking assist sensors: sw047 recieve failure";
CM_ SG_ 1486 PARK_sw047_diagnosticTransferErr "Parking assist sensors: sw047 diagnostic transfer error";
CM_ SG_ 1486 PARK_sw048_linError "Parking assist sensors: sw048 lin error";
CM_ SG_ 1486 PARK_sw048_linBusError "Parking assist sensors: sw048 lin bus error";
CM_ SG_ 1486 PARK_sw048_linFrameCountError "Parking assist sensors: sw048 lin frame count error";
CM_ SG_ 1486 PARK_sw049_reverbPeriod "Parking assist sensors: sw049 reverb period";
CM_ SG_ 1486 PARK_sw049_reverbTime "Parking assist sensors: sw049 reverb time";
CM_ SG_ 1486 PARK_sw049_highAttenTime "Parking assist sensors: sw049 high atten time";
CM_ SG_ 1486 PARK_sw049_closeConstEcho "Parking assist sensors: sw049 close const echo";
CM_ SG_ 1486 PARK_sw049_lowAttenTime "Parking assist sensors: sw049 low atten time";
CM_ SG_ 1486 PARK_sw049_attenTimeJitter "Parking assist sensors: sw049 atten time jitter";
CM_ SG_ 1486 PARK_sw049_reverbFreqJitter "Parking assist sensors: sw049 reverb freq jitter";
CM_ SG_ 1486 PARK_sw051_sensorTemperature "Parking assist sensors: sw051 sensor temperature";
CM_ SG_ 1486 PARK_sw052_membraneDisconct "Parking assist sensors: sw052 membrane disconct";
CM_ SG_ 1486 PARK_sw052_dampResistorFail "Parking assist sensors: sw052 damp resistor fail";
CM_ SG_ 1486 PARK_sw052_resonanceDrift "Parking assist sensors: sw052 resonance drift";
CM_ SG_ 1486 PARK_sw052_sensorCRC "Parking assist sensors: sw052 sensor CRC";
CM_ SG_ 1486 PARK_sw052_recieveFailure "Parking assist sensors: sw052 recieve failure";
CM_ SG_ 1486 PARK_sw052_diagnosticTransferErr "Parking assist sensors: sw052 diagnostic transfer error";
CM_ SG_ 1486 PARK_sw053_linError "Parking assist sensors: sw053 lin error";
CM_ SG_ 1486 PARK_sw053_linBusError "Parking assist sensors: sw053 lin bus error";
CM_ SG_ 1486 PARK_sw053_linFrameCountError "Parking assist sensors: sw053 lin frame count error";
CM_ SG_ 1486 PARK_sw054_reverbPeriod "Parking assist sensors: sw054 reverb period";
CM_ SG_ 1486 PARK_sw054_reverbTime "Parking assist sensors: sw054 reverb time";
CM_ SG_ 1486 PARK_sw054_highAttenTime "Parking assist sensors: sw054 high atten time";
CM_ SG_ 1486 PARK_sw054_closeConstEcho "Parking assist sensors: sw054 close const echo";
CM_ SG_ 1486 PARK_sw054_lowAttenTime "Parking assist sensors: sw054 low atten time";
CM_ SG_ 1486 PARK_sw054_attenTimeJitter "Parking assist sensors: sw054 atten time jitter";
CM_ SG_ 1486 PARK_sw054_reverbFreqJitter "Parking assist sensors: sw054 reverb freq jitter";
CM_ SG_ 1486 PARK_sw056_sensorTemperature "Parking assist sensors: sw056 sensor temperature";
CM_ SG_ 1486 PARK_sw057_membraneDisconct "Parking assist sensors: sw057 membrane disconct";
CM_ SG_ 1486 PARK_sw057_dampResistorFail "Parking assist sensors: sw057 damp resistor fail";
CM_ SG_ 1486 PARK_sw057_resonanceDrift "Parking assist sensors: sw057 resonance drift";
CM_ SG_ 1486 PARK_sw057_sensorCRC "Parking assist sensors: sw057 sensor CRC";
CM_ SG_ 1486 PARK_sw057_recieveFailure "Parking assist sensors: sw057 recieve failure";
CM_ SG_ 1486 PARK_sw057_diagnosticTransferErr "Parking assist sensors: sw057 diagnostic transfer error";
CM_ SG_ 1486 PARK_sw058_linError "Parking assist sensors: sw058 lin error";
CM_ SG_ 1486 PARK_sw058_linBusError "Parking assist sensors: sw058 lin bus error";
CM_ SG_ 1486 PARK_sw058_linFrameCountError "Parking assist sensors: sw058 lin frame count error";
CM_ SG_ 1486 PARK_sw059_reverbPeriod "Parking assist sensors: sw059 reverb period";
CM_ SG_ 1486 PARK_sw059_reverbTime "Parking assist sensors: sw059 reverb time";
CM_ SG_ 1486 PARK_sw059_highAttenTime "Parking assist sensors: sw059 high atten time";
CM_ SG_ 1486 PARK_sw059_closeConstEcho "Parking assist sensors: sw059 close const echo";
CM_ SG_ 1486 PARK_sw059_lowAttenTime "Parking assist sensors: sw059 low atten time";
CM_ SG_ 1486 PARK_sw059_attenTimeJitter "Parking assist sensors: sw059 atten time jitter";
CM_ SG_ 1486 PARK_sw059_reverbFreqJitter "Parking assist sensors: sw059 reverb freq jitter";
CM_ SG_ 1486 PARK_sw061_voltage "Parking assist sensors: sw061 voltage";
CM_ SG_ 1486 PARK_sw063_voltage "Parking assist sensors: sw063 voltage";
CM_ SG_ 1486 PARK_sw064_faultCode "Parking assist sensors: sw064 fault code";
CM_ SG_ 1486 PARK_sw065_expectedCRC "Parking assist sensors: sw065 expected CRC";
CM_ SG_ 1486 PARK_sw065_calculatedCRC "Parking assist sensors: sw065 calculated CRC";
CM_ SG_ 1486 PARK_sw066_placeHolder "Parking assist sensors: sw066 place holder";
CM_ SG_ 1486 PARK_sw068_placeHolder "Parking assist sensors: sw068 place holder";
CM_ SG_ 1486 PARK_sw069_messageID "Parking assist sensors: sw069 message ID";
CM_ SG_ 1486 PARK_sw070_messageID "Parking assist sensors: sw070 message ID";
CM_ SG_ 1486 PARK_sw071_messageID "Parking assist sensors: sw071 message ID";
CM_ SG_ 1486 PARK_sw072_messageID "Parking assist sensors: sw072 message ID";
CM_ SG_ 1486 PARK_sw073_messageID "Parking assist sensors: sw073 message ID";
CM_ SG_ 1486 PARK_sw074_messageID "Parking assist sensors: sw074 message ID";
CM_ SG_ 1486 PARK_sw075_messageID "Parking assist sensors: sw075 message ID";
CM_ SG_ 1486 PARK_sw076_messageID "Parking assist sensors: sw076 message ID";
CM_ SG_ 1486 PARK_sw077_errorExp "Parking assist sensors: sw077 error exp";
CM_ SG_ 1486 PARK_sw077_errorRx "Parking assist sensors: sw077 error rx";
CM_ SG_ 1486 PARK_sw077_messageID "Parking assist sensors: sw077 message ID";
CM_ SG_ 1486 PARK_sw077_errorType "Parking assist sensors: sw077 error type";
CM_ SG_ 1486 PARK_sw078_errorExp "Parking assist sensors: sw078 error exp";
CM_ SG_ 1486 PARK_sw078_errorRx "Parking assist sensors: sw078 error rx";
CM_ SG_ 1486 PARK_sw078_messageID "Parking assist sensors: sw078 message ID";
CM_ SG_ 1486 PARK_sw078_errorType "Parking assist sensors: sw078 error type";
CM_ SG_ 1486 PARK_sw079_errorExp "Parking assist sensors: sw079 error exp";
CM_ SG_ 1486 PARK_sw079_errorRx "Parking assist sensors: sw079 error rx";
CM_ SG_ 1486 PARK_sw079_messageID "Parking assist sensors: sw079 message ID";
CM_ SG_ 1486 PARK_sw079_errorType "Parking assist sensors: sw079 error type";
CM_ SG_ 1486 PARK_sw080_errorExp "Parking assist sensors: sw080 error exp";
CM_ SG_ 1486 PARK_sw080_errorRx "Parking assist sensors: sw080 error rx";
CM_ SG_ 1486 PARK_sw080_messageID "Parking assist sensors: sw080 message ID";
CM_ SG_ 1486 PARK_sw080_errorType "Parking assist sensors: sw080 error type";
CM_ SG_ 1486 PARK_sw081_errorExp "Parking assist sensors: sw081 error exp";
CM_ SG_ 1486 PARK_sw081_errorRx "Parking assist sensors: sw081 error rx";
CM_ SG_ 1486 PARK_sw081_messageID "Parking assist sensors: sw081 message ID";
CM_ SG_ 1486 PARK_sw081_errorType "Parking assist sensors: sw081 error type";
CM_ SG_ 1486 PARK_sw082_errorExp "Parking assist sensors: sw082 error exp";
CM_ SG_ 1486 PARK_sw082_errorRx "Parking assist sensors: sw082 error rx";
CM_ SG_ 1486 PARK_sw082_messageID "Parking assist sensors: sw082 message ID";
CM_ SG_ 1486 PARK_sw082_errorType "Parking assist sensors: sw082 error type";
CM_ SG_ 1486 PARK_sw083_errorExp "Parking assist sensors: sw083 error exp";
CM_ SG_ 1486 PARK_sw083_errorRx "Parking assist sensors: sw083 error rx";
CM_ SG_ 1486 PARK_sw083_messageID "Parking assist sensors: sw083 message ID";
CM_ SG_ 1486 PARK_sw083_errorType "Parking assist sensors: sw083 error type";
CM_ SG_ 1486 PARK_sw084_errorExp "Parking assist sensors: sw084 error exp";
CM_ SG_ 1486 PARK_sw084_errorRx "Parking assist sensors: sw084 error rx";
CM_ SG_ 1486 PARK_sw084_messageID "Parking assist sensors: sw084 message ID";
CM_ SG_ 1486 PARK_sw084_errorType "Parking assist sensors: sw084 error type";
CM_ SG_ 1486 PARK_sw086_writeRetryCounter "Parking assist sensors: sw086 write retry counter";
CM_ SG_ 1486 PARK_sw086_readRetryCounter "Parking assist sensors: sw086 read retry counter";
CM_ SG_ 1486 PARK_sw086_currentErrorCode "Parking assist sensors: sw086 current error code";
CM_ SG_ 1486 PARK_sw087_s1_sensorType "Parking assist sensors: sw087 s1 sensor type; raw 3 = signal not available (SNA)";
CM_ SG_ 1486 PARK_sw087_s2_sensorType "Parking assist sensors: sw087 s2 sensor type; raw 3 = signal not available (SNA)";
CM_ SG_ 1486 PARK_sw087_s3_sensorType "Parking assist sensors: sw087 s3 sensor type; raw 3 = signal not available (SNA)";
CM_ SG_ 1486 PARK_sw087_s4_sensorType "Parking assist sensors: sw087 s4 sensor type; raw 3 = signal not available (SNA)";
CM_ SG_ 1486 PARK_sw087_s5_sensorType "Parking assist sensors: sw087 s5 sensor type; raw 3 = signal not available (SNA)";
CM_ SG_ 1486 PARK_sw087_s6_sensorType "Parking assist sensors: sw087 s6 sensor type; raw 3 = signal not available (SNA)";
CM_ SG_ 1486 PARK_sw087_s7_sensorType "Parking assist sensors: sw087 s7 sensor type; raw 3 = signal not available (SNA)";
CM_ SG_ 1486 PARK_sw087_s8_sensorType "Parking assist sensors: sw087 s8 sensor type; raw 3 = signal not available (SNA)";
CM_ SG_ 1486 PARK_sw087_s9_sensorType "Parking assist sensors: sw087 s9 sensor type; raw 3 = signal not available (SNA)";
CM_ SG_ 1486 PARK_sw087_s10_sensorType "Parking assist sensors: sw087 s10 sensor type; raw 3 = signal not available (SNA)";
CM_ SG_ 1486 PARK_sw087_s11_sensorType "Parking assist sensors: sw087 s11 sensor type; raw 3 = signal not available (SNA)";
CM_ SG_ 1486 PARK_sw087_s12_sensorType "Parking assist sensors: sw087 s12 sensor type; raw 3 = signal not available (SNA)";
CM_ BO_ 806 "Parking assist sensors message: info; frame length from the layout, not yet observed on a vehicle bus";
CM_ SG_ 806 PARK_infoIndex "Parking assist sensors: info index";
CM_ SG_ 806 PARK_infoBuildType "Parking assist sensors: info build type";
CM_ SG_ 806 PARK_infoComponentID "Parking assist sensors: info component ID";
CM_ SG_ 806 PARK_infoPcbaID "Parking assist sensors: info pcba ID";
CM_ SG_ 806 PARK_infoAssemblyID "Parking assist sensors: info assembly ID";
CM_ SG_ 806 PARK_infoUsageID "Parking assist sensors: info usage ID";
CM_ SG_ 806 PARK_infoApplicationCRC "Parking assist sensors: info application CRC";
CM_ SG_ 806 PARK_infoBootUdsProtoVersion "Parking assist sensors: info boot uds proto version";
CM_ SG_ 806 PARK_infoBootloaderCRC "Parking assist sensors: info bootloader CRC";
CM_ BO_ 846 "Parking assist sensors message: pas front middle; frame length from the layout, not yet observed on a vehicle bus";
CM_ SG_ 846 PARK_frontLeftMiddleRawDistData "Zone defined as -38 degrees -> +12 degrees, distance to object in units of centimeters; raw 255 = signal not available (SNA)";
CM_ SG_ 846 PARK_frontMiddleRawDistData "Zone defined as -12 degrees to +12 degrees, distance to object in units of centimeters; raw 255 = signal not available (SNA)";
CM_ SG_ 846 PARK_frontRightMiddleRawDistData "Zone defined +12 degrees to +38 degreees, distance to object in units of centimeters; raw 255 = signal not available (SNA)";
CM_ SG_ 846 PARK_pasFrontMiddleCounter "Parking assist sensors: pas front middle counter";
CM_ SG_ 846 PARK_pasFrontMiddleChecksum "Parking assist sensors: pas front middle checksum";
CM_ BO_ 862 "Parking assist sensors message: pas rear middle; frame length from the layout, not yet observed on a vehicle bus";
CM_ SG_ 862 PARK_rearLeftMiddleRawDistData "Zone defined as -124 degrees to -166 degrees, distance to object in units of centimeters; raw 255 = signal not available (SNA)";
CM_ SG_ 862 PARK_rearMiddleRawDistData "Zone defined as -166 degrees to +166 degrees, distance to object in units of centimeters; raw 255 = signal not available (SNA)";
CM_ SG_ 862 PARK_rearRightMiddleRawDistData "Zone defined as +166 degrees to +124 degrees, distance to object in units of centimeters; raw 255 = signal not available (SNA)";
CM_ SG_ 862 PARK_pasRearMiddleCounter "Parking assist sensors: pas rear middle counter";
CM_ SG_ 862 PARK_pasRearMiddleChecksum "Parking assist sensors: pas rear middle checksum";
CM_ BO_ 926 "Parking assist sensors message: pas sides; frame length from the layout, not yet observed on a vehicle bus";
CM_ SG_ 926 PARK_rightSideFrontRawDistData "Right side (from inside the car) towards the front of the car (split evenly between axles); raw 255 = signal not available (SNA)";
CM_ SG_ 926 PARK_rightSideRearRawDistData "Right side (from inside the car) towards the rear of the car (split evenly between axles); raw 255 = signal not available (SNA)";
CM_ SG_ 926 PARK_leftSideFrontRawDistData "Left side (from inside the car) towards the front of the car (split evenly between axles); raw 255 = signal not available (SNA)";
CM_ SG_ 926 PARK_leftSideRearRawDistData "Left side (from inside the car) towards the rear of the car (split evenly between axles); raw 255 = signal not available (SNA)";
CM_ SG_ 926 PARK_pasSidesCounter "Parking assist sensors: pas sides counter";
CM_ SG_ 926 PARK_pasSidesChecksum "Parking assist sensors: pas sides checksum";
CM_ BO_ 606 "Parking assist sensors message: psc env slot; frame length from the layout, not yet observed on a vehicle bus";
CM_ SG_ 606 PARK_pscEnvSlotType "Parking assist sensors: psc env slot type";
CM_ SG_ 606 PARK_pscLeftParallelObj1X "Parking assist sensors: psc left parallel obj1 x; raw 2047 = signal not available (SNA)";
CM_ SG_ 606 PARK_pscLeftParallelObj1Y "Parking assist sensors: psc left parallel obj1 y; raw 2047 = signal not available (SNA)";
CM_ SG_ 606 PARK_pscLeftParallelObj1Alpha "Parking assist sensors: psc left parallel obj1 alpha; raw 127 = signal not available (SNA)";
CM_ SG_ 606 PARK_pscLeftParallelObj2Y "Parking assist sensors: psc left parallel obj2 y; raw 2047 = signal not available (SNA)";
CM_ SG_ 606 PARK_pscLeftParallelObj2X "Parking assist sensors: psc left parallel obj2 x; raw 2047 = signal not available (SNA)";
CM_ SG_ 606 PARK_pscLeftParallelObj2Alpha "Parking assist sensors: psc left parallel obj2 alpha; raw 127 = signal not available (SNA)";
CM_ SG_ 606 PARK_pscLeftCrossObj1X "Parking assist sensors: psc left cross obj1 x; raw 2047 = signal not available (SNA)";
CM_ SG_ 606 PARK_pscLeftCrossObj1Y "Parking assist sensors: psc left cross obj1 y; raw 2047 = signal not available (SNA)";
CM_ SG_ 606 PARK_pscLeftCrossObj1Alpha "Parking assist sensors: psc left cross obj1 alpha; raw 127 = signal not available (SNA)";
CM_ SG_ 606 PARK_pscLeftCrossObj2Y "Parking assist sensors: psc left cross obj2 y; raw 2047 = signal not available (SNA)";
CM_ SG_ 606 PARK_pscLeftCrossObj2X "Parking assist sensors: psc left cross obj2 x; raw 2047 = signal not available (SNA)";
CM_ SG_ 606 PARK_pscLeftCrossObj2Alpha "Parking assist sensors: psc left cross obj2 alpha; raw 127 = signal not available (SNA)";
CM_ SG_ 606 PARK_pscRightParallelObj1X "Parking assist sensors: psc right parallel obj1 x; raw 2047 = signal not available (SNA)";
CM_ SG_ 606 PARK_pscRightParallelObj1Y "Parking assist sensors: psc right parallel obj1 y; raw 2047 = signal not available (SNA)";
CM_ SG_ 606 PARK_pscRightParallelObj1Alpha "Parking assist sensors: psc right parallel obj1 alpha; raw 127 = signal not available (SNA)";
CM_ SG_ 606 PARK_pscRightParallelObj2Y "Parking assist sensors: psc right parallel obj2 y; raw 2047 = signal not available (SNA)";
CM_ SG_ 606 PARK_pscRightParallelObj2X "Parking assist sensors: psc right parallel obj2 x; raw 2047 = signal not available (SNA)";
CM_ SG_ 606 PARK_pscRightParallelObj2Alpha "Parking assist sensors: psc right parallel obj2 alpha; raw 127 = signal not available (SNA)";
CM_ SG_ 606 PARK_pscRightCrossObj1X "Parking assist sensors: psc right cross obj1 x; raw 2047 = signal not available (SNA)";
CM_ SG_ 606 PARK_pscRightCrossObj1Y "Parking assist sensors: psc right cross obj1 y; raw 2047 = signal not available (SNA)";
CM_ SG_ 606 PARK_pscRightCrossObj1Alpha "Parking assist sensors: psc right cross obj1 alpha; raw 127 = signal not available (SNA)";
CM_ SG_ 606 PARK_pscRightCrossObj2Y "Parking assist sensors: psc right cross obj2 y; raw 2047 = signal not available (SNA)";
CM_ SG_ 606 PARK_pscRightCrossObj2X "Parking assist sensors: psc right cross obj2 x; raw 2047 = signal not available (SNA)";
CM_ SG_ 606 PARK_pscRightCrossObj2Alpha "Parking assist sensors: psc right cross obj2 alpha; raw 127 = signal not available (SNA)";
CM_ BO_ 542 "Parking assist sensors message: psc status; frame length from the layout, not yet observed on a vehicle bus";
CM_ SG_ 542 PARK_pscParkStatus "Parking assist sensors: psc park status; raw 7 = signal not available (SNA)";
CM_ SG_ 542 PARK_pscParkAbortReason "Parking assist sensors: psc park abort reason; raw 31 = signal not available (SNA)";
CM_ SG_ 542 PARK_pscParallelSpace "The existence and type of a parallel parking slot identified by the ultrasonics.";
CM_ SG_ 542 PARK_pscCrossSpace "The type and existence of perpendicular parking slot identified through the ultrasonics";
CM_ SG_ 542 PARK_pscParallelRightParkable "Whether or not there is a valid path into a parallel parking slot on the right; raw 3 = signal not available (SNA)";
CM_ SG_ 542 PARK_pscParallelLeftParkable "Whether or not there is a valid path into a parallel parking slot on the left; raw 3 = signal not available (SNA)";
CM_ SG_ 542 PARK_pscCrossRightParkable "Parking assist sensors: psc cross right parkable; raw 3 = signal not available (SNA)";
CM_ SG_ 542 PARK_pscMaxVelocity "Parking assist sensors: psc max velocity; raw 63 = signal not available (SNA)";
CM_ SG_ 542 PARK_pscCrossLeftParkable "Parking assist sensors: psc cross left parkable; raw 3 = signal not available (SNA)";
CM_ SG_ 542 PARK_pscParkInstruction "The control request from PARK ECU during autopark manuever; raw 7 = signal not available (SNA)";
CM_ SG_ 542 PARK_pscManeuverDistance "Real time updated path length from center of vehicle reference frame to desired center of vehicle at end of current parking manuever; raw 2047 = signal not available (SNA)";
CM_ SG_ 542 PARK_pscAngleActive "Parking assist sensors: psc angle active";
CM_ SG_ 542 PARK_pscAngleRequest "Parking assist sensors: psc angle request";
CM_ SG_ 542 PARK_pscStatusCounter "Parking assist sensors: psc status counter";
CM_ SG_ 542 PARK_pscStatusChecksum "Parking assist sensors: psc status checksum";
CM_ BO_ 590 "Parking assist sensors message: psc veh slot; frame length from the layout, not yet observed on a vehicle bus";
CM_ SG_ 590 PARK_pscVehSlotType "Parking assist sensors: psc veh slot type";
CM_ SG_ 590 PARK_pscLeftParallelVehX "Parking assist sensors: psc left parallel veh x; raw 2047 = signal not available (SNA)";
CM_ SG_ 590 PARK_pscLeftParallelVehY "Parking assist sensors: psc left parallel veh y; raw 2047 = signal not available (SNA)";
CM_ SG_ 590 PARK_pscLeftParallelPsi "Parking assist sensors: psc left parallel psi; raw 8191 = signal not available (SNA)";
CM_ SG_ 590 PARK_pscLeftParallelSizeX "Parking assist sensors: psc left parallel size x; raw 255 = signal not available (SNA)";
CM_ SG_ 590 PARK_pscLeftParallelSizeY "Parking assist sensors: psc left parallel size y; raw 255 = signal not available (SNA)";
CM_ SG_ 590 PARK_pscLeftCrossVehX "Parking assist sensors: psc left cross veh x; raw 2047 = signal not available (SNA)";
CM_ SG_ 590 PARK_pscLeftCrossVehY "Parking assist sensors: psc left cross veh y; raw 2047 = signal not available (SNA)";
CM_ SG_ 590 PARK_pscLeftCrossPsi "Parking assist sensors: psc left cross psi; raw 8191 = signal not available (SNA)";
CM_ SG_ 590 PARK_pscLeftCrossSizeX "Parking assist sensors: psc left cross size x; raw 255 = signal not available (SNA)";
CM_ SG_ 590 PARK_pscLeftCrossSizeY "Parking assist sensors: psc left cross size y; raw 255 = signal not available (SNA)";
CM_ SG_ 590 PARK_pscRightParallelVehX "Parking assist sensors: psc right parallel veh x; raw 2047 = signal not available (SNA)";
CM_ SG_ 590 PARK_pscRightParallelVehY "Parking assist sensors: psc right parallel veh y; raw 2047 = signal not available (SNA)";
CM_ SG_ 590 PARK_pscRightParallelPsi "Parking assist sensors: psc right parallel psi; raw 8191 = signal not available (SNA)";
CM_ SG_ 590 PARK_pscRightParallelSizeX "Parking assist sensors: psc right parallel size x; raw 255 = signal not available (SNA)";
CM_ SG_ 590 PARK_pscRightParallelSizeY "Parking assist sensors: psc right parallel size y; raw 255 = signal not available (SNA)";
CM_ SG_ 590 PARK_pscRightCrossVehX "Parking assist sensors: psc right cross veh x; raw 2047 = signal not available (SNA)";
CM_ SG_ 590 PARK_pscRightCrossVehY "Parking assist sensors: psc right cross veh y; raw 2047 = signal not available (SNA)";
CM_ SG_ 590 PARK_pscRightCrossPsi "Parking assist sensors: psc right cross psi; raw 8191 = signal not available (SNA)";
CM_ SG_ 590 PARK_pscRightCrossSizeX "Parking assist sensors: psc right cross size x; raw 255 = signal not available (SNA)";
CM_ SG_ 590 PARK_pscRightCrossSizeY "Parking assist sensors: psc right cross size y; raw 255 = signal not available (SNA)";
CM_ BO_ 526 "Parking assist sensors message: sdi front; frame length from the layout, not yet observed on a vehicle bus";
CM_ SG_ 526 PARK_sdiSensor1RawDistData "Parking assist sensors: sdi sensor1 raw dist data; raw 511 = signal not available (SNA)";
CM_ SG_ 526 PARK_sdiSensor2RawDistData "Parking assist sensors: sdi sensor2 raw dist data; raw 511 = signal not available (SNA)";
CM_ SG_ 526 PARK_sdiSensor3RawDistData "Parking assist sensors: sdi sensor3 raw dist data; raw 511 = signal not available (SNA)";
CM_ SG_ 526 PARK_sdiSensor4RawDistData "Parking assist sensors: sdi sensor4 raw dist data; raw 511 = signal not available (SNA)";
CM_ SG_ 526 PARK_sdiSensor5RawDistData "Parking assist sensors: sdi sensor5 raw dist data; raw 511 = signal not available (SNA)";
CM_ SG_ 526 PARK_sdiSensor6RawDistData "Parking assist sensors: sdi sensor6 raw dist data; raw 511 = signal not available (SNA)";
CM_ SG_ 526 PARK_sdiFrontCounter "Parking assist sensors: sdi front counter";
CM_ SG_ 526 PARK_sdiFrontChecksum "Parking assist sensors: sdi front checksum";
CM_ BO_ 558 "Parking assist sensors message: sdi rear; frame length from the layout, not yet observed on a vehicle bus";
CM_ SG_ 558 PARK_sdiSensor7RawDistData "Parking assist sensors: sdi sensor7 raw dist data; raw 511 = signal not available (SNA)";
CM_ SG_ 558 PARK_sdiSensor8RawDistData "Parking assist sensors: sdi sensor8 raw dist data; raw 511 = signal not available (SNA)";
CM_ SG_ 558 PARK_sdiSensor9RawDistData "Parking assist sensors: sdi sensor9 raw dist data; raw 511 = signal not available (SNA)";
CM_ SG_ 558 PARK_sdiSensor10RawDistData "Parking assist sensors: sdi sensor10 raw dist data; raw 511 = signal not available (SNA)";
CM_ SG_ 558 PARK_sdiSensor11RawDistData "Parking assist sensors: sdi sensor11 raw dist data; raw 511 = signal not available (SNA)";
CM_ SG_ 558 PARK_sdiSensor12RawDistData "Parking assist sensors: sdi sensor12 raw dist data; raw 511 = signal not available (SNA)";
CM_ SG_ 558 PARK_sdiRearCounter "Parking assist sensors: sdi rear counter";
CM_ SG_ 558 PARK_sdiRearChecksum "Parking assist sensors: sdi rear checksum";
CM_ BO_ 814 "Parking assist sensors message: sensor status front; frame length from the layout, not yet observed on a vehicle bus";
CM_ SG_ 814 PARK_frontRightSensorState "Reports the state of the front right ultrasonic sensor; raw 3 = signal not available (SNA)";
CM_ SG_ 814 PARK_frontRightMiddleSensorState "Reports the state of the front right middle ultrasonic sensor; raw 3 = signal not available (SNA)";
CM_ SG_ 814 PARK_frontLeftMiddleSensorState "Reports the state of the front left middle ultrasonic sensor; raw 3 = signal not available (SNA)";
CM_ SG_ 814 PARK_frontLeftSensorState "Reports the state of the front left ultrasonic sensor; raw 3 = signal not available (SNA)";
CM_ SG_ 814 PARK_frontLeftRawDistData "Zone defined as -90 degrees -> -38 degrees, distance to object in units of centimeters; raw 255 = signal not available (SNA)";
CM_ SG_ 814 PARK_frontRightRawDistData "Zone defined as +38 degrees -> +90 degrees, distance to object in units of centimeters; raw 255 = signal not available (SNA)";
CM_ SG_ 814 PARK_systemStatusFront "Parking assist sensors: system status front; raw 3 = signal not available (SNA)";
CM_ SG_ 814 PARK_frontDtcPresent "Parking assist sensors: front dtc present; raw 3 = signal not available (SNA)";
CM_ SG_ 814 PARK_sensorStatusFrontCounter "Parking assist sensors: sensor status front counter";
CM_ SG_ 814 PARK_sensorStatusFrontChecksum "Parking assist sensors: sensor status front checksum";
CM_ BO_ 830 "Parking assist sensors message: sensor status rear; frame length from the layout, not yet observed on a vehicle bus";
CM_ SG_ 830 PARK_rearRightSensorState "Reports the state of the rear right ultrasonic sensor; raw 3 = signal not available (SNA)";
CM_ SG_ 830 PARK_rearRightMiddleSensorState "Reports the state of the rear right middle ultrasonic sensor; raw 3 = signal not available (SNA)";
CM_ SG_ 830 PARK_rearLeftMiddleSensorState "Reports the state of the rear left middle ultrasonic sensor; raw 3 = signal not available (SNA)";
CM_ SG_ 830 PARK_rearLeftSensorState "Reports the state of the rear left ultrasonic sensor; raw 3 = signal not available (SNA)";
CM_ SG_ 830 PARK_rearLeftRawDistData "Zone defined as -90 degrees to -125 degrees, distance to object in units of centimeters; raw 255 = signal not available (SNA)";
CM_ SG_ 830 PARK_rearRightRawDistData "Zone defined as +125 degrees to +90 degrees, distance to object in units of centimeters; raw 255 = signal not available (SNA)";
CM_ SG_ 830 PARK_systemStatusRear "Parking assist sensors: system status rear; raw 3 = signal not available (SNA)";
CM_ SG_ 830 PARK_rearDtcPresent "Parking assist sensors: rear dtc present; raw 3 = signal not available (SNA)";
CM_ SG_ 830 PARK_sensorStatusRearCounter "Parking assist sensors: sensor status rear counter";
CM_ SG_ 830 PARK_sensorStatusRearChecksum "Parking assist sensors: sensor status rear checksum";
CM_ BO_ 798 "Parking assist sensors message: status; frame length from the layout, not yet observed on a vehicle bus";
CM_ SG_ 798 PARK_status "Indicates status of park assist function; raw 3 = signal not available (SNA)";
CM_ SG_ 798 PARK_serviceRequest "Indicates whether or not PARK sensors/ECU require service; raw 3 = signal not available (SNA)";
CM_ SG_ 798 PARK_systemDtcPresent "Boolean indicating whether or not there is a DTC present; raw 3 = signal not available (SNA)";
CM_ SG_ 798 PARK_statusCounter "Parking assist sensors: status counter";
CM_ SG_ 798 PARK_statusChecksum "Parking assist sensors: status checksum";
CM_ SG_ 798 PARK_majorVersion "Parking assist sensors: major version; raw 255 = signal not available (SNA)";
CM_ SG_ 798 PARK_minorVersion "Parking assist sensors: minor version; raw 255 = signal not available (SNA)";
CM_ SG_ 798 PARK_subMinorVersion "Parking assist sensors: sub minor version; raw 255 = signal not available (SNA)";
CM_ BO_ 782 "Parking assist sensors message: status2; frame length from the layout, not yet observed on a vehicle bus";
CM_ SG_ 782 PARK_frontSVACharID "Parking assist sensors: front SVA char ID";
CM_ SG_ 782 PARK_pscRightCurbType "The type of curb for the parallel parking slot on the right side.";
CM_ SG_ 782 PARK_rearSVACharID "Parking assist sensors: rear SVA char ID";
CM_ SG_ 782 PARK_pscLeftCurbType "The type of curb identified for a parallel parking space on the left.";
CM_ SG_ 782 PARK_autoCalComplete "Parking assist sensors: auto cal complete";
CM_ SG_ 782 PARK_geometryType "Parking assist sensors: geometry type";
CM_ SG_ 782 PARK_tireFitment "Parking assist sensors: tire fitment; raw 3 = signal not available (SNA)";
CM_ SG_ 782 PARK_rackDetected "Parking assist sensors: rack detected; raw 3 = signal not available (SNA)";
CM_ SG_ 782 PARK_sdiActive "Whether or not the raw sensor measurements from the ultrasonics are present and valid";
CM_ SG_ 782 PARK_sdiNoise "The output of the noise detection algorithm for raw sensor measurements, indicates if the measurements are degraded due to ambient noise; raw 3 = signal not available (SNA)";
CM_ SG_ 782 PARK_sdiBlindSpotRight "The output of the PARK ECU blindspot algorithm on the right side of the car, indicates the presence of a vehicle; raw 3 = signal not available (SNA)";
CM_ SG_ 782 PARK_sdiBlindSpotLeft "The output of the PARK ECU blindspot algorithm on the left side of the car, indicates the presence of a vehicle; raw 3 = signal not available (SNA)";
CM_ SG_ 782 PARK_sensorType "Parking assist sensors: sensor type; raw 3 = signal not available (SNA)";
CM_ SG_ 782 PARK_status2Counter "Parking assist sensors: status2 counter";
CM_ SG_ 782 PARK_status2Checksum "Parking assist sensors: status2 checksum";
CM_ BO_ 1630 "Parking assist sensors message: uds response; frame length from the layout, not yet observed on a vehicle bus";
CM_ SG_ 1630 PARK_udsResponseData "Parking assist sensors: uds response data";
CM_ BO_ 894 "Parking assist sensors message: warning matrix; frame length from the layout, not yet observed on a vehicle bus";
CM_ SG_ 894 PARK_matrixIndex "Parking assist sensors: matrix index";
CM_ SG_ 894 PARK_a001_s1_overTemp "Parking assist sensors: a001 s1 over temp";
CM_ SG_ 894 PARK_a002_s1_internalFail "Parking assist sensors: a002 s1 internal fail";
CM_ SG_ 894 PARK_a003_s1_linCommError "Parking assist sensors: a003 s1 lin comm error";
CM_ SG_ 894 PARK_a004_s1_blocked "Parking assist sensors: a004 s1 blocked";
CM_ SG_ 894 PARK_a005_s1_crossTalk "Parking assist sensors: a005 s1 cross talk";
CM_ SG_ 894 PARK_a006_s2_overTemp "Parking assist sensors: a006 s2 over temp";
CM_ SG_ 894 PARK_a007_s2_internalFail "Parking assist sensors: a007 s2 internal fail";
CM_ SG_ 894 PARK_a008_s2_linCommError "Parking assist sensors: a008 s2 lin comm error";
CM_ SG_ 894 PARK_a009_s2_blocked "Parking assist sensors: a009 s2 blocked";
CM_ SG_ 894 PARK_a010_s2_crossTalk "Parking assist sensors: a010 s2 cross talk";
CM_ SG_ 894 PARK_a011_s3_overTemp "Parking assist sensors: a011 s3 over temp";
CM_ SG_ 894 PARK_a012_s3_internalFail "Parking assist sensors: a012 s3 internal fail";
CM_ SG_ 894 PARK_a013_s3_linCommError "Parking assist sensors: a013 s3 lin comm error";
CM_ SG_ 894 PARK_a014_s3_blocked "Parking assist sensors: a014 s3 blocked";
CM_ SG_ 894 PARK_a015_s3_crossTalk "Parking assist sensors: a015 s3 cross talk";
CM_ SG_ 894 PARK_a016_s4_overTemp "Parking assist sensors: a016 s4 over temp";
CM_ SG_ 894 PARK_a017_s4_internalFail "Parking assist sensors: a017 s4 internal fail";
CM_ SG_ 894 PARK_a018_s4_linCommError "Parking assist sensors: a018 s4 lin comm error";
CM_ SG_ 894 PARK_a019_s4_blocked "Parking assist sensors: a019 s4 blocked";
CM_ SG_ 894 PARK_a020_s4_crossTalk "Parking assist sensors: a020 s4 cross talk";
CM_ SG_ 894 PARK_a021_s5_overTemp "Parking assist sensors: a021 s5 over temp";
CM_ SG_ 894 PARK_a022_s5_internalFail "Parking assist sensors: a022 s5 internal fail";
CM_ SG_ 894 PARK_a023_s5_linCommError "Parking assist sensors: a023 s5 lin comm error";
CM_ SG_ 894 PARK_a024_s5_blocked "Parking assist sensors: a024 s5 blocked";
CM_ SG_ 894 PARK_a025_s5_crossTalk "Parking assist sensors: a025 s5 cross talk";
CM_ SG_ 894 PARK_a026_s6_overTemp "Parking assist sensors: a026 s6 over temp";
CM_ SG_ 894 PARK_a027_s6_internalFail "Parking assist sensors: a027 s6 internal fail";
CM_ SG_ 894 PARK_a028_s6_linCommError "Parking assist sensors: a028 s6 lin comm error";
CM_ SG_ 894 PARK_a029_s6_blocked "Parking assist sensors: a029 s6 blocked";
CM_ SG_ 894 PARK_a030_s6_crossTalk "Parking assist sensors: a030 s6 cross talk";
CM_ SG_ 894 PARK_a031_s7_overTemp "Parking assist sensors: a031 s7 over temp";
CM_ SG_ 894 PARK_a032_s7_internalFail "Parking assist sensors: a032 s7 internal fail";
CM_ SG_ 894 PARK_a033_s7_linCommError "Parking assist sensors: a033 s7 lin comm error";
CM_ SG_ 894 PARK_a034_s7_blocked "Parking assist sensors: a034 s7 blocked";
CM_ SG_ 894 PARK_a035_s7_crossTalk "Parking assist sensors: a035 s7 cross talk";
CM_ SG_ 894 PARK_a036_s8_overTemp "Parking assist sensors: a036 s8 over temp";
CM_ SG_ 894 PARK_a037_s8_internalFail "Parking assist sensors: a037 s8 internal fail";
CM_ SG_ 894 PARK_a038_s8_linCommError "Parking assist sensors: a038 s8 lin comm error";
CM_ SG_ 894 PARK_a039_s8_blocked "Parking assist sensors: a039 s8 blocked";
CM_ SG_ 894 PARK_a040_s8_crossTalk "Parking assist sensors: a040 s8 cross talk";
CM_ SG_ 894 PARK_a041_s9_overTemp "Parking assist sensors: a041 s9 over temp";
CM_ SG_ 894 PARK_a042_s9_internalFail "Parking assist sensors: a042 s9 internal fail";
CM_ SG_ 894 PARK_a043_s9_linCommError "Parking assist sensors: a043 s9 lin comm error";
CM_ SG_ 894 PARK_a044_s9_blocked "Parking assist sensors: a044 s9 blocked";
CM_ SG_ 894 PARK_a045_s9_crossTalk "Parking assist sensors: a045 s9 cross talk";
CM_ SG_ 894 PARK_a046_s10_overTemp "Parking assist sensors: a046 s10 over temp";
CM_ SG_ 894 PARK_a047_s10_internalFail "Parking assist sensors: a047 s10 internal fail";
CM_ SG_ 894 PARK_a048_s10_linCommError "Parking assist sensors: a048 s10 lin comm error";
CM_ SG_ 894 PARK_a049_s10_blocked "Parking assist sensors: a049 s10 blocked";
CM_ SG_ 894 PARK_a050_s10_crossTalk "Parking assist sensors: a050 s10 cross talk";
CM_ SG_ 894 PARK_a051_s11_overTemp "Parking assist sensors: a051 s11 over temp";
CM_ SG_ 894 PARK_a052_s11_internalFail "Parking assist sensors: a052 s11 internal fail";
CM_ SG_ 894 PARK_a053_s11_linCommError "Parking assist sensors: a053 s11 lin comm error";
CM_ SG_ 894 PARK_a054_s11_blocked "Parking assist sensors: a054 s11 blocked";
CM_ SG_ 894 PARK_a055_s11_crossTalk "Parking assist sensors: a055 s11 cross talk";
CM_ SG_ 894 PARK_a056_s12_overTemp "Parking assist sensors: a056 s12 over temp";
CM_ SG_ 894 PARK_a057_s12_internalFail "Parking assist sensors: a057 s12 internal fail";
CM_ SG_ 894 PARK_a058_s12_linCommError "Parking assist sensors: a058 s12 lin comm error";
CM_ SG_ 894 PARK_a059_s12_blocked "Parking assist sensors: a059 s12 blocked";
CM_ SG_ 894 PARK_a060_s12_crossTalk "Parking assist sensors: a060 s12 cross talk";
CM_ SG_ 894 PARK_a061_ecuUnderVoltage "Parking assist sensors: a061 ecu under voltage";
CM_ SG_ 894 PARK_a062_ecuOverVoltage "Parking assist sensors: a062 ecu over voltage";
CM_ SG_ 894 PARK_a063_sensorVoltage "Parking assist sensors: a063 sensor voltage";
CM_ SG_ 894 PARK_a064_ecuFault "Parking assist sensors: a064 ecu fault";
CM_ SG_ 894 PARK_a065_crcFault "Parking assist sensors: a065 crc fault";
CM_ SG_ 894 PARK_a066_calibrationMissing "Parking assist sensors: a066 calibration missing";
CM_ SG_ 894 PARK_a067_privateCANBusOff "Parking assist sensors: a067 private CAN bus off";
CM_ SG_ 894 PARK_a068_hardwareWatchDog "Parking assist sensors: a068 hardware watch dog";
CM_ SG_ 894 PARK_a069_dasMia "Parking assist sensors: a069 das mia";
CM_ SG_ 894 PARK_a070_sccmMia "Parking assist sensors: a070 sccm mia";
CM_ SG_ 894 PARK_a071_diMia "Parking assist sensors: a071 di mia";
CM_ SG_ 894 PARK_a072_epasMia "Parking assist sensors: a072 epas mia";
CM_ SG_ 894 PARK_a073_epbMia "Parking assist sensors: a073 epb mia";
CM_ SG_ 894 PARK_a074_espMia "Parking assist sensors: a074 esp mia";
CM_ SG_ 894 PARK_a075_rcmMia "Parking assist sensors: a075 rcm mia";
CM_ SG_ 894 PARK_a076_vcFrontMia "Parking assist sensors: a076 vc front mia";
CM_ SG_ 894 PARK_a077_dasError "Parking assist sensors: a077 das error";
CM_ SG_ 894 PARK_a078_diError "Parking assist sensors: a078 di error";
CM_ SG_ 894 PARK_a079_epasError "Parking assist sensors: a079 epas error";
CM_ SG_ 894 PARK_a080_epbError "Parking assist sensors: a080 epb error";
CM_ SG_ 894 PARK_a081_espError "Parking assist sensors: a081 esp error";
CM_ SG_ 894 PARK_a082_rcmError "Parking assist sensors: a082 rcm error";
CM_ SG_ 894 PARK_a083_vcFrontError "Parking assist sensors: a083 vc front error";
CM_ SG_ 894 PARK_a084_sccmError "Parking assist sensors: a084 sccm error";
CM_ SG_ 894 PARK_a085_watchdogReset "Parking assist sensors: a085 watchdog reset";
CM_ SG_ 894 PARK_a086_nvmFault "Parking assist sensors: a086 nvm fault";
CM_ SG_ 894 PARK_a087_sensorMismatchError "Parking assist sensors: a087 sensor mismatch error";
CM_ BO_ 1365 "Radar message: alert log; frame length from the layout, not yet observed on a vehicle bus";
CM_ SG_ 1365 RADC_alertID "Radar: alert ID";
CM_ SG_ 1365 RADC_alertState "Radar: alert state";
CM_ SG_ 1365 RADC_a002_ecuAdcErrType "Radar: a002 ecu adc err type";
CM_ SG_ 1365 RADC_a008_interLockErrType "Radar: a008 inter lock err type";
CM_ SG_ 1365 RADC_a011_ecuMcemErrType "Radar: a011 ecu mcem err type";
CM_ SG_ 1365 RADC_a013_ecuWdgErrType "Radar: a013 ecu wdg err type";
CM_ SG_ 1365 RADC_a016_adcOverVoltType "Radar: a016 adc over volt type";
CM_ SG_ 1365 RADC_a016_adcVoltage "Radar: a016 adc voltage";
CM_ SG_ 1365 RADC_a017_adcUnderVoltType "Radar: a017 adc under volt type";
CM_ SG_ 1365 RADC_a017_adcVoltage "Radar: a017 adc voltage";
CM_ SG_ 1365 RADC_a019_internalSWFaultType "Radar: a019 internal SW fault type";
CM_ SG_ 1365 RADC_a019_internalSWFaultCoreID "Radar: a019 internal SW fault core ID";
CM_ SG_ 1365 RADC_a020_ecuTemp "Radar: a020 ecu temp";
CM_ SG_ 1365 RADC_a023_ecuTemp "Radar: a023 ecu temp";
CM_ SG_ 1365 RADC_a025_ecuVoltage "Radar: a025 ecu voltage";
CM_ SG_ 1365 RADC_a026_ecuVoltage "Radar: a026 ecu voltage";
CM_ SG_ 1365 RADC_a027_nvmFailureType "Radar: a027 nvm failure type";
CM_ SG_ 1365 RADC_a028_rfComRegCheckFail "Radar: a028 rf com reg check fail";
CM_ SG_ 1365 RADC_a029_rhcChirpMonErrType "Radar: a029 rhc chirp mon err type";
CM_ SG_ 1365 RADC_a029_rhcRxLongTermErrType "Radar: a029 rhc rx long term err type";
CM_ SG_ 1365 RADC_a029_rhcRxErrType "Radar: a029 rhc rx err type";
CM_ SG_ 1365 RADC_a029_rhcVcoPowerErrType "Radar: a029 rhc vco power err type";
CM_ SG_ 1365 RADC_a029_rhcSp1ErrType "Radar: a029 rhc sp1 err type";
CM_ SG_ 1365 RADC_a029_rhcFdcErrType "Radar: a029 rhc fdc err type";
CM_ SG_ 1365 RADC_a030_rspErrType "Radar: a030 rsp err type";
CM_ SG_ 1365 RADC_a031_horizMisalignAngle "Radar: a031 horiz misalign angle";
CM_ SG_ 1365 RADC_a031_vertMisalignAngle "Radar: a031 vert misalign angle";
CM_ SG_ 1365 RADC_a032_blockageType "Radar: a032 blockage type";
CM_ SG_ 1365 RADC_a032_block_SPMBlockageState "Radar: a032 block SPM blockage state";
CM_ SG_ 1365 RADC_a032_block_dummy "Radar: a032 block dummy";
CM_ SG_ 1365 RADC_a032_block_SPMSelfTestState "Radar: a032 block SPM self test state";
CM_ SG_ 1365 RADC_a032_block_ucEstiRange "Radar: a032 block uc esti range";
CM_ SG_ 1365 RADC_a032_block_ucEstiRangeConf "Radar: a032 block uc esti range conf";
CM_ SG_ 1365 RADC_a032_block_ucEstiRangeProb "Radar: a032 block uc esti range prob";
CM_ SG_ 1365 RADC_a032_block_ucTimeoutBlkConf "Radar: a032 block uc timeout blk conf";
CM_ SG_ 1365 RADC_a035_msgId "Radar: a035 msg id";
CM_ SG_ 1365 RADC_a036_msgId "Radar: a036 msg id";
CM_ SG_ 1365 RADC_a037_msgId "Radar: a037 msg id";
CM_ SG_ 1365 RADC_a038_msgId "Radar: a038 msg id";
CM_ SG_ 1365 RADC_a039_msgId "Radar: a039 msg id";
CM_ SG_ 1365 RADC_a040_msgId "Radar: a040 msg id";
CM_ SG_ 1365 RADC_a041_vinErrType "Radar: a041 vin err type";
CM_ SG_ 1365 RADC_a041_vinErrExp "Radar: a041 vin err exp";
CM_ SG_ 1365 RADC_a041_vinErrRx "Radar: a041 vin err rx";
CM_ SG_ 1365 RADC_a041_msgId "Radar: a041 msg id";
CM_ SG_ 1365 RADC_a042_carConfigErrType "Radar: a042 car config err type";
CM_ SG_ 1365 RADC_a042_carConfigErrExp "Radar: a042 car config err exp";
CM_ SG_ 1365 RADC_a042_carConfigErrRx "Radar: a042 car config err rx";
CM_ SG_ 1365 RADC_a042_msgId "Radar: a042 msg id";
CM_ SG_ 1365 RADC_a043_inertialSignalsErrType "Radar: a043 inertial signals err type";
CM_ SG_ 1365 RADC_a043_inertialSignalsErrExp "Radar: a043 inertial signals err exp";
CM_ SG_ 1365 RADC_a043_inertialSignalsErrRx "Radar: a043 inertial signals err rx";
CM_ SG_ 1365 RADC_a043_msgId "Radar: a043 msg id";
CM_ SG_ 1365 RADC_a044_stwAngleErrType "Radar: a044 stw angle err type";
CM_ SG_ 1365 RADC_a044_stwAngleErrExp "Radar: a044 stw angle err exp";
CM_ SG_ 1365 RADC_a044_stwAngleErrRx "Radar: a044 stw angle err rx";
CM_ SG_ 1365 RADC_a044_msgId "Radar: a044 msg id";
CM_ SG_ 1365 RADC_a045_vehicleStateErrType "Radar: a045 vehicle state err type";
CM_ SG_ 1365 RADC_a045_vehicleStateErrExp "Radar: a045 vehicle state err exp";
CM_ SG_ 1365 RADC_a045_vehicleStateErrRx "Radar: a045 vehicle state err rx";
CM_ SG_ 1365 RADC_a045_msgId "Radar: a045 msg id";
CM_ SG_ 1365 RADC_a046_wheelSpeedsErrType "Radar: a046 wheel speeds err type";
CM_ SG_ 1365 RADC_a046_wheelSpeedsErrExp "Radar: a046 wheel speeds err exp";
CM_ SG_ 1365 RADC_a046_wheelSpeedsErrRx "Radar: a046 wheel speeds err rx";
CM_ SG_ 1365 RADC_a046_msgId "Radar: a046 msg id";
CM_ SG_ 1365 RADC_a047_chassisTypeExp "Radar: a047 chassis type exp; raw 7 = signal not available (SNA)";
CM_ SG_ 1365 RADC_a047_chassisTypeRx "Radar: a047 chassis type rx; raw 7 = signal not available (SNA)";
CM_ SG_ 1365 RADC_a048_airSuspensionExp "Radar: a048 air suspension exp; raw 7 = signal not available (SNA)";
CM_ SG_ 1365 RADC_a048_airSuspensionRx "Radar: a048 air suspension rx; raw 7 = signal not available (SNA)";
CM_ SG_ 1365 RADC_a049_fourWheelDriveExp "Radar: a049 four wheel drive exp; raw 3 = signal not available (SNA)";
CM_ SG_ 1365 RADC_a049_fourWheelDriveRx "Radar: a049 four wheel drive rx; raw 3 = signal not available (SNA)";
CM_ SG_ 1365 RADC_a050_countryExp "Radar: a050 country exp";
CM_ SG_ 1365 RADC_a050_countryRx "Radar: a050 country rx";
CM_ SG_ 1365 RADC_a051_epasTypeExp "Radar: a051 epas type exp; raw 7 = signal not available (SNA)";
CM_ SG_ 1365 RADC_a051_epasTypeRx "Radar: a051 epas type rx; raw 7 = signal not available (SNA)";
CM_ SG_ 1365 RADC_a052_radarPositionExp "Radar: a052 radar position exp; raw 7 = signal not available (SNA)";
CM_ SG_ 1365 RADC_a052_radarPositionRx "Radar: a052 radar position rx; raw 7 = signal not available (SNA)";
CM_ SG_ 1365 RADC_a054_block_ucObjLossProb "Radar: a054 block uc obj loss prob";
CM_ SG_ 1365 RADC_a054_block_ucObjLossConf "Radar: a054 block uc obj loss conf";
CM_ SG_ 1365 RADC_a054_block_ucOverallProb "Radar: a054 block uc overall prob";
CM_ SG_ 1365 RADC_a054_block_ucOverallConf "Radar: a054 block uc overall conf";
CM_ SG_ 1365 RADC_a054_block_RoadbeamTimeCnt "Radar: a054 block roadbeam time cnt";
CM_ SG_ 1365 RADC_a055_block_usTimeoutWayCnt "Radar: a055 block us timeout way cnt";
CM_ SG_ 1365 RADC_a055_block_ucTimeoutTimeCnt "Radar: a055 block uc timeout time cnt";
CM_ SG_ 1365 RADC_a055_bblock_ucTimeoutBlkPro "Radar: a055 bblock uc timeout blk prob";
CM_ SG_ 1365 RADC_a055_block_usFullBlkTimer "Radar: a055 block us full blk timer";
CM_ BO_ 1282 "Radar message: alert matrix0; frame length from the layout, not yet observed on a vehicle bus";
CM_ SG_ 1282 RADC_a001_can1BusOff "Radar: a001 can1 bus off";
CM_ SG_ 1282 RADC_a002_ecuAdcError "Radar: a002 ecu adc error";
CM_ SG_ 1282 RADC_a003_ecuBistDisabled "Radar: a003 ecu bist disabled";
CM_ SG_ 1282 RADC_a004_ecuCrcHwError "Radar: a004 ecu crc hw error";
CM_ SG_ 1282 RADC_a005_ecuEcuMError "Radar: a005 ecu ecu m error";
CM_ SG_ 1282 RADC_a006_ecuFimError "Radar: a006 ecu fim error";
CM_ SG_ 1282 RADC_a007_ecuGptCheckError "Radar: a007 ecu gpt check error";
CM_ SG_ 1282 RADC_a008_ecuHwSwInterlock "Radar: a008 ecu hw sw interlock";
CM_ SG_ 1282 RADC_a009_plantModeActive "Radar: a009 plant mode active";
CM_ SG_ 1282 RADC_a010_ecuIoHwAbError "Radar: a010 ecu io hw ab error";
CM_ SG_ 1282 RADC_a011_ecuMcemError "Radar: a011 ecu mcem error";
CM_ SG_ 1282 RADC_a012_ecuSpiError "Radar: a012 ecu spi error";
CM_ SG_ 1282 RADC_a013_ecuWdgError "Radar: a013 ecu wdg error";
CM_ SG_ 1282 RADC_a014_fctSelfTestNotDone "Radar: a014 fct self test not done";
CM_ SG_ 1282 RADC_a015_fctSenInterference "Radar: a015 fct sen interference";
CM_ SG_ 1282 RADC_a016_adcOverVolt "Radar: a016 adc over volt";
CM_ SG_ 1282 RADC_a017_adcUnderVolt "Radar: a017 adc under volt";
CM_ SG_ 1282 RADC_a018_internalHardwareFault "Radar: a018 internal hardware fault";
CM_ SG_ 1282 RADC_a019_internalSoftwareFault "Radar: a019 internal software fault";
CM_ SG_ 1282 RADC_a020_overTemp "Radar: a020 over temp";
CM_ SG_ 1282 RADC_a021_overTempCrit "Radar: a021 over temp crit";
CM_ SG_ 1282 RADC_a022_tempImplausible "Radar: a022 temp implausible";
CM_ SG_ 1282 RADC_a023_underTemp "Radar: a023 under temp";
CM_ SG_ 1282 RADC_a024_underTempCrit "Radar: a024 under temp crit";
CM_ SG_ 1282 RADC_a025_overVoltage "Radar: a025 over voltage";
CM_ SG_ 1282 RADC_a026_underVoltage "Radar: a026 under voltage";
CM_ SG_ 1282 RADC_a027_nvmFailure "Radar: a027 nvm failure";
CM_ SG_ 1282 RADC_a028_rfChipError "Radar: a028 rf chip error";
CM_ SG_ 1282 RADC_a029_rhcError "Radar: a029 rhc error";
CM_ SG_ 1282 RADC_a030_rspError "Radar: a030 rsp error";
CM_ SG_ 1282 RADC_a031_sensorMisaligned "Radar: a031 sensor misaligned";
CM_ SG_ 1282 RADC_a032_sensorBlocked "Radar: a032 sensor blocked";
CM_ SG_ 1282 RADC_a033_sensorNeverAligned "Radar: a033 sensor never aligned";
CM_ SG_ 1282 RADC_a034_vehDynamicsError "Radar: a034 veh dynamics error";
CM_ SG_ 1282 RADC_a035_vinMIA "Radar: a035 vin MIA";
CM_ SG_ 1282 RADC_a036_carConfigMIA "Radar: a036 car config MIA";
CM_ SG_ 1282 RADC_a037_inertialSignalsMIA "Radar: a037 inertial signals MIA";
CM_ SG_ 1282 RADC_a038_steeringWheelAngleMIA "Radar: a038 steering wheel angle MIA";
CM_ SG_ 1282 RADC_a039_vehicleStateMIA "Radar: a039 vehicle state MIA";
CM_ SG_ 1282 RADC_a040_wheelSpeedsMIA "Radar: a040 wheel speeds MIA";
CM_ SG_ 1282 RADC_a041_vinErr "Radar: a041 vin err";
CM_ SG_ 1282 RADC_a042_carConfigErr "Radar: a042 car config err";
CM_ SG_ 1282 RADC_a043_inertialSignalsErr "Radar: a043 inertial signals err";
CM_ SG_ 1282 RADC_a044_steeringWheelAngleErr "Radar: a044 steering wheel angle err";
CM_ SG_ 1282 RADC_a045_vehicleStateErr "Radar: a045 vehicle state err";
CM_ SG_ 1282 RADC_a046_wheelSpeedsErr "Radar: a046 wheel speeds err";
CM_ SG_ 1282 RADC_a047_mismatchChassisType "Radar: a047 mismatch chassis type";
CM_ SG_ 1282 RADC_a048_mismatchAirSuspension "Radar: a048 mismatch air suspension";
CM_ SG_ 1282 RADC_a049_mismatchFourWheelDrive "Radar: a049 mismatch four wheel drive";
CM_ SG_ 1282 RADC_a050_mismatchCountry "Radar: a050 mismatch country";
CM_ SG_ 1282 RADC_a051_mismatchEPASType "Radar: a051 mismatch EPAS type";
CM_ SG_ 1282 RADC_a052_mismatcRadPos "Radar: a052 mismatc rad pos";
CM_ SG_ 1282 RADC_a053_emError "Radar: a053 em error";
CM_ SG_ 1282 RADC_a054_blockageInfo_Frame_1 "Radar: a054 blockage info frame 1";
CM_ SG_ 1282 RADC_a055_blockageInfo_Frame_2 "Radar: a055 blockage info frame 2";
CM_ BO_ 1329 "Radar message: info; frame length from the layout, not yet observed on a vehicle bus";
CM_ SG_ 1329 RADC_infoIndex "Radar: info index";
CM_ SG_ 1329 RADC_infoBuildType "Radar: info build type";
CM_ SG_ 1329 RADC_infoBuildConfigID "Radar: info build config ID";
CM_ SG_ 1329 RADC_infoHardwareID "Radar: info hardware ID";
CM_ SG_ 1329 RADC_infoComponentID "Radar: info component ID";
CM_ SG_ 1329 RADC_infoPcbaID "Radar: info pcba ID";
CM_ SG_ 1329 RADC_infoAssemblyID "Radar: info assembly ID";
CM_ SG_ 1329 RADC_infoUsageID "Radar: info usage ID";
CM_ SG_ 1329 RADC_infoSubUsageID "Radar: info sub usage ID";
CM_ SG_ 1329 RADC_infoApplicationCRC "Radar: info application CRC";
CM_ SG_ 1329 RADC_infoPlatformType "Radar: info platform type";
CM_ SG_ 1329 RADC_infoMajorVersion "Radar: info major version";
CM_ SG_ 1329 RADC_infoBranchOrigin "Radar: info branch origin";
CM_ SG_ 1329 RADC_infoMaturity "Radar: info maturity";
CM_ SG_ 1329 RADC_infoHardwareRevision "Radar: info hardware revision";
CM_ SG_ 1329 RADC_infoBootUdsProtoVersion "Radar: info boot uds proto version";
CM_ SG_ 1329 RADC_infoBootloaderCRC "Radar: info bootloader CRC";
CM_ BO_ 1665 "Radar message: uds response; frame length from the layout, not yet observed on a vehicle bus";
CM_ SG_ 1665 RADC_udsResponseData "Radar: uds response data";
BA_DEF_ BO_ "GenMsgCycleTime" INT 0 3600000;
BA_DEF_ BO_ "GenMsgSendType" ENUM "Cyclic","NotUsed","NotUsed","NotUsed","NotUsed","NotUsed","NotUsed","IfActive","NoMsgSendType","NotUsed";
BA_DEF_ BO_ "VFrameFormat" ENUM "StandardCAN","ExtendedCAN","reserved","J1939PG","reserved","reserved","reserved","reserved","reserved","reserved","reserved","reserved","reserved","reserved","StandardCAN_FD","ExtendedCAN_FD";
BA_DEF_ BO_ "CANFD_BRS" ENUM "0","1";
BA_DEF_ SG_ "GenSigSNA" STRING;
BA_DEF_ SG_ "SystemSignalLongSymbol" STRING;
BA_DEF_ SG_ "Confidence" ENUM "validated","plausible","layout-only","contradicted";
BA_DEF_DEF_ "GenMsgCycleTime" 0;
BA_DEF_DEF_ "GenMsgSendType" "NoMsgSendType";
BA_DEF_DEF_ "VFrameFormat" "StandardCAN";
BA_DEF_DEF_ "CANFD_BRS" "1";
BA_DEF_DEF_ "GenSigSNA" "";
BA_DEF_DEF_ "SystemSignalLongSymbol" "";
BA_DEF_DEF_ "Confidence" "layout-only";
BA_ "GenMsgCycleTime" BO_ 806 1000;
BA_ "GenMsgSendType" BO_ 806 0;
BA_ "GenMsgCycleTime" BO_ 846 100;
BA_ "GenMsgSendType" BO_ 846 0;
BA_ "GenMsgCycleTime" BO_ 862 100;
BA_ "GenMsgSendType" BO_ 862 0;
BA_ "GenMsgCycleTime" BO_ 926 100;
BA_ "GenMsgSendType" BO_ 926 0;
BA_ "GenMsgCycleTime" BO_ 606 100;
BA_ "GenMsgSendType" BO_ 606 0;
BA_ "GenMsgCycleTime" BO_ 542 40;
BA_ "GenMsgSendType" BO_ 542 0;
BA_ "GenMsgCycleTime" BO_ 590 100;
BA_ "GenMsgSendType" BO_ 590 0;
BA_ "GenMsgCycleTime" BO_ 526 40;
BA_ "GenMsgSendType" BO_ 526 0;
BA_ "GenMsgCycleTime" BO_ 558 40;
BA_ "GenMsgSendType" BO_ 558 0;
BA_ "GenMsgCycleTime" BO_ 814 100;
BA_ "GenMsgSendType" BO_ 814 0;
BA_ "GenMsgCycleTime" BO_ 830 100;
BA_ "GenMsgSendType" BO_ 830 0;
BA_ "GenMsgCycleTime" BO_ 798 500;
BA_ "GenMsgSendType" BO_ 798 0;
BA_ "GenMsgCycleTime" BO_ 782 250;
BA_ "GenMsgSendType" BO_ 782 0;
BA_ "GenMsgCycleTime" BO_ 894 1000;
BA_ "GenMsgSendType" BO_ 894 0;
BA_ "GenMsgCycleTime" BO_ 1282 1000;
BA_ "GenMsgSendType" BO_ 1282 0;
BA_ "GenMsgCycleTime" BO_ 1329 1000;
BA_ "GenMsgSendType" BO_ 1329 0;
BA_ "Confidence" SG_ 1486 PARK_alertID 1;
BA_ "Confidence" SG_ 1486 PARK_alertState 1;
BA_ "Confidence" SG_ 1486 PARK_sw001_sensorTemperature 1;
BA_ "SystemSignalLongSymbol" SG_ 1486 PARK_sw002_diagnosticTransferErr "PARK_sw002_diagnosticTransferError";
BA_ "Confidence" SG_ 1486 PARK_sw004_reverbPeriod 1;
BA_ "Confidence" SG_ 1486 PARK_sw004_reverbTime 1;
BA_ "Confidence" SG_ 1486 PARK_sw006_sensorTemperature 1;
BA_ "SystemSignalLongSymbol" SG_ 1486 PARK_sw007_diagnosticTransferErr "PARK_sw007_diagnosticTransferError";
BA_ "Confidence" SG_ 1486 PARK_sw009_reverbPeriod 1;
BA_ "Confidence" SG_ 1486 PARK_sw009_reverbTime 1;
BA_ "Confidence" SG_ 1486 PARK_sw011_sensorTemperature 1;
BA_ "SystemSignalLongSymbol" SG_ 1486 PARK_sw012_diagnosticTransferErr "PARK_sw012_diagnosticTransferError";
BA_ "Confidence" SG_ 1486 PARK_sw014_reverbPeriod 1;
BA_ "Confidence" SG_ 1486 PARK_sw014_reverbTime 1;
BA_ "Confidence" SG_ 1486 PARK_sw016_sensorTemperature 1;
BA_ "SystemSignalLongSymbol" SG_ 1486 PARK_sw017_diagnosticTransferErr "PARK_sw017_diagnosticTransferError";
BA_ "Confidence" SG_ 1486 PARK_sw019_reverbPeriod 1;
BA_ "Confidence" SG_ 1486 PARK_sw019_reverbTime 1;
BA_ "Confidence" SG_ 1486 PARK_sw021_sensorTemperature 1;
BA_ "SystemSignalLongSymbol" SG_ 1486 PARK_sw022_diagnosticTransferErr "PARK_sw022_diagnosticTransferError";
BA_ "Confidence" SG_ 1486 PARK_sw024_reverbPeriod 1;
BA_ "Confidence" SG_ 1486 PARK_sw024_reverbTime 1;
BA_ "Confidence" SG_ 1486 PARK_sw026_sensorTemperature 1;
BA_ "SystemSignalLongSymbol" SG_ 1486 PARK_sw027_diagnosticTransferErr "PARK_sw027_diagnosticTransferError";
BA_ "Confidence" SG_ 1486 PARK_sw029_reverbPeriod 1;
BA_ "Confidence" SG_ 1486 PARK_sw029_reverbTime 1;
BA_ "Confidence" SG_ 1486 PARK_sw031_sensorTemperature 1;
BA_ "SystemSignalLongSymbol" SG_ 1486 PARK_sw032_diagnosticTransferErr "PARK_sw032_diagnosticTransferError";
BA_ "Confidence" SG_ 1486 PARK_sw034_reverbPeriod 1;
BA_ "Confidence" SG_ 1486 PARK_sw034_reverbTime 1;
BA_ "Confidence" SG_ 1486 PARK_sw036_sensorTemperature 1;
BA_ "SystemSignalLongSymbol" SG_ 1486 PARK_sw037_diagnosticTransferErr "PARK_sw037_diagnosticTransferError";
BA_ "Confidence" SG_ 1486 PARK_sw039_reverbPeriod 1;
BA_ "Confidence" SG_ 1486 PARK_sw039_reverbTime 1;
BA_ "Confidence" SG_ 1486 PARK_sw041_sensorTemperature 1;
BA_ "SystemSignalLongSymbol" SG_ 1486 PARK_sw042_diagnosticTransferErr "PARK_sw042_diagnosticTransferError";
BA_ "Confidence" SG_ 1486 PARK_sw044_reverbPeriod 1;
BA_ "Confidence" SG_ 1486 PARK_sw044_reverbTime 1;
BA_ "Confidence" SG_ 1486 PARK_sw046_sensorTemperature 1;
BA_ "SystemSignalLongSymbol" SG_ 1486 PARK_sw047_diagnosticTransferErr "PARK_sw047_diagnosticTransferError";
BA_ "Confidence" SG_ 1486 PARK_sw049_reverbPeriod 1;
BA_ "Confidence" SG_ 1486 PARK_sw049_reverbTime 1;
BA_ "Confidence" SG_ 1486 PARK_sw051_sensorTemperature 1;
BA_ "SystemSignalLongSymbol" SG_ 1486 PARK_sw052_diagnosticTransferErr "PARK_sw052_diagnosticTransferError";
BA_ "Confidence" SG_ 1486 PARK_sw054_reverbPeriod 1;
BA_ "Confidence" SG_ 1486 PARK_sw054_reverbTime 1;
BA_ "Confidence" SG_ 1486 PARK_sw056_sensorTemperature 1;
BA_ "SystemSignalLongSymbol" SG_ 1486 PARK_sw057_diagnosticTransferErr "PARK_sw057_diagnosticTransferError";
BA_ "Confidence" SG_ 1486 PARK_sw059_reverbPeriod 1;
BA_ "Confidence" SG_ 1486 PARK_sw059_reverbTime 1;
BA_ "Confidence" SG_ 1486 PARK_sw061_voltage 1;
BA_ "Confidence" SG_ 1486 PARK_sw063_voltage 1;
BA_ "Confidence" SG_ 1486 PARK_sw077_errorType 1;
BA_ "Confidence" SG_ 1486 PARK_sw078_errorType 1;
BA_ "Confidence" SG_ 1486 PARK_sw079_errorType 1;
BA_ "Confidence" SG_ 1486 PARK_sw080_errorType 1;
BA_ "Confidence" SG_ 1486 PARK_sw081_errorType 1;
BA_ "Confidence" SG_ 1486 PARK_sw082_errorType 1;
BA_ "Confidence" SG_ 1486 PARK_sw083_errorType 1;
BA_ "Confidence" SG_ 1486 PARK_sw084_errorType 1;
BA_ "Confidence" SG_ 1486 PARK_sw087_s1_sensorType 1;
BA_ "GenSigSNA" SG_ 1486 PARK_sw087_s1_sensorType "3";
BA_ "Confidence" SG_ 1486 PARK_sw087_s2_sensorType 1;
BA_ "GenSigSNA" SG_ 1486 PARK_sw087_s2_sensorType "3";
BA_ "Confidence" SG_ 1486 PARK_sw087_s3_sensorType 1;
BA_ "GenSigSNA" SG_ 1486 PARK_sw087_s3_sensorType "3";
BA_ "Confidence" SG_ 1486 PARK_sw087_s4_sensorType 1;
BA_ "GenSigSNA" SG_ 1486 PARK_sw087_s4_sensorType "3";
BA_ "Confidence" SG_ 1486 PARK_sw087_s5_sensorType 1;
BA_ "GenSigSNA" SG_ 1486 PARK_sw087_s5_sensorType "3";
BA_ "Confidence" SG_ 1486 PARK_sw087_s6_sensorType 1;
BA_ "GenSigSNA" SG_ 1486 PARK_sw087_s6_sensorType "3";
BA_ "Confidence" SG_ 1486 PARK_sw087_s7_sensorType 1;
BA_ "GenSigSNA" SG_ 1486 PARK_sw087_s7_sensorType "3";
BA_ "Confidence" SG_ 1486 PARK_sw087_s8_sensorType 1;
BA_ "GenSigSNA" SG_ 1486 PARK_sw087_s8_sensorType "3";
BA_ "Confidence" SG_ 1486 PARK_sw087_s9_sensorType 1;
BA_ "GenSigSNA" SG_ 1486 PARK_sw087_s9_sensorType "3";
BA_ "Confidence" SG_ 1486 PARK_sw087_s10_sensorType 1;
BA_ "GenSigSNA" SG_ 1486 PARK_sw087_s10_sensorType "3";
BA_ "Confidence" SG_ 1486 PARK_sw087_s11_sensorType 1;
BA_ "GenSigSNA" SG_ 1486 PARK_sw087_s11_sensorType "3";
BA_ "Confidence" SG_ 1486 PARK_sw087_s12_sensorType 1;
BA_ "GenSigSNA" SG_ 1486 PARK_sw087_s12_sensorType "3";
BA_ "Confidence" SG_ 806 PARK_infoIndex 1;
BA_ "Confidence" SG_ 806 PARK_infoBuildType 0;
BA_ "Confidence" SG_ 806 PARK_infoComponentID 0;
BA_ "Confidence" SG_ 806 PARK_infoPcbaID 0;
BA_ "Confidence" SG_ 806 PARK_infoAssemblyID 0;
BA_ "Confidence" SG_ 806 PARK_infoUsageID 0;
BA_ "Confidence" SG_ 806 PARK_infoApplicationCRC 0;
BA_ "Confidence" SG_ 806 PARK_infoBootUdsProtoVersion 0;
BA_ "Confidence" SG_ 806 PARK_infoBootloaderCRC 0;
BA_ "Confidence" SG_ 846 PARK_frontLeftMiddleRawDistData 0;
BA_ "GenSigSNA" SG_ 846 PARK_frontLeftMiddleRawDistData "255";
BA_ "Confidence" SG_ 846 PARK_frontMiddleRawDistData 0;
BA_ "GenSigSNA" SG_ 846 PARK_frontMiddleRawDistData "255";
BA_ "Confidence" SG_ 846 PARK_frontRightMiddleRawDistData 0;
BA_ "GenSigSNA" SG_ 846 PARK_frontRightMiddleRawDistData "255";
BA_ "Confidence" SG_ 846 PARK_pasFrontMiddleCounter 0;
BA_ "Confidence" SG_ 846 PARK_pasFrontMiddleChecksum 0;
BA_ "Confidence" SG_ 862 PARK_rearLeftMiddleRawDistData 0;
BA_ "GenSigSNA" SG_ 862 PARK_rearLeftMiddleRawDistData "255";
BA_ "Confidence" SG_ 862 PARK_rearMiddleRawDistData 0;
BA_ "GenSigSNA" SG_ 862 PARK_rearMiddleRawDistData "255";
BA_ "Confidence" SG_ 862 PARK_rearRightMiddleRawDistData 0;
BA_ "GenSigSNA" SG_ 862 PARK_rearRightMiddleRawDistData "255";
BA_ "Confidence" SG_ 862 PARK_pasRearMiddleCounter 0;
BA_ "Confidence" SG_ 862 PARK_pasRearMiddleChecksum 0;
BA_ "Confidence" SG_ 926 PARK_rightSideFrontRawDistData 0;
BA_ "GenSigSNA" SG_ 926 PARK_rightSideFrontRawDistData "255";
BA_ "Confidence" SG_ 926 PARK_rightSideRearRawDistData 0;
BA_ "GenSigSNA" SG_ 926 PARK_rightSideRearRawDistData "255";
BA_ "Confidence" SG_ 926 PARK_leftSideFrontRawDistData 0;
BA_ "GenSigSNA" SG_ 926 PARK_leftSideFrontRawDistData "255";
BA_ "Confidence" SG_ 926 PARK_leftSideRearRawDistData 0;
BA_ "GenSigSNA" SG_ 926 PARK_leftSideRearRawDistData "255";
BA_ "Confidence" SG_ 926 PARK_pasSidesCounter 0;
BA_ "Confidence" SG_ 926 PARK_pasSidesChecksum 0;
BA_ "Confidence" SG_ 606 PARK_pscEnvSlotType 1;
BA_ "Confidence" SG_ 606 PARK_pscLeftParallelObj1X 0;
BA_ "GenSigSNA" SG_ 606 PARK_pscLeftParallelObj1X "2047";
BA_ "Confidence" SG_ 606 PARK_pscLeftParallelObj1Y 0;
BA_ "GenSigSNA" SG_ 606 PARK_pscLeftParallelObj1Y "2047";
BA_ "Confidence" SG_ 606 PARK_pscLeftParallelObj1Alpha 0;
BA_ "GenSigSNA" SG_ 606 PARK_pscLeftParallelObj1Alpha "127";
BA_ "Confidence" SG_ 606 PARK_pscLeftParallelObj2Y 0;
BA_ "GenSigSNA" SG_ 606 PARK_pscLeftParallelObj2Y "2047";
BA_ "Confidence" SG_ 606 PARK_pscLeftParallelObj2X 0;
BA_ "GenSigSNA" SG_ 606 PARK_pscLeftParallelObj2X "2047";
BA_ "Confidence" SG_ 606 PARK_pscLeftParallelObj2Alpha 0;
BA_ "GenSigSNA" SG_ 606 PARK_pscLeftParallelObj2Alpha "127";
BA_ "Confidence" SG_ 606 PARK_pscLeftCrossObj1X 0;
BA_ "GenSigSNA" SG_ 606 PARK_pscLeftCrossObj1X "2047";
BA_ "Confidence" SG_ 606 PARK_pscLeftCrossObj1Y 0;
BA_ "GenSigSNA" SG_ 606 PARK_pscLeftCrossObj1Y "2047";
BA_ "Confidence" SG_ 606 PARK_pscLeftCrossObj1Alpha 0;
BA_ "GenSigSNA" SG_ 606 PARK_pscLeftCrossObj1Alpha "127";
BA_ "Confidence" SG_ 606 PARK_pscLeftCrossObj2Y 0;
BA_ "GenSigSNA" SG_ 606 PARK_pscLeftCrossObj2Y "2047";
BA_ "Confidence" SG_ 606 PARK_pscLeftCrossObj2X 0;
BA_ "GenSigSNA" SG_ 606 PARK_pscLeftCrossObj2X "2047";
BA_ "Confidence" SG_ 606 PARK_pscLeftCrossObj2Alpha 0;
BA_ "GenSigSNA" SG_ 606 PARK_pscLeftCrossObj2Alpha "127";
BA_ "Confidence" SG_ 606 PARK_pscRightParallelObj1X 0;
BA_ "GenSigSNA" SG_ 606 PARK_pscRightParallelObj1X "2047";
BA_ "Confidence" SG_ 606 PARK_pscRightParallelObj1Y 0;
BA_ "GenSigSNA" SG_ 606 PARK_pscRightParallelObj1Y "2047";
BA_ "Confidence" SG_ 606 PARK_pscRightParallelObj1Alpha 0;
BA_ "GenSigSNA" SG_ 606 PARK_pscRightParallelObj1Alpha "127";
BA_ "Confidence" SG_ 606 PARK_pscRightParallelObj2Y 0;
BA_ "GenSigSNA" SG_ 606 PARK_pscRightParallelObj2Y "2047";
BA_ "Confidence" SG_ 606 PARK_pscRightParallelObj2X 0;
BA_ "GenSigSNA" SG_ 606 PARK_pscRightParallelObj2X "2047";
BA_ "Confidence" SG_ 606 PARK_pscRightParallelObj2Alpha 0;
BA_ "GenSigSNA" SG_ 606 PARK_pscRightParallelObj2Alpha "127";
BA_ "Confidence" SG_ 606 PARK_pscRightCrossObj1X 0;
BA_ "GenSigSNA" SG_ 606 PARK_pscRightCrossObj1X "2047";
BA_ "Confidence" SG_ 606 PARK_pscRightCrossObj1Y 0;
BA_ "GenSigSNA" SG_ 606 PARK_pscRightCrossObj1Y "2047";
BA_ "Confidence" SG_ 606 PARK_pscRightCrossObj1Alpha 0;
BA_ "GenSigSNA" SG_ 606 PARK_pscRightCrossObj1Alpha "127";
BA_ "Confidence" SG_ 606 PARK_pscRightCrossObj2Y 0;
BA_ "GenSigSNA" SG_ 606 PARK_pscRightCrossObj2Y "2047";
BA_ "Confidence" SG_ 606 PARK_pscRightCrossObj2X 0;
BA_ "GenSigSNA" SG_ 606 PARK_pscRightCrossObj2X "2047";
BA_ "Confidence" SG_ 606 PARK_pscRightCrossObj2Alpha 0;
BA_ "GenSigSNA" SG_ 606 PARK_pscRightCrossObj2Alpha "127";
BA_ "Confidence" SG_ 542 PARK_pscParkStatus 0;
BA_ "GenSigSNA" SG_ 542 PARK_pscParkStatus "7";
BA_ "Confidence" SG_ 542 PARK_pscParkAbortReason 0;
BA_ "GenSigSNA" SG_ 542 PARK_pscParkAbortReason "31";
BA_ "Confidence" SG_ 542 PARK_pscParallelSpace 0;
BA_ "Confidence" SG_ 542 PARK_pscCrossSpace 0;
BA_ "Confidence" SG_ 542 PARK_pscParallelRightParkable 0;
BA_ "GenSigSNA" SG_ 542 PARK_pscParallelRightParkable "3";
BA_ "Confidence" SG_ 542 PARK_pscParallelLeftParkable 0;
BA_ "GenSigSNA" SG_ 542 PARK_pscParallelLeftParkable "3";
BA_ "Confidence" SG_ 542 PARK_pscCrossRightParkable 0;
BA_ "GenSigSNA" SG_ 542 PARK_pscCrossRightParkable "3";
BA_ "Confidence" SG_ 542 PARK_pscMaxVelocity 0;
BA_ "GenSigSNA" SG_ 542 PARK_pscMaxVelocity "63";
BA_ "Confidence" SG_ 542 PARK_pscCrossLeftParkable 0;
BA_ "GenSigSNA" SG_ 542 PARK_pscCrossLeftParkable "3";
BA_ "Confidence" SG_ 542 PARK_pscParkInstruction 0;
BA_ "GenSigSNA" SG_ 542 PARK_pscParkInstruction "7";
BA_ "Confidence" SG_ 542 PARK_pscManeuverDistance 0;
BA_ "GenSigSNA" SG_ 542 PARK_pscManeuverDistance "2047";
BA_ "Confidence" SG_ 542 PARK_pscAngleActive 0;
BA_ "Confidence" SG_ 542 PARK_pscAngleRequest 0;
BA_ "Confidence" SG_ 542 PARK_pscStatusCounter 0;
BA_ "Confidence" SG_ 542 PARK_pscStatusChecksum 0;
BA_ "Confidence" SG_ 590 PARK_pscVehSlotType 1;
BA_ "Confidence" SG_ 590 PARK_pscLeftParallelVehX 0;
BA_ "GenSigSNA" SG_ 590 PARK_pscLeftParallelVehX "2047";
BA_ "Confidence" SG_ 590 PARK_pscLeftParallelVehY 0;
BA_ "GenSigSNA" SG_ 590 PARK_pscLeftParallelVehY "2047";
BA_ "Confidence" SG_ 590 PARK_pscLeftParallelPsi 0;
BA_ "GenSigSNA" SG_ 590 PARK_pscLeftParallelPsi "8191";
BA_ "Confidence" SG_ 590 PARK_pscLeftParallelSizeX 0;
BA_ "GenSigSNA" SG_ 590 PARK_pscLeftParallelSizeX "255";
BA_ "Confidence" SG_ 590 PARK_pscLeftParallelSizeY 0;
BA_ "GenSigSNA" SG_ 590 PARK_pscLeftParallelSizeY "255";
BA_ "Confidence" SG_ 590 PARK_pscLeftCrossVehX 0;
BA_ "GenSigSNA" SG_ 590 PARK_pscLeftCrossVehX "2047";
BA_ "Confidence" SG_ 590 PARK_pscLeftCrossVehY 0;
BA_ "GenSigSNA" SG_ 590 PARK_pscLeftCrossVehY "2047";
BA_ "Confidence" SG_ 590 PARK_pscLeftCrossPsi 0;
BA_ "GenSigSNA" SG_ 590 PARK_pscLeftCrossPsi "8191";
BA_ "Confidence" SG_ 590 PARK_pscLeftCrossSizeX 0;
BA_ "GenSigSNA" SG_ 590 PARK_pscLeftCrossSizeX "255";
BA_ "Confidence" SG_ 590 PARK_pscLeftCrossSizeY 0;
BA_ "GenSigSNA" SG_ 590 PARK_pscLeftCrossSizeY "255";
BA_ "Confidence" SG_ 590 PARK_pscRightParallelVehX 0;
BA_ "GenSigSNA" SG_ 590 PARK_pscRightParallelVehX "2047";
BA_ "Confidence" SG_ 590 PARK_pscRightParallelVehY 0;
BA_ "GenSigSNA" SG_ 590 PARK_pscRightParallelVehY "2047";
BA_ "Confidence" SG_ 590 PARK_pscRightParallelPsi 0;
BA_ "GenSigSNA" SG_ 590 PARK_pscRightParallelPsi "8191";
BA_ "Confidence" SG_ 590 PARK_pscRightParallelSizeX 0;
BA_ "GenSigSNA" SG_ 590 PARK_pscRightParallelSizeX "255";
BA_ "Confidence" SG_ 590 PARK_pscRightParallelSizeY 0;
BA_ "GenSigSNA" SG_ 590 PARK_pscRightParallelSizeY "255";
BA_ "Confidence" SG_ 590 PARK_pscRightCrossVehX 0;
BA_ "GenSigSNA" SG_ 590 PARK_pscRightCrossVehX "2047";
BA_ "Confidence" SG_ 590 PARK_pscRightCrossVehY 0;
BA_ "GenSigSNA" SG_ 590 PARK_pscRightCrossVehY "2047";
BA_ "Confidence" SG_ 590 PARK_pscRightCrossPsi 0;
BA_ "GenSigSNA" SG_ 590 PARK_pscRightCrossPsi "8191";
BA_ "Confidence" SG_ 590 PARK_pscRightCrossSizeX 0;
BA_ "GenSigSNA" SG_ 590 PARK_pscRightCrossSizeX "255";
BA_ "Confidence" SG_ 590 PARK_pscRightCrossSizeY 0;
BA_ "GenSigSNA" SG_ 590 PARK_pscRightCrossSizeY "255";
BA_ "Confidence" SG_ 526 PARK_sdiSensor1RawDistData 0;
BA_ "GenSigSNA" SG_ 526 PARK_sdiSensor1RawDistData "511";
BA_ "Confidence" SG_ 526 PARK_sdiSensor2RawDistData 0;
BA_ "GenSigSNA" SG_ 526 PARK_sdiSensor2RawDistData "511";
BA_ "Confidence" SG_ 526 PARK_sdiSensor3RawDistData 0;
BA_ "GenSigSNA" SG_ 526 PARK_sdiSensor3RawDistData "511";
BA_ "Confidence" SG_ 526 PARK_sdiSensor4RawDistData 0;
BA_ "GenSigSNA" SG_ 526 PARK_sdiSensor4RawDistData "511";
BA_ "Confidence" SG_ 526 PARK_sdiSensor5RawDistData 0;
BA_ "GenSigSNA" SG_ 526 PARK_sdiSensor5RawDistData "511";
BA_ "Confidence" SG_ 526 PARK_sdiSensor6RawDistData 0;
BA_ "GenSigSNA" SG_ 526 PARK_sdiSensor6RawDistData "511";
BA_ "Confidence" SG_ 526 PARK_sdiFrontCounter 0;
BA_ "Confidence" SG_ 526 PARK_sdiFrontChecksum 0;
BA_ "Confidence" SG_ 558 PARK_sdiSensor7RawDistData 0;
BA_ "GenSigSNA" SG_ 558 PARK_sdiSensor7RawDistData "511";
BA_ "Confidence" SG_ 558 PARK_sdiSensor8RawDistData 0;
BA_ "GenSigSNA" SG_ 558 PARK_sdiSensor8RawDistData "511";
BA_ "Confidence" SG_ 558 PARK_sdiSensor9RawDistData 0;
BA_ "GenSigSNA" SG_ 558 PARK_sdiSensor9RawDistData "511";
BA_ "Confidence" SG_ 558 PARK_sdiSensor10RawDistData 0;
BA_ "GenSigSNA" SG_ 558 PARK_sdiSensor10RawDistData "511";
BA_ "Confidence" SG_ 558 PARK_sdiSensor11RawDistData 0;
BA_ "GenSigSNA" SG_ 558 PARK_sdiSensor11RawDistData "511";
BA_ "Confidence" SG_ 558 PARK_sdiSensor12RawDistData 0;
BA_ "GenSigSNA" SG_ 558 PARK_sdiSensor12RawDistData "511";
BA_ "Confidence" SG_ 558 PARK_sdiRearCounter 0;
BA_ "Confidence" SG_ 558 PARK_sdiRearChecksum 0;
BA_ "Confidence" SG_ 814 PARK_frontRightSensorState 0;
BA_ "GenSigSNA" SG_ 814 PARK_frontRightSensorState "3";
BA_ "Confidence" SG_ 814 PARK_frontRightMiddleSensorState 0;
BA_ "GenSigSNA" SG_ 814 PARK_frontRightMiddleSensorState "3";
BA_ "Confidence" SG_ 814 PARK_frontLeftMiddleSensorState 0;
BA_ "GenSigSNA" SG_ 814 PARK_frontLeftMiddleSensorState "3";
BA_ "Confidence" SG_ 814 PARK_frontLeftSensorState 0;
BA_ "GenSigSNA" SG_ 814 PARK_frontLeftSensorState "3";
BA_ "Confidence" SG_ 814 PARK_frontLeftRawDistData 0;
BA_ "GenSigSNA" SG_ 814 PARK_frontLeftRawDistData "255";
BA_ "Confidence" SG_ 814 PARK_frontRightRawDistData 0;
BA_ "GenSigSNA" SG_ 814 PARK_frontRightRawDistData "255";
BA_ "Confidence" SG_ 814 PARK_systemStatusFront 0;
BA_ "GenSigSNA" SG_ 814 PARK_systemStatusFront "3";
BA_ "Confidence" SG_ 814 PARK_frontDtcPresent 0;
BA_ "GenSigSNA" SG_ 814 PARK_frontDtcPresent "3";
BA_ "Confidence" SG_ 814 PARK_sensorStatusFrontCounter 0;
BA_ "Confidence" SG_ 814 PARK_sensorStatusFrontChecksum 0;
BA_ "Confidence" SG_ 830 PARK_rearRightSensorState 0;
BA_ "GenSigSNA" SG_ 830 PARK_rearRightSensorState "3";
BA_ "Confidence" SG_ 830 PARK_rearRightMiddleSensorState 0;
BA_ "GenSigSNA" SG_ 830 PARK_rearRightMiddleSensorState "3";
BA_ "Confidence" SG_ 830 PARK_rearLeftMiddleSensorState 0;
BA_ "GenSigSNA" SG_ 830 PARK_rearLeftMiddleSensorState "3";
BA_ "Confidence" SG_ 830 PARK_rearLeftSensorState 0;
BA_ "GenSigSNA" SG_ 830 PARK_rearLeftSensorState "3";
BA_ "Confidence" SG_ 830 PARK_rearLeftRawDistData 0;
BA_ "GenSigSNA" SG_ 830 PARK_rearLeftRawDistData "255";
BA_ "Confidence" SG_ 830 PARK_rearRightRawDistData 0;
BA_ "GenSigSNA" SG_ 830 PARK_rearRightRawDistData "255";
BA_ "Confidence" SG_ 830 PARK_systemStatusRear 0;
BA_ "GenSigSNA" SG_ 830 PARK_systemStatusRear "3";
BA_ "Confidence" SG_ 830 PARK_rearDtcPresent 0;
BA_ "GenSigSNA" SG_ 830 PARK_rearDtcPresent "3";
BA_ "Confidence" SG_ 830 PARK_sensorStatusRearCounter 0;
BA_ "Confidence" SG_ 830 PARK_sensorStatusRearChecksum 0;
BA_ "Confidence" SG_ 798 PARK_status 0;
BA_ "GenSigSNA" SG_ 798 PARK_status "3";
BA_ "Confidence" SG_ 798 PARK_serviceRequest 0;
BA_ "GenSigSNA" SG_ 798 PARK_serviceRequest "3";
BA_ "Confidence" SG_ 798 PARK_systemDtcPresent 0;
BA_ "GenSigSNA" SG_ 798 PARK_systemDtcPresent "3";
BA_ "Confidence" SG_ 798 PARK_statusCounter 0;
BA_ "Confidence" SG_ 798 PARK_statusChecksum 0;
BA_ "Confidence" SG_ 798 PARK_majorVersion 0;
BA_ "GenSigSNA" SG_ 798 PARK_majorVersion "255";
BA_ "Confidence" SG_ 798 PARK_minorVersion 0;
BA_ "GenSigSNA" SG_ 798 PARK_minorVersion "255";
BA_ "Confidence" SG_ 798 PARK_subMinorVersion 0;
BA_ "GenSigSNA" SG_ 798 PARK_subMinorVersion "255";
BA_ "Confidence" SG_ 782 PARK_frontSVACharID 0;
BA_ "Confidence" SG_ 782 PARK_pscRightCurbType 0;
BA_ "Confidence" SG_ 782 PARK_rearSVACharID 0;
BA_ "Confidence" SG_ 782 PARK_pscLeftCurbType 0;
BA_ "Confidence" SG_ 782 PARK_autoCalComplete 0;
BA_ "Confidence" SG_ 782 PARK_geometryType 0;
BA_ "Confidence" SG_ 782 PARK_tireFitment 0;
BA_ "GenSigSNA" SG_ 782 PARK_tireFitment "3";
BA_ "Confidence" SG_ 782 PARK_rackDetected 0;
BA_ "GenSigSNA" SG_ 782 PARK_rackDetected "3";
BA_ "Confidence" SG_ 782 PARK_sdiActive 0;
BA_ "Confidence" SG_ 782 PARK_sdiNoise 0;
BA_ "GenSigSNA" SG_ 782 PARK_sdiNoise "3";
BA_ "Confidence" SG_ 782 PARK_sdiBlindSpotRight 0;
BA_ "GenSigSNA" SG_ 782 PARK_sdiBlindSpotRight "3";
BA_ "Confidence" SG_ 782 PARK_sdiBlindSpotLeft 0;
BA_ "GenSigSNA" SG_ 782 PARK_sdiBlindSpotLeft "3";
BA_ "Confidence" SG_ 782 PARK_sensorType 0;
BA_ "GenSigSNA" SG_ 782 PARK_sensorType "3";
BA_ "Confidence" SG_ 782 PARK_status2Counter 0;
BA_ "Confidence" SG_ 782 PARK_status2Checksum 0;
BA_ "Confidence" SG_ 1630 PARK_udsResponseData 1;
BA_ "Confidence" SG_ 894 PARK_matrixIndex 1;
BA_ "Confidence" SG_ 1365 RADC_alertID 1;
BA_ "Confidence" SG_ 1365 RADC_alertState 1;
BA_ "Confidence" SG_ 1365 RADC_a002_ecuAdcErrType 1;
BA_ "Confidence" SG_ 1365 RADC_a008_interLockErrType 1;
BA_ "Confidence" SG_ 1365 RADC_a011_ecuMcemErrType 1;
BA_ "Confidence" SG_ 1365 RADC_a013_ecuWdgErrType 1;
BA_ "Confidence" SG_ 1365 RADC_a016_adcOverVoltType 1;
BA_ "Confidence" SG_ 1365 RADC_a016_adcVoltage 1;
BA_ "Confidence" SG_ 1365 RADC_a017_adcUnderVoltType 1;
BA_ "Confidence" SG_ 1365 RADC_a017_adcVoltage 1;
BA_ "Confidence" SG_ 1365 RADC_a019_internalSWFaultType 1;
BA_ "Confidence" SG_ 1365 RADC_a019_internalSWFaultCoreID 1;
BA_ "Confidence" SG_ 1365 RADC_a020_ecuTemp 1;
BA_ "Confidence" SG_ 1365 RADC_a023_ecuTemp 1;
BA_ "Confidence" SG_ 1365 RADC_a025_ecuVoltage 1;
BA_ "Confidence" SG_ 1365 RADC_a026_ecuVoltage 1;
BA_ "Confidence" SG_ 1365 RADC_a027_nvmFailureType 1;
BA_ "Confidence" SG_ 1365 RADC_a028_rfComRegCheckFail 1;
BA_ "Confidence" SG_ 1365 RADC_a029_rhcChirpMonErrType 1;
BA_ "Confidence" SG_ 1365 RADC_a029_rhcRxLongTermErrType 1;
BA_ "Confidence" SG_ 1365 RADC_a029_rhcRxErrType 1;
BA_ "Confidence" SG_ 1365 RADC_a029_rhcVcoPowerErrType 1;
BA_ "Confidence" SG_ 1365 RADC_a029_rhcSp1ErrType 1;
BA_ "Confidence" SG_ 1365 RADC_a029_rhcFdcErrType 1;
BA_ "Confidence" SG_ 1365 RADC_a030_rspErrType 1;
BA_ "Confidence" SG_ 1365 RADC_a031_horizMisalignAngle 1;
BA_ "Confidence" SG_ 1365 RADC_a031_vertMisalignAngle 1;
BA_ "Confidence" SG_ 1365 RADC_a032_blockageType 1;
BA_ "Confidence" SG_ 1365 RADC_a032_block_SPMBlockageState 1;
BA_ "Confidence" SG_ 1365 RADC_a032_block_SPMSelfTestState 1;
BA_ "Confidence" SG_ 1365 RADC_a032_block_ucEstiRange 1;
BA_ "Confidence" SG_ 1365 RADC_a041_vinErrType 1;
BA_ "Confidence" SG_ 1365 RADC_a042_carConfigErrType 1;
BA_ "Confidence" SG_ 1365 RADC_a043_inertialSignalsErrType 1;
BA_ "Confidence" SG_ 1365 RADC_a044_stwAngleErrType 1;
BA_ "Confidence" SG_ 1365 RADC_a045_vehicleStateErrType 1;
BA_ "Confidence" SG_ 1365 RADC_a046_wheelSpeedsErrType 1;
BA_ "Confidence" SG_ 1365 RADC_a047_chassisTypeExp 1;
BA_ "GenSigSNA" SG_ 1365 RADC_a047_chassisTypeExp "7";
BA_ "Confidence" SG_ 1365 RADC_a047_chassisTypeRx 1;
BA_ "GenSigSNA" SG_ 1365 RADC_a047_chassisTypeRx "7";
BA_ "Confidence" SG_ 1365 RADC_a048_airSuspensionExp 1;
BA_ "GenSigSNA" SG_ 1365 RADC_a048_airSuspensionExp "7";
BA_ "Confidence" SG_ 1365 RADC_a048_airSuspensionRx 1;
BA_ "GenSigSNA" SG_ 1365 RADC_a048_airSuspensionRx "7";
BA_ "Confidence" SG_ 1365 RADC_a049_fourWheelDriveExp 1;
BA_ "GenSigSNA" SG_ 1365 RADC_a049_fourWheelDriveExp "3";
BA_ "Confidence" SG_ 1365 RADC_a049_fourWheelDriveRx 1;
BA_ "GenSigSNA" SG_ 1365 RADC_a049_fourWheelDriveRx "3";
BA_ "Confidence" SG_ 1365 RADC_a051_epasTypeExp 1;
BA_ "GenSigSNA" SG_ 1365 RADC_a051_epasTypeExp "7";
BA_ "Confidence" SG_ 1365 RADC_a051_epasTypeRx 1;
BA_ "GenSigSNA" SG_ 1365 RADC_a051_epasTypeRx "7";
BA_ "Confidence" SG_ 1365 RADC_a052_radarPositionExp 1;
BA_ "GenSigSNA" SG_ 1365 RADC_a052_radarPositionExp "7";
BA_ "Confidence" SG_ 1365 RADC_a052_radarPositionRx 1;
BA_ "GenSigSNA" SG_ 1365 RADC_a052_radarPositionRx "7";
BA_ "Confidence" SG_ 1365 RADC_a054_block_RoadbeamTimeCnt 1;
BA_ "Confidence" SG_ 1365 RADC_a055_block_usTimeoutWayCnt 1;
BA_ "Confidence" SG_ 1365 RADC_a055_block_ucTimeoutTimeCnt 1;
BA_ "SystemSignalLongSymbol" SG_ 1365 RADC_a055_bblock_ucTimeoutBlkPro "RADC_a055_bblock_ucTimeoutBlkProb";
BA_ "Confidence" SG_ 1365 RADC_a055_block_usFullBlkTimer 1;
BA_ "Confidence" SG_ 1329 RADC_infoIndex 1;
BA_ "Confidence" SG_ 1329 RADC_infoBuildType 0;
BA_ "Confidence" SG_ 1329 RADC_infoBuildConfigID 0;
BA_ "Confidence" SG_ 1329 RADC_infoHardwareID 0;
BA_ "Confidence" SG_ 1329 RADC_infoComponentID 0;
BA_ "Confidence" SG_ 1329 RADC_infoPcbaID 0;
BA_ "Confidence" SG_ 1329 RADC_infoAssemblyID 0;
BA_ "Confidence" SG_ 1329 RADC_infoUsageID 0;
BA_ "Confidence" SG_ 1329 RADC_infoSubUsageID 0;
BA_ "Confidence" SG_ 1329 RADC_infoApplicationCRC 0;
BA_ "Confidence" SG_ 1329 RADC_infoPlatformType 0;
BA_ "Confidence" SG_ 1329 RADC_infoMajorVersion 0;
BA_ "Confidence" SG_ 1329 RADC_infoBranchOrigin 0;
BA_ "Confidence" SG_ 1329 RADC_infoMaturity 0;
BA_ "Confidence" SG_ 1329 RADC_infoHardwareRevision 0;
BA_ "Confidence" SG_ 1329 RADC_infoBootUdsProtoVersion 0;
BA_ "Confidence" SG_ 1329 RADC_infoBootloaderCRC 0;
BA_ "Confidence" SG_ 1665 RADC_udsResponseData 1;
VAL_ 1486 PARK_alertID 87 "a087_sensorMismatchError" 86 "a086_nvmFault" 85 "a085_watchdogReset" 84 "a084_sccmError" 83 "a083_vcFrontError" 82 "a082_rcmError" 81 "a081_espError" 80 "a080_epbError" 79 "a079_epasError" 78 "a078_diError" 77 "a077_dasError" 76 "a076_vcFrontMia" 75 "a075_rcmMia" 74 "a074_espMia" 73 "a073_epbMia" 72 "a072_epasMia" 71 "a071_diMia" 70 "a070_sccmMia" 69 "a069_dasMia" 68 "a068_hardwareWatchDog" 67 "a067_privateCANBusOff" 66 "a066_calibrationMissing" 65 "a065_crcFault" 64 "a064_ecuFault" 63 "a063_sensorVoltage" 62 "a062_ecuOverVoltage" 61 "a061_ecuUnderVoltage" 60 "a060_s12_crossTalk" 59 "a059_s12_blocked" 58 "a058_s12_linCommError" 57 "a057_s12_internalFail" 56 "a056_s12_overTemp" 55 "a055_s11_crossTalk" 54 "a054_s11_blocked" 53 "a053_s11_linCommError" 52 "a052_s11_internalFail" 51 "a051_s11_overTemp" 50 "a050_s10_crossTalk" 49 "a049_s10_blocked" 48 "a048_s10_linCommError" 47 "a047_s10_internalFail" 46 "a046_s10_overTemp" 45 "a045_s9_crossTalk" 44 "a044_s9_blocked" 43 "a043_s9_linCommError" 42 "a042_s9_internalFail" 41 "a041_s9_overTemp" 40 "a040_s8_crossTalk" 39 "a039_s8_blocked" 38 "a038_s8_linCommError" 37 "a037_s8_internalFail" 36 "a036_s8_overTemp" 35 "a035_s7_crossTalk" 34 "a034_s7_blocked" 33 "a033_s7_linCommError" 32 "a032_s7_internalFail" 31 "a031_s7_overTemp" 30 "a030_s6_crossTalk" 29 "a029_s6_blocked" 28 "a028_s6_linCommError" 27 "a027_s6_internalFail" 26 "a026_s6_overTemp" 25 "a025_s5_crossTalk" 24 "a024_s5_blocked" 23 "a023_s5_linCommError" 22 "a022_s5_internalFail" 21 "a021_s5_overTemp" 20 "a020_s4_crossTalk" 19 "a019_s4_blocked" 18 "a018_s4_linCommError" 17 "a017_s4_internalFail" 16 "a016_s4_overTemp" 15 "a015_s3_crossTalk" 14 "a014_s3_blocked" 13 "a013_s3_linCommError" 12 "a012_s3_internalFail" 11 "a011_s3_overTemp" 10 "a010_s2_crossTalk" 9 "a009_s2_blocked" 8 "a008_s2_linCommError" 7 "a007_s2_internalFail" 6 "a006_s2_overTemp" 5 "a005_s1_crossTalk" 4 "a004_s1_blocked" 3 "a003_s1_linCommError" 2 "a002_s1_internalFail" 1 "a001_s1_overTemp" 0 "ALERT_DO_NOT_USE_ZERO" ;
VAL_ 1486 PARK_alertState 1 "SET" 0 "CLEARED" ;
VAL_ 1486 PARK_sw077_errorType 5 "OVERRUN" 4 "INVALID_DATA" 3 "SEQUENCE" 2 "CHECKSUM" 1 "LENGTH" 0 "NONE" ;
VAL_ 1486 PARK_sw078_errorType 5 "OVERRUN" 4 "INVALID_DATA" 3 "SEQUENCE" 2 "CHECKSUM" 1 "LENGTH" 0 "NONE" ;
VAL_ 1486 PARK_sw079_errorType 5 "OVERRUN" 4 "INVALID_DATA" 3 "SEQUENCE" 2 "CHECKSUM" 1 "LENGTH" 0 "NONE" ;
VAL_ 1486 PARK_sw080_errorType 5 "OVERRUN" 4 "INVALID_DATA" 3 "SEQUENCE" 2 "CHECKSUM" 1 "LENGTH" 0 "NONE" ;
VAL_ 1486 PARK_sw081_errorType 5 "OVERRUN" 4 "INVALID_DATA" 3 "SEQUENCE" 2 "CHECKSUM" 1 "LENGTH" 0 "NONE" ;
VAL_ 1486 PARK_sw082_errorType 5 "OVERRUN" 4 "INVALID_DATA" 3 "SEQUENCE" 2 "CHECKSUM" 1 "LENGTH" 0 "NONE" ;
VAL_ 1486 PARK_sw083_errorType 5 "OVERRUN" 4 "INVALID_DATA" 3 "SEQUENCE" 2 "CHECKSUM" 1 "LENGTH" 0 "NONE" ;
VAL_ 1486 PARK_sw084_errorType 5 "OVERRUN" 4 "INVALID_DATA" 3 "SEQUENCE" 2 "CHECKSUM" 1 "LENGTH" 0 "NONE" ;
VAL_ 1486 PARK_sw087_s1_sensorType 3 "SNA" 2 "VALEO_HP" 1 "VALEO_HPFL" 0 "NONE" ;
VAL_ 1486 PARK_sw087_s2_sensorType 3 "SNA" 2 "VALEO_HP" 1 "VALEO_HPFL" 0 "NONE" ;
VAL_ 1486 PARK_sw087_s3_sensorType 3 "SNA" 2 "VALEO_HP" 1 "VALEO_HPFL" 0 "NONE" ;
VAL_ 1486 PARK_sw087_s4_sensorType 3 "SNA" 2 "VALEO_HP" 1 "VALEO_HPFL" 0 "NONE" ;
VAL_ 1486 PARK_sw087_s5_sensorType 3 "SNA" 2 "VALEO_HP" 1 "VALEO_HPFL" 0 "NONE" ;
VAL_ 1486 PARK_sw087_s6_sensorType 3 "SNA" 2 "VALEO_HP" 1 "VALEO_HPFL" 0 "NONE" ;
VAL_ 1486 PARK_sw087_s7_sensorType 3 "SNA" 2 "VALEO_HP" 1 "VALEO_HPFL" 0 "NONE" ;
VAL_ 1486 PARK_sw087_s8_sensorType 3 "SNA" 2 "VALEO_HP" 1 "VALEO_HPFL" 0 "NONE" ;
VAL_ 1486 PARK_sw087_s9_sensorType 3 "SNA" 2 "VALEO_HP" 1 "VALEO_HPFL" 0 "NONE" ;
VAL_ 1486 PARK_sw087_s10_sensorType 3 "SNA" 2 "VALEO_HP" 1 "VALEO_HPFL" 0 "NONE" ;
VAL_ 1486 PARK_sw087_s11_sensorType 3 "SNA" 2 "VALEO_HP" 1 "VALEO_HPFL" 0 "NONE" ;
VAL_ 1486 PARK_sw087_s12_sensorType 3 "SNA" 2 "VALEO_HP" 1 "VALEO_HPFL" 0 "NONE" ;
VAL_ 806 PARK_infoIndex 255 "END" 31 "SUBCOMPONENT_GITHASH" 30 "PACKAGE_SN_8_14" 29 "PACKAGE_SN_1_7" 27 "PACKAGE_PN_15_20" 26 "PACKAGE_PN_8_14" 25 "PACKAGE_PN_1_7" 23 "SUBCOMPONENT2" 22 "VARIANTCRC" 20 "UDS_PROTOCOL_BOOTCRC" 19 "VERSION_DEPRECATED" 18 "BOOTLOADER_GITHASH" 17 "APP_GITHASH" 16 "SUBCOMPONENT" 15 "BOOTLOADER_CRC" 14 "BOOTLOADER_SVN" 13 "APP_CRC" 11 "PCBAID_ASSYID_USAGEID" 10 "BUILD_HWID_COMPONENTID" 9 "DEPRECATED_9" 8 "DEPRECATED_8" 7 "DEPRECATED_7" 6 "DEPRECATED_6" 5 "DEPRECATED_5" 4 "DEPRECATED_4" 3 "DEPRECATED_3" 2 "DEPRECATED_2" 1 "DEPRECATED_1" 0 "DEPRECATED_0" ;
VAL_ 806 PARK_infoBuildType 4 "INFO_MFG_BUILD" 3 "INFO_TRACEABLE_CI_BUILD" 2 "INFO_LOCAL_BUILD" 1 "INFO_PLATFORM_BUILD" 0 "INFO_UNKNOWN_BUILD" ;
VAL_ 846 PARK_frontLeftMiddleRawDistData 255 "SNA" ;
VAL_ 846 PARK_frontMiddleRawDistData 255 "SNA" ;
VAL_ 846 PARK_frontRightMiddleRawDistData 255 "SNA" ;
VAL_ 862 PARK_rearLeftMiddleRawDistData 255 "SNA" ;
VAL_ 862 PARK_rearMiddleRawDistData 255 "SNA" ;
VAL_ 862 PARK_rearRightMiddleRawDistData 255 "SNA" ;
VAL_ 926 PARK_rightSideFrontRawDistData 255 "SNA" ;
VAL_ 926 PARK_rightSideRearRawDistData 255 "SNA" ;
VAL_ 926 PARK_leftSideFrontRawDistData 255 "SNA" ;
VAL_ 926 PARK_leftSideRearRawDistData 255 "SNA" ;
VAL_ 606 PARK_pscEnvSlotType 3 "RIGHT_CROSS" 2 "RIGHT_PARALLEL" 1 "LEFT_CROSS" 0 "LEFT_PARALLEL" ;
VAL_ 606 PARK_pscLeftParallelObj1X 2047 "SNA" 2046 "NO_SPACE" ;
VAL_ 606 PARK_pscLeftParallelObj1Y 2047 "SNA" 2046 "NO_SPACE" ;
VAL_ 606 PARK_pscLeftParallelObj1Alpha 127 "SNA" 126 "NO_SPACE" ;
VAL_ 606 PARK_pscLeftParallelObj2Y 2047 "SNA" 2046 "NO_SPACE" ;
VAL_ 606 PARK_pscLeftParallelObj2X 2047 "SNA" 2046 "NO_SPACE" ;
VAL_ 606 PARK_pscLeftParallelObj2Alpha 127 "SNA" 126 "NO_SPACE" ;
VAL_ 606 PARK_pscLeftCrossObj1X 2047 "SNA" 2046 "NO_SPACE" ;
VAL_ 606 PARK_pscLeftCrossObj1Y 2047 "SNA" 2046 "NO_SPACE" ;
VAL_ 606 PARK_pscLeftCrossObj1Alpha 127 "SNA" 126 "NO_SPACE" ;
VAL_ 606 PARK_pscLeftCrossObj2Y 2047 "SNA" 2046 "NO_SPACE" ;
VAL_ 606 PARK_pscLeftCrossObj2X 2047 "SNA" 2046 "NO_SPACE" ;
VAL_ 606 PARK_pscLeftCrossObj2Alpha 127 "SNA" 126 "NO_SPACE" ;
VAL_ 606 PARK_pscRightParallelObj1X 2047 "SNA" 2046 "NO_SPACE" ;
VAL_ 606 PARK_pscRightParallelObj1Y 2047 "SNA" 2046 "NO_SPACE" ;
VAL_ 606 PARK_pscRightParallelObj1Alpha 127 "SNA" 126 "NO_SPACE" ;
VAL_ 606 PARK_pscRightParallelObj2Y 2047 "SNA" 2046 "NO_SPACE" ;
VAL_ 606 PARK_pscRightParallelObj2X 2047 "SNA" 2046 "NO_SPACE" ;
VAL_ 606 PARK_pscRightParallelObj2Alpha 127 "SNA" 126 "NO_SPACE" ;
VAL_ 606 PARK_pscRightCrossObj1X 2047 "SNA" 2046 "NO_SPACE" ;
VAL_ 606 PARK_pscRightCrossObj1Y 2047 "SNA" 2046 "NO_SPACE" ;
VAL_ 606 PARK_pscRightCrossObj1Alpha 127 "SNA" 126 "NO_SPACE" ;
VAL_ 606 PARK_pscRightCrossObj2Y 2047 "SNA" 2046 "NO_SPACE" ;
VAL_ 606 PARK_pscRightCrossObj2X 2047 "SNA" 2046 "NO_SPACE" ;
VAL_ 606 PARK_pscRightCrossObj2Alpha 127 "SNA" 126 "NO_SPACE" ;
VAL_ 542 PARK_pscParkStatus 7 "SNA" 6 "FAULT" 5 "GUIDANCE_FINISHED" 4 "PRE_GUIDANCE" 3 "GUIDANCE_RIGHT" 2 "GUIDANCE_LEFT" 1 "SEARCHING" 0 "NOT_AVAILABLE" ;
VAL_ 542 PARK_pscParkAbortReason 31 "SNA" 25 "PSC_MOVEMENT_AT_ACTIVATION" 24 "PSC_MAX_WAY_BEHIND_HINT" 23 "PSC_PARK_STC_FAILED" 22 "PSC_PARK_PONR_NOT_REACHED" 21 "PSC_VCTL_GENERAL_ABORT" 20 "PSC_HIGH_TORQUE" 19 "PSC_ASYNC_CTRL_SYSTEM" 18 "ERROR" 17 "SYSTEM_SERVICE" 16 "SYSTEM_FAULT" 15 "ECU_INTERNAL_FAULT" 14 "DAS_ABORT" 13 "EPAS_FAULT" 12 "VEHICLE_DYNAMICS_INTERVENTION" 11 "HANDS_ON_DETECTED" 10 "FULL_WARNING_ON_BOTH_SIDES" 9 "PARK_SPACE_TOO_SMALL" 8 "OBSTACLE_ON_PATH" 7 "MAX_YAW_ANGLE_REACHED" 6 "MAX_SWA_DEV_EXCEEDED" 5 "OFF_TRACK" 4 "UNCONTROLLED_TRAVEL_DIST_REACHED" 3 "NO_VALID_PATH" 2 "MAX_NUM_OF_MOVES" 1 "VELOCITY_TOO_HIGH" 0 "NONE" ;
VAL_ 542 PARK_pscParallelSpace 3 "BOTH_AVAILABLE" 2 "LEFT_AVAILABLE" 1 "RIGHT_AVAILABLE" 0 "NONE_AVAILABLE" ;
VAL_ 542 PARK_pscCrossSpace 3 "BOTH_AVAILABLE" 2 "LEFT_AVAILABLE" 1 "RIGHT_AVAILABLE" 0 "NONE_AVAILABLE" ;
VAL_ 542 PARK_pscParallelRightParkable 3 "SNA" 2 "PARKING_SLOT_OK_POSITION_OK" 1 "PARKING_SLOT_OK" 0 "NONE" ;
VAL_ 542 PARK_pscParallelLeftParkable 3 "SNA" 2 "PARKING_SLOT_OK_POSITION_OK" 1 "PARKING_SLOT_OK" 0 "NONE" ;
VAL_ 542 PARK_pscCrossRightParkable 3 "SNA" 2 "PARKING_SLOT_OK_POSITION_OK" 1 "PARKING_SLOT_OK" 0 "NONE" ;
VAL_ 542 PARK_pscMaxVelocity 63 "SNA" ;
VAL_ 542 PARK_pscCrossLeftParkable 3 "SNA" 2 "PARKING_SLOT_OK_POSITION_OK" 1 "PARKING_SLOT_OK" 0 "NONE" ;
VAL_ 542 PARK_pscParkInstruction 7 "SNA" 5 "EXPLORATION" 4 "ABORTED" 3 "DRIVE_BACKWARD" 2 "DRIVE_FORWARD" 1 "STOP" 0 "NO_MESSAGE" ;
VAL_ 542 PARK_pscManeuverDistance 2047 "SNA" ;
VAL_ 542 PARK_pscAngleActive 1 "REQUEST_CONTROL" 0 "INACTIVE" ;
VAL_ 590 PARK_pscVehSlotType 3 "RIGHT_CROSS" 2 "RIGHT_PARALLEL" 1 "LEFT_CROSS" 0 "LEFT_PARALLEL" ;
VAL_ 590 PARK_pscLeftParallelVehX 2047 "SNA" 2046 "NO_SPACE" ;
VAL_ 590 PARK_pscLeftParallelVehY 2047 "SNA" 2046 "NO_SPACE" ;
VAL_ 590 PARK_pscLeftParallelPsi 8191 "SNA" 8190 "NO_SPACE" ;
VAL_ 590 PARK_pscLeftParallelSizeX 255 "SNA" 254 "NO_SPACE" ;
VAL_ 590 PARK_pscLeftParallelSizeY 255 "SNA" 254 "NO_SPACE" ;
VAL_ 590 PARK_pscLeftCrossVehX 2047 "SNA" 2046 "NO_SPACE" ;
VAL_ 590 PARK_pscLeftCrossVehY 2047 "SNA" 2046 "NO_SPACE" ;
VAL_ 590 PARK_pscLeftCrossPsi 8191 "SNA" 8190 "NO_SPACE" ;
VAL_ 590 PARK_pscLeftCrossSizeX 255 "SNA" 254 "NO_SPACE" ;
VAL_ 590 PARK_pscLeftCrossSizeY 255 "SNA" 254 "NO_SPACE" ;
VAL_ 590 PARK_pscRightParallelVehX 2047 "SNA" 2046 "NO_SPACE" ;
VAL_ 590 PARK_pscRightParallelVehY 2047 "SNA" 2046 "NO_SPACE" ;
VAL_ 590 PARK_pscRightParallelPsi 8191 "SNA" 8190 "NO_SPACE" ;
VAL_ 590 PARK_pscRightParallelSizeX 255 "SNA" 254 "NO_SPACE" ;
VAL_ 590 PARK_pscRightParallelSizeY 255 "SNA" 254 "NO_SPACE" ;
VAL_ 590 PARK_pscRightCrossVehX 2047 "SNA" 2046 "NO_SPACE" ;
VAL_ 590 PARK_pscRightCrossVehY 2047 "SNA" 2046 "NO_SPACE" ;
VAL_ 590 PARK_pscRightCrossPsi 8191 "SNA" 8190 "NO_SPACE" ;
VAL_ 590 PARK_pscRightCrossSizeX 255 "SNA" 254 "NO_SPACE" ;
VAL_ 590 PARK_pscRightCrossSizeY 255 "SNA" 254 "NO_SPACE" ;
VAL_ 526 PARK_sdiSensor1RawDistData 511 "SNA" 500 "NO_OBJECT_DETECTED" 1 "NEAR_DETECTION" 0 "BLOCKED" ;
VAL_ 526 PARK_sdiSensor2RawDistData 511 "SNA" 500 "NO_OBJECT_DETECTED" 1 "NEAR_DETECTION" 0 "BLOCKED" ;
VAL_ 526 PARK_sdiSensor3RawDistData 511 "SNA" 500 "NO_OBJECT_DETECTED" 1 "NEAR_DETECTION" 0 "BLOCKED" ;
VAL_ 526 PARK_sdiSensor4RawDistData 511 "SNA" 500 "NO_OBJECT_DETECTED" 1 "NEAR_DETECTION" 0 "BLOCKED" ;
VAL_ 526 PARK_sdiSensor5RawDistData 511 "SNA" 500 "NO_OBJECT_DETECTED" 1 "NEAR_DETECTION" 0 "BLOCKED" ;
VAL_ 526 PARK_sdiSensor6RawDistData 511 "SNA" 500 "NO_OBJECT_DETECTED" 1 "NEAR_DETECTION" 0 "BLOCKED" ;
VAL_ 558 PARK_sdiSensor7RawDistData 511 "SNA" 500 "NO_OBJECT_DETECTED" 1 "NEAR_DETECTION" 0 "BLOCKED" ;
VAL_ 558 PARK_sdiSensor8RawDistData 511 "SNA" 500 "NO_OBJECT_DETECTED" 1 "NEAR_DETECTION" 0 "BLOCKED" ;
VAL_ 558 PARK_sdiSensor9RawDistData 511 "SNA" 500 "NO_OBJECT_DETECTED" 1 "NEAR_DETECTION" 0 "BLOCKED" ;
VAL_ 558 PARK_sdiSensor10RawDistData 511 "SNA" 500 "NO_OBJECT_DETECTED" 1 "NEAR_DETECTION" 0 "BLOCKED" ;
VAL_ 558 PARK_sdiSensor11RawDistData 511 "SNA" 500 "NO_OBJECT_DETECTED" 1 "NEAR_DETECTION" 0 "BLOCKED" ;
VAL_ 558 PARK_sdiSensor12RawDistData 511 "SNA" 500 "NO_OBJECT_DETECTED" 1 "NEAR_DETECTION" 0 "BLOCKED" ;
VAL_ 814 PARK_frontRightSensorState 3 "SNA" 2 "TEMPORARY_FAILURE" 1 "PERMANENT_FAILURE" 0 "NO_FAILURE" ;
VAL_ 814 PARK_frontRightMiddleSensorState 3 "SNA" 2 "TEMPORARY_FAILURE" 1 "PERMANENT_FAILURE" 0 "NO_FAILURE" ;
VAL_ 814 PARK_frontLeftMiddleSensorState 3 "SNA" 2 "TEMPORARY_FAILURE" 1 "PERMANENT_FAILURE" 0 "NO_FAILURE" ;
VAL_ 814 PARK_frontLeftSensorState 3 "SNA" 2 "TEMPORARY_FAILURE" 1 "PERMANENT_FAILURE" 0 "NO_FAILURE" ;
VAL_ 814 PARK_frontLeftRawDistData 255 "SNA" ;
VAL_ 814 PARK_frontRightRawDistData 255 "SNA" ;
VAL_ 814 PARK_systemStatusFront 3 "SNA" 2 "UNUSED" 1 "ENABLED" 0 "DISABLED" ;
VAL_ 814 PARK_frontDtcPresent 3 "SNA" 2 "UNUSED" 1 "TRUE" 0 "FALSE" ;
VAL_ 830 PARK_rearRightSensorState 3 "SNA" 2 "TEMPORARY_FAILURE" 1 "PERMANENT_FAILURE" 0 "NO_FAILURE" ;
VAL_ 830 PARK_rearRightMiddleSensorState 3 "SNA" 2 "TEMPORARY_FAILURE" 1 "PERMANENT_FAILURE" 0 "NO_FAILURE" ;
VAL_ 830 PARK_rearLeftMiddleSensorState 3 "SNA" 2 "TEMPORARY_FAILURE" 1 "PERMANENT_FAILURE" 0 "NO_FAILURE" ;
VAL_ 830 PARK_rearLeftSensorState 3 "SNA" 2 "TEMPORARY_FAILURE" 1 "PERMANENT_FAILURE" 0 "NO_FAILURE" ;
VAL_ 830 PARK_rearLeftRawDistData 255 "SNA" ;
VAL_ 830 PARK_rearRightRawDistData 255 "SNA" ;
VAL_ 830 PARK_systemStatusRear 3 "SNA" 2 "UNUSED" 1 "ENABLED" 0 "DISABLED" ;
VAL_ 830 PARK_rearDtcPresent 3 "SNA" 2 "UNUSED" 1 "TRUE" 0 "FALSE" ;
VAL_ 798 PARK_status 3 "SNA" 2 "TEMPORARY_FAILURE" 1 "ENABLED" 0 "DISABLED" ;
VAL_ 798 PARK_serviceRequest 3 "SNA" 2 "UNUSED" 1 "FAILURE" 0 "NO_FAILURE" ;
VAL_ 798 PARK_systemDtcPresent 3 "SNA" 2 "UNUSED" 1 "TRUE" 0 "FALSE" ;
VAL_ 798 PARK_majorVersion 255 "SNA" ;
VAL_ 798 PARK_minorVersion 255 "SNA" ;
VAL_ 798 PARK_subMinorVersion 255 "SNA" ;
VAL_ 782 PARK_pscRightCurbType 2 "HIGH_CURB" 1 "LOW_CURB" 0 "VIRTUAL_CURB" ;
VAL_ 782 PARK_pscLeftCurbType 2 "HIGH_CURB" 1 "LOW_CURB" 0 "VIRTUAL_CURB" ;
VAL_ 782 PARK_autoCalComplete 1 "COMPLETE" 0 "INCOMPLETE" ;
VAL_ 782 PARK_geometryType 3 "MODELY" 2 "MODEL3" 1 "MODELX" 0 "MODELS" ;
VAL_ 782 PARK_tireFitment 3 "SNA" 2 "NOT_USED" 1 "STAGGERED" 0 "SQUARE" ;
VAL_ 782 PARK_rackDetected 3 "SNA" 2 "RACK_DETECTED" 1 "NO_RACK" 0 "UNKNOWN" ;
VAL_ 782 PARK_sdiActive 1 "SDI_ENABLED" 0 "SDI_DISABLED" ;
VAL_ 782 PARK_sdiNoise 3 "SDI_NOISE_SNA" 2 "SDI_NOISE_RAIN" 1 "SDI_NOISE_HIGH" 0 "SDI_NOISE_NOMINAL" ;
VAL_ 782 PARK_sdiBlindSpotRight 3 "SNA" 2 "UNUSED" 1 "WARNING" 0 "NO_WARNING" ;
VAL_ 782 PARK_sdiBlindSpotLeft 3 "SNA" 2 "UNUSED" 1 "WARNING" 0 "NO_WARNING" ;
VAL_ 782 PARK_sensorType 3 "SNA" 2 "VALEO_HP" 1 "VALEO_HPFL" 0 "NONE" ;
VAL_ 894 PARK_matrixIndex 1 "AlertMatrix1" 0 "AlertMatrix0" ;
VAL_ 1365 RADC_alertID 55 "a055_blockageInfo_Frame_2" 54 "a054_blockageInfo_Frame_1" 53 "a053_emError" 52 "a052_mismatcRadPos" 51 "a051_mismatchEPASType" 50 "a050_mismatchCountry" 49 "a049_mismatchFourWheelDrive" 48 "a048_mismatchAirSuspension" 47 "a047_mismatchChassisType" 46 "a046_wheelSpeedsErr" 45 "a045_vehicleStateErr" 44 "a044_steeringWheelAngleErr" 43 "a043_inertialSignalsErr" 42 "a042_carConfigErr" 41 "a041_vinErr" 40 "a040_wheelSpeedsMIA" 39 "a039_vehicleStateMIA" 38 "a038_steeringWheelAngleMIA" 37 "a037_inertialSignalsMIA" 36 "a036_carConfigMIA" 35 "a035_vinMIA" 34 "a034_vehDynamicsError" 33 "a033_sensorNeverAligned" 32 "a032_sensorBlocked" 31 "a031_sensorMisaligned" 30 "a030_rspError" 29 "a029_rhcError" 28 "a028_rfChipError" 27 "a027_nvmFailure" 26 "a026_underVoltage" 25 "a025_overVoltage" 24 "a024_underTempCrit" 23 "a023_underTemp" 22 "a022_tempImplausible" 21 "a021_overTempCrit" 20 "a020_overTemp" 19 "a019_internalSoftwareFault" 18 "a018_internalHardwareFault" 17 "a017_adcUnderVolt" 16 "a016_adcOverVolt" 15 "a015_fctSenInterference" 14 "a014_fctSelfTestNotDone" 13 "a013_ecuWdgError" 12 "a012_ecuSpiError" 11 "a011_ecuMcemError" 10 "a010_ecuIoHwAbError" 9 "a009_plantModeActive" 8 "a008_ecuHwSwInterlock" 7 "a007_ecuGptCheckError" 6 "a006_ecuFimError" 5 "a005_ecuEcuMError" 4 "a004_ecuCrcHwError" 3 "a003_ecuBistDisabled" 2 "a002_ecuAdcError" 1 "a001_can1BusOff" 0 "ALERT_DO_NOT_USE_ZERO" ;
VAL_ 1365 RADC_alertState 1 "SET" 0 "CLEARED" ;
VAL_ 1365 RADC_a002_ecuAdcErrType 1 "INVALID_CONV_MODE" 0 "LIMIT_RANGE" ;
VAL_ 1365 RADC_a008_interLockErrType 1 "SW_VERSION_MISMATCH" 0 "HW_SW_PROJECT_ID_INCOMPATIBLE" ;
VAL_ 1365 RADC_a011_ecuMcemErrType 10 "MCEM__ALARM_ISR" 9 "MCEM_E_CORRUPTED_HW_CONFIG" 8 "MCEM_E_FAULT" 7 "MCEM_E_FORBIDDEN_INVOCATION" 6 "MCEM_E_INIT_FAILED" 5 "MCEM_E_OPERATION_FAILED" 4 "MCU_E_CLOCK_FAILURE" 3 "MCU_E_MCME_PERIODIC_CHECK" 2 "MCU_E_MCPCU_PERIODIC_CHECK" 1 "MCU_E_MCRGM_PERIODIC_CHECK" 0 "MCU_E_QUARTZ_FAILURE" ;
VAL_ 1365 RADC_a013_ecuWdgErrType 3 "CORRUPT_CONFIG" 2 "DISABLE_REJECTED" 1 "INVALID_CALL" 0 "UNLOCKED" ;
VAL_ 1365 RADC_a016_adcOverVoltType 7 "5V_SMPS_OVER_VOLTAGE" 6 "4V5_LIN_VOLTAGECO_OVER_VOLTAGE" 5 "3V8_SMPS_OVER_VOLTAGE" 4 "3V3_LIN_ANALOG_OVER_VOLTAGE" 3 "3V3_LIN_DIGITAL_OVER_VOLTAGE" 2 "3V3_LIN_PA_OVER_VOLTAGE" 1 "3V3_LIN_VOLTAGECO_OVER_VOLTAGE" 0 "1V25_SMPS_OVER_VOLTAGE" ;
VAL_ 1365 RADC_a017_adcUnderVoltType 7 "5V_SMPS_UNDER_VOLTAGE" 6 "4V5_LIN_VOLTAGECO_UNDER_VOLTAGE" 5 "3V8_SMPS_UNDER_VOLTAGE" 4 "3V3_LIN_ANALOG_UNDER_VOLTAGE" 3 "3V3_LIN_DIGITAL_UNDER_VOLTAGE" 2 "3V3_LIN_PA_UNDER_VOLTAGE" 1 "3V3_LIN_VOLTAGECO_UNDER_VOLTAGE" 0 "1V25_SMPS_UNDER_VOLTAGE" ;
VAL_ 1365 RADC_a019_internalSWFaultType 110 "ADC_CALIBRATION" 109 "PROCESSOR_VERSION" 108 "FLASH_CYCLIC_CHECK" 107 "INTERNAL_VOLTAGE_FAILED" 106 "ATIC_RESET" 105 "LBIST_FAILED" 104 "MBIST_FAILED" 103 "STARTUP_ERROR" 102 "TEMP_CROSS_CHECK" 101 "ECC_INIT_FAILED" 100 "RADAR_CYCLE_VIOLATION" 99 "FLSP_INIT_FAILED" 98 "POWERUP_SEQ_TIMEOUT" 97 "IOHWAB_TIMEOUT" 96 "UBATT_OUT_OF_RANGE" 95 "EXCEPT_RESERVED_15" 94 "EXCEPT_RESERVED_14" 93 "EXCEPT_RESERVED_13" 92 "EXCEPT_TRAP" 91 "EXCEPT_CENTRAL" 90 "FCCU_HEALED_FAULT" 89 "FCCU_CHECKER_MISMATCH" 88 "PLL_STUCK" 87 "ECUM_REQUEST" 86 "SPI_ATIC_FAULT" 85 "SPI_MMIC_MISMATCH" 84 "SPI_MMIC_FAULT" 83 "ECC_OTHER_2BIT" 82 "ECC_CORE_ICACHE_2BIT" 81 "ECC_CORE_DCACHE_2BIT" 80 "ECC_CORE_IMEM_2BIT" 79 "ECC_CORE_DMEM_2BIT" 78 "ECC_EEPROM_2BIT" 77 "ECC_FLASH_2BIT" 76 "ECC_SRAM_2BIT" 75 "SMPU" 74 "IOHWAB" 73 "ECC_PATTERN_MISSING" 72 "WATCHDOG" 71 "WATCHDOG_INITIALIZATION" 70 "CLKMON_CALIBRATION" 69 "CLKMON_CONFIG_CHECK" 68 "CLKMON_INITIALIZATION" 67 "FCCU_FAULT_SIGNALED" 66 "FCCU_CORRUPTED_CONFIG" 65 "HW_SW_INCOMPATIBLE" 64 "SPE_CHECK" 63 "FPU_CHECK" 62 "ECC_SPT_2BIT" 61 "ECC_DMA_2BIT" 60 "ECC_HARDWARE_FAILURE" 59 "DRIVERINIT_FAILED" 58 "CORE2_STACK_OVERFLOW" 57 "CORE1_STACK_OVERFLOW" 56 "NVM_TIMEOUT" 55 "EXCEPT_ECC2BITERROR" 54 "EXCEPT_ECC1BITERROR" 53 "EXCEPT_DECREMENTER" 52 "EXCEPT_AP_UNAVAILABLE" 51 "EXCEPT_SYSTEM_CALL" 50 "E_FLOATINGPOINT_UNAVAIL" 49 "FCCU" 48 "INTENTIONAL_RESET" 47 "CYCLE_MON" 46 "TESTCASE_CONFIG" 45 "TESTCASE_ABORT" 44 "EXCEPT_CORE_FREEZE" 43 "INVALID_SAFESECTION" 42 "BUS_TEST" 41 "UNEXPECTED_RESET" 40 "ALU_CHECK" 39 "MISC_CHECK" 38 "APPL_CRC_CHECK" 37 "CONFIG_REGISTER_CHECK" 36 "CPU_REGISTER_CHECK" 35 "TPU_RAM_ADDRESS_BUS1" 34 "TPU_RAM_ADDRESS_BUS0" 33 "SRAM_ADDRESS_BUS1" 32 "SRAM_ADDRESS_BUS0" 31 "ECC_TIMEOUT" 30 "DCACHE_MARCHC" 29 "AD_CONVERTER" 28 "TASK_STACK" 27 "TASK_MON_LOGIC" 26 "SYSTEM_CYCLE_MON" 25 "EXCEPT_UNDEFINED" 24 "EXCEPT_ERROR_TPU_RAM" 23 "EXCEPT_ERROR_SRAM" 22 "EXCEPT_SHUTDOWN_OS" 21 "EXCEPT_EFP_ROUND" 20 "EXCEPT_EFP_DATA" 19 "EXCEPT_SPE_UNAVAIL" 18 "EXCEPT_INSTR_TLB_ERROR" 17 "EXCEPT_DATA_TLB_ERROR" 16 "EXCEPT_WATCHDOG_TIMER" 15 "EXCEPT_FIXED_INTER" 14 "EXCEPT_DEBUG" 13 "EXCEPT_PERFORMANCEMON" 12 "EXCEPT_PROGRAM" 11 "EXCEPT_ALIGN" 10 "EXCEPT_INSTRUCT_STORE" 9 "EXCEPT_DATA_STORE" 8 "EXCEPT_MACH_CHECK" 7 "EXCEPT_CRIT_INPUT" 6 "ROM_ECC_2BIT" 5 "RAM_ECC_2BIT" 4 "ROM_ECC_1BIT" 3 "RAM_ECC_1BIT" 2 "MCU_SUPPLY" 1 "TEMP_MON" 0 "NONE" ;
VAL_ 1365 RADC_a019_internalSWFaultCoreID 2 "2" 1 "1" 0 "0" ;
VAL_ 1365 RADC_a027_nvmFailureType 2 "INTEGRITY_FAILED" 1 "REQ_FAILED" 0 "RECORD_SIZE_MISSMATCH" ;
VAL_ 1365 RADC_a028_rfComRegCheckFail 4 "MON_RF_OVERTEMP" 3 "MON_RF_CHIP_TEMP_IMPLAUSIBLE" 2 "REG_CHECK_FAILED_LT" 1 "REG_CHECK_FAILED" 0 "REG_CHECK_CYCLE_FAILED" ;
VAL_ 1365 RADC_a029_rhcChirpMonErrType 2 "RG_LENGTH_ERROR_NS" 1 "RMSE_TOO_LARGE_NS" 0 "FREQ_ERROR_SPEC_TOO_LARGE_NS" ;
VAL_ 1365 RADC_a029_rhcRxLongTermErrType 6 "NOISE_POWER_TOO_HIGH_LT" 5 "SPURIOUS_PEAKS_TOO_HIGH_LT" 4 "SIGNAL_POWER_TOO_LOW_LT" 3 "TRANSFER_FUNCTION_ERR_LT" 2 "CHANNEL_VARIATION_ERR_LT" 1 "STC_FILTER_ERR_LT" 0 "NONLINEAR_ERR_LT" ;
VAL_ 1365 RADC_a029_rhcRxErrType 7 "RX_SPURIOUS_PEAKS_TOO_HIGH" 6 "LOAD_PULLING_TOO_HIGH_NS" 5 "RX_NOISE_POWER_TOO_HIGH" 4 "RX_SIGNAL_POWER_TOO_LOW" 3 "RX_TRANSFER_FUNCTION_ERR" 2 "RX_CHANNEL_VARIATION_ERR" 1 "RX_STC_FILTER_ERR" 0 "RX_NONLINEAR_ERR" ;
VAL_ 1365 RADC_a029_rhcVcoPowerErrType 1 "LOW" 0 "HIGH" ;
VAL_ 1365 RADC_a029_rhcSp1ErrType 0 "RHC_CTE_LUT_DUR_STUCK_ERR" ;
VAL_ 1365 RADC_a029_rhcFdcErrType 2 "LONG_TERM_ERROR_NS" 1 "RMSE_TOO_LARGE_NS" 0 "DRIFT_FREQ_TOO_LARGE_NS" ;
VAL_ 1365 RADC_a030_rspErrType 1 "LONG_TERM_ERROR" 0 "SHORT_TERM_ERROR" ;
VAL_ 1365 RADC_a032_blockageType 4 "FCTSEN_OBJ_NOT_MEASURED" 3 "FCTSEN_BLOCKAGE" 2 "FCTSEN_DEC_BLOCKAGE" 1 "FCTSEN_INC_BLOCKAGE" 0 "ALN_PATH_COMP_HIGH_NEAR" ;
VAL_ 1365 RADC_a032_block_SPMBlockageState 4 "GDB_UNKNOWN_DAMP" 3 "GDB_RDC_DAMP" 2 "GDB_FULL_DAMP" 1 "GDB_INC_DAMP" 0 "DB_NO_DAMP" ;
VAL_ 1365 RADC_a032_block_SPMSelfTestState 3 "ROADBEAM_TEST" 2 "STARTUP" 1 "ON" 0 "OFF" ;
VAL_ 1365 RADC_a041_vinErrType 5 "OVERRUN" 4 "INVALID_DATA" 3 "SEQUENCE" 2 "CHECKSUM" 1 "LENGTH" 0 "NONE" ;
VAL_ 1365 RADC_a042_carConfigErrType 5 "OVERRUN" 4 "INVALID_DATA" 3 "SEQUENCE" 2 "CHECKSUM" 1 "LENGTH" 0 "NONE" ;
VAL_ 1365 RADC_a043_inertialSignalsErrType 5 "OVERRUN" 4 "INVALID_DATA" 3 "SEQUENCE" 2 "CHECKSUM" 1 "LENGTH" 0 "NONE" ;
VAL_ 1365 RADC_a044_stwAngleErrType 5 "OVERRUN" 4 "INVALID_DATA" 3 "SEQUENCE" 2 "CHECKSUM" 1 "LENGTH" 0 "NONE" ;
VAL_ 1365 RADC_a045_vehicleStateErrType 5 "OVERRUN" 4 "INVALID_DATA" 3 "SEQUENCE" 2 "CHECKSUM" 1 "LENGTH" 0 "NONE" ;
VAL_ 1365 RADC_a046_wheelSpeedsErrType 5 "OVERRUN" 4 "INVALID_DATA" 3 "SEQUENCE" 2 "CHECKSUM" 1 "LENGTH" 0 "NONE" ;
VAL_ 1365 RADC_a047_chassisTypeExp 7 "SNA" 2 "MODEL_3_CHASSIS" 1 "MODEL_X_CHASSIS" 0 "MODEL_S_CHASSIS" ;
VAL_ 1365 RADC_a047_chassisTypeRx 7 "SNA" 2 "MODEL_3_CHASSIS" 1 "MODEL_X_CHASSIS" 0 "MODEL_S_CHASSIS" ;
VAL_ 1365 RADC_a048_airSuspensionExp 7 "SNA" 5 "TESLA_ADAPTIVE" 4 "TESLA_PLUS" 3 "TESLA_STANDARD" 2 "PLUS" 1 "STANDARD" 0 "NONE" ;
VAL_ 1365 RADC_a048_airSuspensionRx 7 "SNA" 5 "TESLA_ADAPTIVE" 4 "TESLA_PLUS" 3 "TESLA_STANDARD" 2 "PLUS" 1 "STANDARD" 0 "NONE" ;
VAL_ 1365 RADC_a049_fourWheelDriveExp 3 "SNA" 2 "UNUSED" 1 "4WD" 0 "2WD" ;
VAL_ 1365 RADC_a049_fourWheelDriveRx 3 "SNA" 2 "UNUSED" 1 "4WD" 0 "2WD" ;
VAL_ 1365 RADC_a051_epasTypeExp 7 "SNA" 4 "MANDO_VGR63_GEN3" 3 "MANDO_VGR66" 2 "MANDO_FGR64" 1 "BOSCH_L405" 0 "BOSCH_L538" ;
VAL_ 1365 RADC_a051_epasTypeRx 7 "SNA" 4 "MANDO_VGR63_GEN3" 3 "MANDO_VGR66" 2 "MANDO_FGR64" 1 "BOSCH_L405" 0 "BOSCH_L538" ;
VAL_ 1365 RADC_a052_radarPositionExp 7 "SNA" 3 "MODEL_3" 2 "MODELX" 1 "MODELS_2" 0 "MODELS" ;
VAL_ 1365 RADC_a052_radarPositionRx 7 "SNA" 3 "MODEL_3" 2 "MODELX" 1 "MODELS_2" 0 "MODELS" ;
VAL_ 1329 RADC_infoIndex 20 "Mux20" 19 "Mux19" 13 "Mux13" 11 "Mux11" 10 "Mux10" ;
VAL_ 1329 RADC_infoBuildType 4 "INFO_MFG_BUILD" 3 "INFO_TRACEABLE_CI_BUILD" 2 "INFO_LOCAL_BUILD" 1 "INFO_PLATFORM_BUILD" 0 "INFO_UNKNOWN_BUILD" ;
